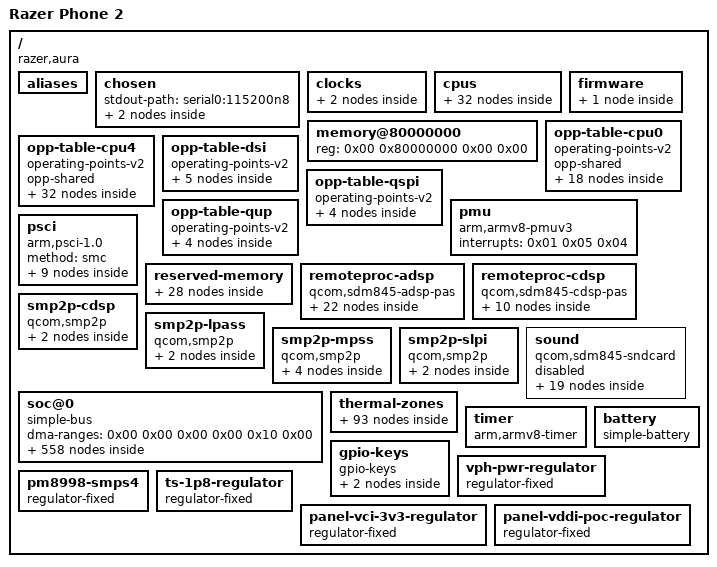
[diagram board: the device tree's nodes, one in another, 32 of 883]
/dts-v1/;

/ {
	interrupt-parent = <0x01>;
	#address-cells = <0x02>;
	#size-cells = <0x02>;
	model = "Razer Phone 2";
	compatible = "razer,aura\0qcom,sdm845";
	chassis-type = "handset";
	qcom,msm-id = <0x141 0x20000>;
	qcom,board-id = <0x00 0x00>;

	aliases {
		i2c0 = "/soc@0/geniqup@8c0000/i2c@880000";
		i2c1 = "/soc@0/geniqup@8c0000/i2c@884000";
		i2c2 = "/soc@0/geniqup@8c0000/i2c@888000";
		i2c3 = "/soc@0/geniqup@8c0000/i2c@88c000";
		i2c4 = "/soc@0/geniqup@8c0000/i2c@890000";
		i2c5 = "/soc@0/geniqup@8c0000/i2c@894000";
		i2c6 = "/soc@0/geniqup@8c0000/i2c@898000";
		i2c7 = "/soc@0/geniqup@8c0000/i2c@89c000";
		i2c8 = "/soc@0/geniqup@ac0000/i2c@a80000";
		i2c9 = "/soc@0/geniqup@ac0000/i2c@a84000";
		i2c10 = "/soc@0/geniqup@ac0000/i2c@a88000";
		i2c11 = "/soc@0/geniqup@ac0000/i2c@a8c000";
		i2c12 = "/soc@0/geniqup@ac0000/i2c@a90000";
		i2c13 = "/soc@0/geniqup@ac0000/i2c@a94000";
		i2c14 = "/soc@0/geniqup@ac0000/i2c@a98000";
		i2c15 = "/soc@0/geniqup@ac0000/i2c@a9c000";
		spi0 = "/soc@0/geniqup@8c0000/spi@880000";
		spi1 = "/soc@0/geniqup@8c0000/spi@884000";
		spi2 = "/soc@0/geniqup@8c0000/spi@888000";
		spi3 = "/soc@0/geniqup@8c0000/spi@88c000";
		spi4 = "/soc@0/geniqup@8c0000/spi@890000";
		spi5 = "/soc@0/geniqup@8c0000/spi@894000";
		spi6 = "/soc@0/geniqup@8c0000/spi@898000";
		spi7 = "/soc@0/geniqup@8c0000/spi@89c000";
		spi8 = "/soc@0/geniqup@ac0000/spi@a80000";
		spi9 = "/soc@0/geniqup@ac0000/spi@a84000";
		spi10 = "/soc@0/geniqup@ac0000/spi@a88000";
		spi11 = "/soc@0/geniqup@ac0000/spi@a8c000";
		spi12 = "/soc@0/geniqup@ac0000/spi@a90000";
		spi13 = "/soc@0/geniqup@ac0000/spi@a94000";
		spi14 = "/soc@0/geniqup@ac0000/spi@a98000";
		spi15 = "/soc@0/geniqup@ac0000/spi@a9c000";
		serial0 = "/soc@0/geniqup@ac0000/serial@a84000";
		serial1 = "/soc@0/geniqup@8c0000/serial@898000";
	};

	chosen {
		#address-cells = <0x02>;
		#size-cells = <0x02>;
		ranges;
		stdout-path = "serial0:115200n8";

		framebuffer@9d400000 {
			compatible = "simple-framebuffer";
			reg = <0x00 0x9d400000 0x00 0xf00000>;
			width = <0x5a0>;
			height = <0xa00>;
			stride = <0x1680>;
			format = "a8r8g8b8";
			panel = <0x02>;

			fb-panel {
				width-mm = <0x47>;
				height-mm = <0x7e>;
				phandle = <0x02>;
			};
		};
	};

	clocks {

		xo-board {
			compatible = "fixed-clock";
			#clock-cells = <0x00>;
			clock-frequency = <0x249f000>;
			clock-output-names = "xo_board";
			phandle = <0xf2>;
		};

		sleep-clk {
			compatible = "fixed-clock";
			#clock-cells = <0x00>;
			clock-frequency = <0x7ffc>;
			phandle = <0x36>;
		};
	};

	cpus {
		#address-cells = <0x02>;
		#size-cells = <0x00>;

		cpu@0 {
			device_type = "cpu";
			compatible = "qcom,kryo385";
			reg = <0x00 0x00>;
			clocks = <0x03 0x00>;
			enable-method = "psci";
			capacity-dmips-mhz = <0x263>;
			dynamic-power-coefficient = <0x9a>;
			qcom,freq-domain = <0x03 0x00>;
			operating-points-v2 = <0x04>;
			interconnects = <0x05 0x00 0x03 0x06 0x0e 0x03 0x07 0x00 0x07 0x01>;
			power-domains = <0x08>;
			power-domain-names = "psci";
			#cooling-cells = <0x02>;
			next-level-cache = <0x09>;
			phandle = <0x1a>;

			l2-cache {
				compatible = "cache";
				cache-level = <0x02>;
				cache-unified;
				next-level-cache = <0x0a>;
				phandle = <0x09>;

				l3-cache {
					compatible = "cache";
					cache-level = <0x03>;
					cache-unified;
					phandle = <0x0a>;
				};
			};
		};

		cpu@100 {
			device_type = "cpu";
			compatible = "qcom,kryo385";
			reg = <0x00 0x100>;
			clocks = <0x03 0x00>;
			enable-method = "psci";
			capacity-dmips-mhz = <0x263>;
			dynamic-power-coefficient = <0x9a>;
			qcom,freq-domain = <0x03 0x00>;
			operating-points-v2 = <0x04>;
			interconnects = <0x05 0x00 0x03 0x06 0x0e 0x03 0x07 0x00 0x07 0x01>;
			power-domains = <0x0b>;
			power-domain-names = "psci";
			#cooling-cells = <0x02>;
			next-level-cache = <0x0c>;
			phandle = <0x1b>;

			l2-cache {
				compatible = "cache";
				cache-level = <0x02>;
				cache-unified;
				next-level-cache = <0x0a>;
				phandle = <0x0c>;
			};
		};

		cpu@200 {
			device_type = "cpu";
			compatible = "qcom,kryo385";
			reg = <0x00 0x200>;
			clocks = <0x03 0x00>;
			enable-method = "psci";
			capacity-dmips-mhz = <0x263>;
			dynamic-power-coefficient = <0x9a>;
			qcom,freq-domain = <0x03 0x00>;
			operating-points-v2 = <0x04>;
			interconnects = <0x05 0x00 0x03 0x06 0x0e 0x03 0x07 0x00 0x07 0x01>;
			power-domains = <0x0d>;
			power-domain-names = "psci";
			#cooling-cells = <0x02>;
			next-level-cache = <0x0e>;
			phandle = <0x1c>;

			l2-cache {
				compatible = "cache";
				cache-level = <0x02>;
				cache-unified;
				next-level-cache = <0x0a>;
				phandle = <0x0e>;
			};
		};

		cpu@300 {
			device_type = "cpu";
			compatible = "qcom,kryo385";
			reg = <0x00 0x300>;
			clocks = <0x03 0x00>;
			enable-method = "psci";
			capacity-dmips-mhz = <0x263>;
			dynamic-power-coefficient = <0x9a>;
			qcom,freq-domain = <0x03 0x00>;
			operating-points-v2 = <0x04>;
			interconnects = <0x05 0x00 0x03 0x06 0x0e 0x03 0x07 0x00 0x07 0x01>;
			#cooling-cells = <0x02>;
			power-domains = <0x0f>;
			power-domain-names = "psci";
			next-level-cache = <0x10>;
			phandle = <0x1d>;

			l2-cache {
				compatible = "cache";
				cache-level = <0x02>;
				cache-unified;
				next-level-cache = <0x0a>;
				phandle = <0x10>;
			};
		};

		cpu@400 {
			device_type = "cpu";
			compatible = "qcom,kryo385";
			reg = <0x00 0x400>;
			clocks = <0x03 0x01>;
			enable-method = "psci";
			capacity-dmips-mhz = <0x400>;
			dynamic-power-coefficient = <0x1ba>;
			qcom,freq-domain = <0x03 0x01>;
			operating-points-v2 = <0x11>;
			interconnects = <0x05 0x00 0x03 0x06 0x0e 0x03 0x07 0x00 0x07 0x01>;
			power-domains = <0x12>;
			power-domain-names = "psci";
			#cooling-cells = <0x02>;
			next-level-cache = <0x13>;
			phandle = <0x1e>;

			l2-cache {
				compatible = "cache";
				cache-level = <0x02>;
				cache-unified;
				next-level-cache = <0x0a>;
				phandle = <0x13>;
			};
		};

		cpu@500 {
			device_type = "cpu";
			compatible = "qcom,kryo385";
			reg = <0x00 0x500>;
			clocks = <0x03 0x01>;
			enable-method = "psci";
			capacity-dmips-mhz = <0x400>;
			dynamic-power-coefficient = <0x1ba>;
			qcom,freq-domain = <0x03 0x01>;
			operating-points-v2 = <0x11>;
			interconnects = <0x05 0x00 0x03 0x06 0x0e 0x03 0x07 0x00 0x07 0x01>;
			power-domains = <0x14>;
			power-domain-names = "psci";
			#cooling-cells = <0x02>;
			next-level-cache = <0x15>;
			phandle = <0x1f>;

			l2-cache {
				compatible = "cache";
				cache-level = <0x02>;
				cache-unified;
				next-level-cache = <0x0a>;
				phandle = <0x15>;
			};
		};

		cpu@600 {
			device_type = "cpu";
			compatible = "qcom,kryo385";
			reg = <0x00 0x600>;
			clocks = <0x03 0x01>;
			enable-method = "psci";
			capacity-dmips-mhz = <0x400>;
			dynamic-power-coefficient = <0x1ba>;
			qcom,freq-domain = <0x03 0x01>;
			operating-points-v2 = <0x11>;
			interconnects = <0x05 0x00 0x03 0x06 0x0e 0x03 0x07 0x00 0x07 0x01>;
			power-domains = <0x16>;
			power-domain-names = "psci";
			#cooling-cells = <0x02>;
			next-level-cache = <0x17>;
			phandle = <0x20>;

			l2-cache {
				compatible = "cache";
				cache-level = <0x02>;
				cache-unified;
				next-level-cache = <0x0a>;
				phandle = <0x17>;
			};
		};

		cpu@700 {
			device_type = "cpu";
			compatible = "qcom,kryo385";
			reg = <0x00 0x700>;
			clocks = <0x03 0x01>;
			enable-method = "psci";
			capacity-dmips-mhz = <0x400>;
			dynamic-power-coefficient = <0x1ba>;
			qcom,freq-domain = <0x03 0x01>;
			operating-points-v2 = <0x11>;
			interconnects = <0x05 0x00 0x03 0x06 0x0e 0x03 0x07 0x00 0x07 0x01>;
			power-domains = <0x18>;
			power-domain-names = "psci";
			#cooling-cells = <0x02>;
			next-level-cache = <0x19>;
			phandle = <0x21>;

			l2-cache {
				compatible = "cache";
				cache-level = <0x02>;
				cache-unified;
				next-level-cache = <0x0a>;
				phandle = <0x19>;
			};
		};

		cpu-map {

			cluster0 {

				core0 {
					cpu = <0x1a>;
				};

				core1 {
					cpu = <0x1b>;
				};

				core2 {
					cpu = <0x1c>;
				};

				core3 {
					cpu = <0x1d>;
				};

				core4 {
					cpu = <0x1e>;
				};

				core5 {
					cpu = <0x1f>;
				};

				core6 {
					cpu = <0x20>;
				};

				core7 {
					cpu = <0x21>;
				};
			};
		};

		idle-states {
			entry-method = "psci";

			cpu-sleep-0-0 {
				compatible = "arm,idle-state";
				idle-state-name = "little-rail-power-collapse";
				arm,psci-suspend-param = <0x40000004>;
				entry-latency-us = <0x15e>;
				exit-latency-us = <0x1cd>;
				min-residency-us = <0x762>;
				local-timer-stop;
				phandle = <0x28>;
			};

			cpu-sleep-1-0 {
				compatible = "arm,idle-state";
				idle-state-name = "big-rail-power-collapse";
				arm,psci-suspend-param = <0x40000004>;
				entry-latency-us = <0x108>;
				exit-latency-us = <0x26d>;
				min-residency-us = <0x3b8>;
				local-timer-stop;
				phandle = <0x29>;
			};
		};

		domain-idle-states {

			cluster-sleep-0 {
				compatible = "domain-idle-state";
				arm,psci-suspend-param = <0x4100c244>;
				entry-latency-us = <0xcbf>;
				exit-latency-us = <0x19a2>;
				min-residency-us = <0x2703>;
				phandle = <0x2a>;
			};
		};
	};

	firmware {

		scm {
			compatible = "qcom,scm-sdm845\0qcom,scm";
		};
	};

	memory@80000000 {
		device_type = "memory";
		reg = <0x00 0x80000000 0x00 0x00>;
	};

	opp-table-cpu0 {
		compatible = "operating-points-v2";
		opp-shared;
		phandle = <0x04>;

		opp-300000000 {
			opp-hz = <0x00 0x11e1a300>;
			opp-peak-kBps = "\0\f5\0\0I>";
		};

		opp-403200000 {
			opp-hz = <0x00 0x18085800>;
			opp-peak-kBps = "\0\f5\0\0I>";
		};

		opp-480000000 {
			opp-hz = <0x00 0x1c9c3800>;
			opp-peak-kBps = "\0\f5\0\0bp";
		};

		opp-576000000 {
			opp-hz = <0x00 0x22551000>;
			opp-peak-kBps = "\0\f5\0\0bp";
		};

		opp-652800000 {
			opp-hz = <0x00 0x26e8f000>;
			opp-peak-kBps = "\0\f5\0\0u0";
		};

		opp-748800000 {
			opp-hz = <0x00 0x2ca1c800>;
			opp-peak-kBps = <0x1b86e0 0x8ca000>;
		};

		opp-825600000 {
			opp-hz = <0x00 0x3135a800>;
			opp-peak-kBps = <0x1b86e0 0x8ca000>;
		};

		opp-902400000 {
			opp-hz = <0x00 0x35c98800>;
			opp-peak-kBps = <0x1b86e0 0x9f6000>;
		};

		opp-979200000 {
			opp-hz = <0x00 0x3a5d6800>;
			opp-peak-kBps = <0x1b86e0 0xb6d000>;
		};

		opp-1056000000 {
			opp-hz = <0x00 0x3ef14800>;
			opp-peak-kBps = <0x1b86e0 0xb6d000>;
		};

		opp-1132800000 {
			opp-hz = <0x00 0x43852800>;
			opp-peak-kBps = <0x2162e0 0xce4000>;
		};

		opp-1228800000 {
			opp-hz = <0x00 0x493e0000>;
			opp-peak-kBps = <0x2162e0 0xe5b000>;
		};

		opp-1324800000 {
			opp-hz = <0x00 0x4ef6d800>;
			opp-peak-kBps = <0x2162e0 0xfd2000>;
		};

		opp-1420800000 {
			opp-hz = <0x00 0x54afb000>;
			opp-peak-kBps = <0x2ee000 0x1149000>;
		};

		opp-1516800000 {
			opp-hz = <0x00 0x5a688800>;
			opp-peak-kBps = <0x2ee000 0x1275000>;
		};

		opp-1612800000 {
			opp-hz = <0x00 0x60216000>;
			opp-peak-kBps = <0x3e12a0 0x1275000>;
		};

		opp-1689600000 {
			opp-hz = <0x00 0x64b54000>;
			opp-peak-kBps = <0x3e12a0 0x13ec000>;
		};

		opp-1766400000 {
			opp-hz = <0x00 0x69492000>;
			opp-peak-kBps = <0x3e12a0 0x1563000>;
		};
	};

	opp-table-cpu4 {
		compatible = "operating-points-v2";
		opp-shared;
		phandle = <0x11>;

		opp-300000000 {
			opp-hz = <0x00 0x11e1a300>;
			opp-peak-kBps = "\0\f5\0\0I>";
		};

		opp-403200000 {
			opp-hz = <0x00 0x18085800>;
			opp-peak-kBps = "\0\f5\0\0I>";
		};

		opp-480000000 {
			opp-hz = <0x00 0x1c9c3800>;
			opp-peak-kBps = <0x1b86e0 0x493e00>;
		};

		opp-576000000 {
			opp-hz = <0x00 0x22551000>;
			opp-peak-kBps = <0x1b86e0 0x493e00>;
		};

		opp-652800000 {
			opp-hz = <0x00 0x26e8f000>;
			opp-peak-kBps = <0x1b86e0 0x493e00>;
		};

		opp-748800000 {
			opp-hz = <0x00 0x2ca1c800>;
			opp-peak-kBps = <0x1b86e0 0x493e00>;
		};

		opp-825600000 {
			opp-hz = <0x00 0x3135a800>;
			opp-peak-kBps = <0x2162e0 0x8ca000>;
		};

		opp-902400000 {
			opp-hz = <0x00 0x35c98800>;
			opp-peak-kBps = <0x2162e0 0x8ca000>;
		};

		opp-979200000 {
			opp-hz = <0x00 0x3a5d6800>;
			opp-peak-kBps = <0x2162e0 0x8ca000>;
		};

		opp-1056000000 {
			opp-hz = <0x00 0x3ef14800>;
			opp-peak-kBps = <0x2ee000 0x8ca000>;
		};

		opp-1132800000 {
			opp-hz = <0x00 0x43852800>;
			opp-peak-kBps = <0x2ee000 0xb6d000>;
		};

		opp-1209600000 {
			opp-hz = <0x00 0x48190800>;
			opp-peak-kBps = <0x3e12a0 0xb6d000>;
		};

		opp-1286400000 {
			opp-hz = <0x00 0x4cace800>;
			opp-peak-kBps = <0x3e12a0 0xb6d000>;
		};

		opp-1363200000 {
			opp-hz = <0x00 0x5140c800>;
			opp-peak-kBps = <0x3e12a0 0xe5b000>;
		};

		opp-1459200000 {
			opp-hz = <0x00 0x56f9a000>;
			opp-peak-kBps = <0x3e12a0 0xe5b000>;
		};

		opp-1536000000 {
			opp-hz = <0x00 0x5b8d8000>;
			opp-peak-kBps = <0x5294a0 0xe5b000>;
		};

		opp-1612800000 {
			opp-hz = <0x00 0x60216000>;
			opp-peak-kBps = <0x5294a0 0xe5b000>;
		};

		opp-1689600000 {
			opp-hz = <0x00 0x64b54000>;
			opp-peak-kBps = <0x5294a0 0x1275000>;
		};

		opp-1766400000 {
			opp-hz = <0x00 0x69492000>;
			opp-peak-kBps = <0x5ee8e0 0x1275000>;
		};

		opp-1843200000 {
			opp-hz = <0x00 0x6ddd0000>;
			opp-peak-kBps = <0x5ee8e0 0x1275000>;
		};

		opp-1920000000 {
			opp-hz = <0x00 0x7270e000>;
			opp-peak-kBps = <0x6e1b80 0x1275000>;
		};

		opp-1996800000 {
			opp-hz = <0x00 0x7704c000>;
			opp-peak-kBps = <0x6e1b80 0x13ec000>;
		};

		opp-2092800000 {
			opp-hz = <0x00 0x7cbd9800>;
			opp-peak-kBps = <0x6e1b80 0x13ec000>;
		};

		opp-2169600000 {
			opp-hz = <0x00 0x81517800>;
			opp-peak-kBps = <0x6e1b80 0x13ec000>;
		};

		opp-2246400000 {
			opp-hz = <0x00 0x85e55800>;
			opp-peak-kBps = <0x6e1b80 0x13ec000>;
		};

		opp-2323200000 {
			opp-hz = <0x00 0x8a793800>;
			opp-peak-kBps = <0x6e1b80 0x13ec000>;
		};

		opp-2400000000 {
			opp-hz = <0x00 0x8f0d1800>;
			opp-peak-kBps = <0x6e1b80 0x1563000>;
		};

		opp-2476800000 {
			opp-hz = <0x00 0x93a0f800>;
			opp-peak-kBps = <0x6e1b80 0x1563000>;
		};

		opp-2553600000 {
			opp-hz = <0x00 0x9834d800>;
			opp-peak-kBps = <0x6e1b80 0x1563000>;
		};

		opp-2649600000 {
			opp-hz = <0x00 0x9dedb000>;
			opp-peak-kBps = <0x6e1b80 0x1563000>;
		};

		opp-2745600000 {
			opp-hz = <0x00 0xa3a68800>;
			opp-peak-kBps = <0x6e1b80 0x1851000>;
		};

		opp-2803200000 {
			opp-hz = <0x00 0xa7157000>;
			opp-peak-kBps = <0x6e1b80 0x1851000>;
		};
	};

	opp-table-dsi {
		compatible = "operating-points-v2";
		phandle = <0xda>;

		opp-19200000 {
			opp-hz = <0x00 0x124f800>;
			required-opps = <0x22>;
		};

		opp-180000000 {
			opp-hz = <0x00 0xaba9500>;
			required-opps = <0x23>;
		};

		opp-275000000 {
			opp-hz = <0x00 0x10642ac0>;
			required-opps = <0x24>;
		};

		opp-328580000 {
			opp-hz = <0x00 0x1395bba0>;
			required-opps = <0x25>;
		};

		opp-358000000 {
			opp-hz = <0x00 0x1556a580>;
			required-opps = <0x26>;
		};
	};

	opp-table-qspi {
		compatible = "operating-points-v2";
		phandle = <0xb5>;

		opp-19200000 {
			opp-hz = <0x00 0x124f800>;
			required-opps = <0x22>;
		};

		opp-100000000 {
			opp-hz = <0x00 0x5f5e100>;
			required-opps = <0x23>;
		};

		opp-150000000 {
			opp-hz = <0x00 0x8f0d180>;
			required-opps = <0x24>;
		};

		opp-300000000 {
			opp-hz = <0x00 0x11e1a300>;
			required-opps = <0x26>;
		};
	};

	opp-table-qup {
		compatible = "operating-points-v2";
		phandle = <0x3e>;

		opp-50000000 {
			opp-hz = <0x00 0x2faf080>;
			required-opps = <0x22>;
		};

		opp-75000000 {
			opp-hz = <0x00 0x47868c0>;
			required-opps = <0x23>;
		};

		opp-100000000 {
			opp-hz = <0x00 0x5f5e100>;
			required-opps = <0x24>;
		};

		opp-128000000 {
			opp-hz = <0x00 0x7a12000>;
			required-opps = <0x26>;
		};
	};

	pmu {
		compatible = "arm,armv8-pmuv3";
		interrupts = <0x01 0x05 0x04>;
	};

	psci {
		compatible = "arm,psci-1.0";
		method = "smc";

		power-domain-cpu0 {
			#power-domain-cells = <0x00>;
			power-domains = <0x27>;
			domain-idle-states = <0x28>;
			phandle = <0x08>;
		};

		power-domain-cpu1 {
			#power-domain-cells = <0x00>;
			power-domains = <0x27>;
			domain-idle-states = <0x28>;
			phandle = <0x0b>;
		};

		power-domain-cpu2 {
			#power-domain-cells = <0x00>;
			power-domains = <0x27>;
			domain-idle-states = <0x28>;
			phandle = <0x0d>;
		};

		power-domain-cpu3 {
			#power-domain-cells = <0x00>;
			power-domains = <0x27>;
			domain-idle-states = <0x28>;
			phandle = <0x0f>;
		};

		power-domain-cpu4 {
			#power-domain-cells = <0x00>;
			power-domains = <0x27>;
			domain-idle-states = <0x29>;
			phandle = <0x12>;
		};

		power-domain-cpu5 {
			#power-domain-cells = <0x00>;
			power-domains = <0x27>;
			domain-idle-states = <0x29>;
			phandle = <0x14>;
		};

		power-domain-cpu6 {
			#power-domain-cells = <0x00>;
			power-domains = <0x27>;
			domain-idle-states = <0x29>;
			phandle = <0x16>;
		};

		power-domain-cpu7 {
			#power-domain-cells = <0x00>;
			power-domains = <0x27>;
			domain-idle-states = <0x29>;
			phandle = <0x18>;
		};

		power-domain-cluster {
			#power-domain-cells = <0x00>;
			domain-idle-states = <0x2a>;
			phandle = <0x27>;
		};
	};

	reserved-memory {
		#address-cells = <0x02>;
		#size-cells = <0x02>;
		ranges;

		hyp-mem@85700000 {
			reg = <0x00 0x85700000 0x00 0x600000>;
			no-map;
		};

		xbl-mem@85e00000 {
			reg = <0x00 0x85e00000 0x00 0x100000>;
			no-map;
		};

		aop-mem@85fc0000 {
			reg = <0x00 0x85fc0000 0x00 0x20000>;
			no-map;
		};

		aop-cmd-db-mem@85fe0000 {
			compatible = "qcom,cmd-db";
			reg = <0x00 0x85fe0000 0x00 0x20000>;
			no-map;
		};

		smem@86000000 {
			compatible = "qcom,smem";
			reg = <0x00 0x86000000 0x00 0x200000>;
			no-map;
			hwlocks = <0x2b 0x03>;
		};

		tz@86200000 {
			reg = <0x00 0x86200000 0x00 0x2d00000>;
			no-map;
		};

		qseecom@8ab00000 {
			reg = <0x00 0x8ab00000 0x00 0x1400000>;
			no-map;
		};

		camera-mem@8bf00000 {
			reg = <0x00 0x8bf00000 0x00 0x500000>;
			no-map;
		};

		ipa-fw@8c400000 {
			reg = <0x00 0x8c400000 0x00 0x10000>;
			no-map;
			phandle = <0x85>;
		};

		ipa-gsi@8c410000 {
			reg = <0x00 0x8c410000 0x00 0x5000>;
			no-map;
		};

		gpu@8c415000 {
			reg = <0x00 0x8c415000 0x00 0x2000>;
			no-map;
		};

		adsp@8c500000 {
			reg = <0x00 0x8c500000 0x00 0x1a00000>;
			no-map;
			phandle = <0x2e>;
		};

		wlan-msa@8df00000 {
			reg = <0x00 0x8df00000 0x00 0x100000>;
			no-map;
			phandle = <0xfb>;
		};

		mpss@8e000000 {
			reg = <0x00 0x8e000000 0x00 0x7800000>;
			no-map;
			phandle = <0x8e>;
		};

		venus@95800000 {
			reg = <0x00 0x95800000 0x00 0x500000>;
			no-map;
			phandle = <0xc7>;
		};

		cdsp@95d00000 {
			reg = <0x00 0x95d00000 0x00 0x800000>;
			no-map;
			phandle = <0x34>;
		};

		mba@96500000 {
			reg = <0x00 0x96500000 0x00 0x200000>;
			no-map;
			phandle = <0x8d>;
		};

		slpi@96700000 {
			reg = <0x00 0x96700000 0x00 0x1400000>;
			no-map;
			phandle = <0x91>;
		};

		spss@97b00000 {
			reg = <0x00 0x97b00000 0x00 0x100000>;
			no-map;
		};

		mpss-metadata {
			alloc-ranges = <0x00 0xa0000000 0x00 0x20000000>;
			size = <0x00 0x4000>;
			no-map;
			phandle = <0x8f>;
		};

		framebuffer@9d400000 {
			reg = <0x00 0x9d400000 0x00 0x2400000>;
			no-map;
		};

		fastrpc {
			compatible = "shared-dma-pool";
			alloc-ranges = <0x00 0x00 0x00 0xffffffff>;
			alignment = <0x00 0x400000>;
			size = <0x00 0x1000000>;
			reusable;
			phandle = <0x93>;
		};

		rmtfs-mem@f5b00000 {
			compatible = "qcom,rmtfs-mem";
			reg = <0x00 0xf5b00000 0x00 0x202000>;
			no-map;
			qcom,client-id = <0x01>;
			qcom,vmid = <0x0f>;
			qcom,use-guard-pages;
		};

		removed-region@88f00000 {
			no-map;
			reg = <0x00 0x88f00000 0x00 0x1c00000>;
		};

		ramoops@ac300000 {
			compatible = "ramoops";
			reg = <0x00 0xac300000 0x00 0x400000>;
			record-size = <0x40000>;
			console-size = <0x40000>;
			ftrace-size = <0x40000>;
			pmsg-size = <0x200000>;
			ecc-size = <0x10>;
		};

		fih-nv@af000000 {
			compatible = "removed-dma-pool";
			no-map;
			reg = <0x00 0xaf000000 0x00 0x800000>;
			phandle = <0x8c>;
		};

		fih-pstore@af800000 {
			compatible = "removed-dma-pool";
			no-map;
			reg = <0x00 0xaf800000 0x00 0x200000>;
		};

		fih@afa00000 {
			compatible = "removed-dma-pool";
			no-map;
			reg = <0x00 0xafa00000 0x00 0x600000>;
		};
	};

	remoteproc-adsp {
		compatible = "qcom,sdm845-adsp-pas";
		interrupts-extended = <0x01 0x00 0xa2 0x01 0x2c 0x00 0x01 0x2c 0x01 0x01 0x2c 0x02 0x01 0x2c 0x03 0x01>;
		interrupt-names = "wdog\0fatal\0ready\0handover\0stop-ack";
		clocks = <0x2d 0x00>;
		clock-names = "xo";
		memory-region = <0x2e>;
		qcom,qmp = <0x2f>;
		qcom,smem-states = <0x30 0x00>;
		qcom,smem-state-names = "stop";
		status = "okay";
		firmware-name = "qcom/sdm845/Razer/aura/adsp.mbn";

		glink-edge {
			interrupts = <0x00 0x9c 0x01>;
			label = "lpass";
			qcom,remote-pid = <0x02>;
			mboxes = <0x31 0x08>;

			apr {
				compatible = "qcom,apr-v2";
				qcom,glink-channels = "apr_audio_svc";
				qcom,domain = <0x04>;
				#address-cells = <0x01>;
				#size-cells = <0x00>;
				qcom,intents = <0x200 0x14>;

				service@3 {
					reg = <0x03>;
					compatible = "qcom,q6core";
					qcom,protection-domain = "avs/audio\0msm/adsp/audio_pd";
				};

				service@4 {
					compatible = "qcom,q6afe";
					reg = <0x04>;
					qcom,protection-domain = "avs/audio\0msm/adsp/audio_pd";

					dais {
						compatible = "qcom,q6afe-dais";
						#address-cells = <0x01>;
						#size-cells = <0x00>;
						#sound-dai-cells = <0x01>;
						phandle = <0x102>;

						dai@22 {
							reg = <0x16>;
							qcom,sd-lines = <0x01>;
						};

						dai@23 {
							reg = <0x17>;
							qcom,sd-lines = <0x00>;
						};
					};
				};

				service@7 {
					compatible = "qcom,q6asm";
					reg = <0x07>;
					qcom,protection-domain = "avs/audio\0msm/adsp/audio_pd";

					dais {
						compatible = "qcom,q6asm-dais";
						#address-cells = <0x01>;
						#size-cells = <0x00>;
						#sound-dai-cells = <0x01>;
						iommus = <0x32 0x1821 0x00>;
						phandle = <0x101>;

						dai@0 {
							reg = <0x00>;
						};

						dai@1 {
							reg = <0x01>;
						};

						dai@2 {
							reg = <0x02>;
						};

						dai@3 {
							reg = <0x03>;
						};
					};
				};

				service@8 {
					compatible = "qcom,q6adm";
					reg = <0x08>;
					qcom,protection-domain = "avs/audio\0msm/adsp/audio_pd";

					routing {
						compatible = "qcom,q6adm-routing";
						#sound-dai-cells = <0x00>;
						phandle = <0x103>;
					};
				};

				apr-service@9 {
					compatible = "qcom,q6mvm";
					reg = <0x09>;
					qcom,protection-domain = "avs/audio\0msm/adsp/audio_pd";
					status = "disabled";

					dais {
						compatible = "qcom,q6voice-dais";
						#address-cells = <0x01>;
						#size-cells = <0x00>;
						#sound-dai-cells = <0x01>;
					};
				};

				apr-service@a {
					compatible = "qcom,q6cvs";
					reg = <0x0a>;
					qcom,protection-domain = "avs/audio\0msm/adsp/audio_pd";
					status = "disabled";
				};

				apr-service@b {
					compatible = "qcom,q6cvp";
					reg = <0x0b>;
					qcom,protection-domain = "avs/audio\0msm/adsp/audio_pd";
					status = "disabled";
				};
			};

			fastrpc {
				compatible = "qcom,fastrpc";
				qcom,glink-channels = "fastrpcglink-apps-dsp";
				label = "adsp";
				qcom,non-secure-domain;
				#address-cells = <0x01>;
				#size-cells = <0x00>;

				compute-cb@3 {
					compatible = "qcom,fastrpc-compute-cb";
					reg = <0x03>;
					iommus = <0x32 0x1823 0x00>;
				};

				compute-cb@4 {
					compatible = "qcom,fastrpc-compute-cb";
					reg = <0x04>;
					iommus = <0x32 0x1824 0x00>;
				};
			};
		};
	};

	remoteproc-cdsp {
		compatible = "qcom,sdm845-cdsp-pas";
		interrupts-extended = <0x01 0x00 0x242 0x01 0x33 0x00 0x01 0x33 0x01 0x01 0x33 0x02 0x01 0x33 0x03 0x01>;
		interrupt-names = "wdog\0fatal\0ready\0handover\0stop-ack";
		clocks = <0x2d 0x00>;
		clock-names = "xo";
		memory-region = <0x34>;
		qcom,qmp = <0x2f>;
		qcom,smem-states = <0x35 0x00>;
		qcom,smem-state-names = "stop";
		status = "okay";
		firmware-name = "qcom/sdm845/Razer/aura/cdsp.mbn";

		glink-edge {
			interrupts = <0x00 0x23e 0x01>;
			label = "turing";
			qcom,remote-pid = <0x05>;
			mboxes = <0x31 0x04>;

			fastrpc {
				compatible = "qcom,fastrpc";
				qcom,glink-channels = "fastrpcglink-apps-dsp";
				label = "cdsp";
				qcom,non-secure-domain;
				#address-cells = <0x01>;
				#size-cells = <0x00>;

				compute-cb@1 {
					compatible = "qcom,fastrpc-compute-cb";
					reg = <0x01>;
					iommus = <0x32 0x1401 0x30>;
				};

				compute-cb@2 {
					compatible = "qcom,fastrpc-compute-cb";
					reg = <0x02>;
					iommus = <0x32 0x1402 0x30>;
				};

				compute-cb@3 {
					compatible = "qcom,fastrpc-compute-cb";
					reg = <0x03>;
					iommus = <0x32 0x1403 0x30>;
				};

				compute-cb@4 {
					compatible = "qcom,fastrpc-compute-cb";
					reg = <0x04>;
					iommus = <0x32 0x1404 0x30>;
				};

				compute-cb@5 {
					compatible = "qcom,fastrpc-compute-cb";
					reg = <0x05>;
					iommus = <0x32 0x1405 0x30>;
				};

				compute-cb@6 {
					compatible = "qcom,fastrpc-compute-cb";
					reg = <0x06>;
					iommus = <0x32 0x1406 0x30>;
				};

				compute-cb@7 {
					compatible = "qcom,fastrpc-compute-cb";
					reg = <0x07>;
					iommus = <0x32 0x1407 0x30>;
				};

				compute-cb@8 {
					compatible = "qcom,fastrpc-compute-cb";
					reg = <0x08>;
					iommus = <0x32 0x1408 0x30>;
				};
			};
		};
	};

	smp2p-cdsp {
		compatible = "qcom,smp2p";
		qcom,smem = <0x5e 0x1b0>;
		interrupts = <0x00 0x240 0x01>;
		mboxes = <0x31 0x06>;
		qcom,local-pid = <0x00>;
		qcom,remote-pid = <0x05>;

		master-kernel {
			qcom,entry-name = "master-kernel";
			#qcom,smem-state-cells = <0x01>;
			phandle = <0x35>;
		};

		slave-kernel {
			qcom,entry-name = "slave-kernel";
			interrupt-controller;
			#interrupt-cells = <0x02>;
			phandle = <0x33>;
		};
	};

	smp2p-lpass {
		compatible = "qcom,smp2p";
		qcom,smem = <0x1bb 0x1ad>;
		interrupts = <0x00 0x9e 0x01>;
		mboxes = <0x31 0x0a>;
		qcom,local-pid = <0x00>;
		qcom,remote-pid = <0x02>;

		master-kernel {
			qcom,entry-name = "master-kernel";
			#qcom,smem-state-cells = <0x01>;
			phandle = <0x30>;
		};

		slave-kernel {
			qcom,entry-name = "slave-kernel";
			interrupt-controller;
			#interrupt-cells = <0x02>;
			phandle = <0x2c>;
		};
	};

	smp2p-mpss {
		compatible = "qcom,smp2p";
		qcom,smem = <0x1b3 0x1ac>;
		interrupts = <0x00 0x1c3 0x01>;
		mboxes = <0x31 0x0e>;
		qcom,local-pid = <0x00>;
		qcom,remote-pid = <0x01>;

		master-kernel {
			qcom,entry-name = "master-kernel";
			#qcom,smem-state-cells = <0x01>;
			phandle = <0x88>;
		};

		slave-kernel {
			qcom,entry-name = "slave-kernel";
			interrupt-controller;
			#interrupt-cells = <0x02>;
			phandle = <0x87>;
		};

		ipa-ap-to-modem {
			qcom,entry-name = "ipa";
			#qcom,smem-state-cells = <0x01>;
			phandle = <0x84>;
		};

		ipa-modem-to-ap {
			qcom,entry-name = "ipa";
			interrupt-controller;
			#interrupt-cells = <0x02>;
			phandle = <0x82>;
		};
	};

	smp2p-slpi {
		compatible = "qcom,smp2p";
		qcom,smem = <0x1e1 0x1ae>;
		interrupts = <0x00 0xac 0x01>;
		mboxes = <0x31 0x1a>;
		qcom,local-pid = <0x00>;
		qcom,remote-pid = <0x03>;

		master-kernel {
			qcom,entry-name = "master-kernel";
			#qcom,smem-state-cells = <0x01>;
			phandle = <0x92>;
		};

		slave-kernel {
			qcom,entry-name = "slave-kernel";
			interrupt-controller;
			#interrupt-cells = <0x02>;
			phandle = <0x90>;
		};
	};

	soc@0 {
		#address-cells = <0x02>;
		#size-cells = <0x02>;
		ranges = <0x00 0x00 0x00 0x00 0x10 0x00>;
		dma-ranges = <0x00 0x00 0x00 0x00 0x10 0x00>;
		compatible = "simple-bus";

		clock-controller@100000 {
			compatible = "qcom,gcc-sdm845";
			reg = <0x00 0x100000 0x00 0x1f0000>;
			clocks = <0x2d 0x00 0x2d 0x01 0x36 0x37 0x38>;
			clock-names = "bi_tcxo\0bi_tcxo_ao\0sleep_clk\0pcie_0_pipe_clk\0pcie_1_pipe_clk";
			#clock-cells = <0x01>;
			#reset-cells = <0x01>;
			#power-domain-cells = <0x01>;
			power-domains = <0x39 0x03>;
			protected-clocks = <0xbc 0xbb 0xbd 0xbe 0xbf>;
			phandle = <0x3a>;
		};

		qfprom@784000 {
			compatible = "qcom,sdm845-qfprom\0qcom,qfprom";
			reg = <0x00 0x784000 0x00 0x8ff>;
			#address-cells = <0x01>;
			#size-cells = <0x01>;

			hstx-trim-primary@1eb {
				reg = <0x1eb 0x01>;
				bits = <0x01 0x04>;
				phandle = <0xba>;
			};

			hstx-trim-secondary@1eb {
				reg = <0x1eb 0x02>;
				bits = <0x06 0x04>;
				phandle = <0xbe>;
			};
		};

		rng@793000 {
			compatible = "qcom,prng-ee";
			reg = <0x00 0x793000 0x00 0x1000>;
			clocks = <0x3a 0x40>;
			clock-names = "core";
		};

		dma-controller@800000 {
			#dma-cells = <0x03>;
			compatible = "qcom,sdm845-gpi-dma";
			reg = <0x00 0x800000 0x00 0x60000>;
			interrupts = <0x00 0xf4 0x04 0x00 0xf5 0x04 0x00 0xf6 0x04 0x00 0xf7 0x04 0x00 0xf8 0x04 0x00 0xf9 0x04 0x00 0xfa 0x04 0x00 0xfb 0x04 0x00 0xfc 0x04 0x00 0xfd 0x04 0x00 0xfe 0x04 0x00 0xff 0x04 0x00 0x100 0x04>;
			dma-channels = <0x0d>;
			dma-channel-mask = <0xfa>;
			iommus = <0x32 0x16 0x00>;
			status = "disabled";
			phandle = <0x3f>;
		};

		geniqup@8c0000 {
			compatible = "qcom,geni-se-qup";
			reg = <0x00 0x8c0000 0x00 0x6000>;
			clock-names = "m-ahb\0s-ahb";
			clocks = <0x3a 0x64 0x3a 0x65>;
			iommus = <0x32 0x03 0x00>;
			#address-cells = <0x02>;
			#size-cells = <0x02>;
			ranges;
			interconnects = <0x3b 0x0a 0x00 0x3c 0x1d 0x00>;
			interconnect-names = "qup-core";
			status = "okay";

			i2c@880000 {
				compatible = "qcom,geni-i2c";
				reg = <0x00 0x880000 0x00 0x4000>;
				clock-names = "se";
				clocks = <0x3a 0x44>;
				pinctrl-names = "default";
				pinctrl-0 = <0x3d>;
				interrupts = <0x00 0x259 0x04>;
				#address-cells = <0x01>;
				#size-cells = <0x00>;
				power-domains = <0x39 0x03>;
				operating-points-v2 = <0x3e>;
				interconnects = <0x3b 0x0a 0x00 0x3c 0x1d 0x00 0x05 0x00 0x00 0x3c 0x1d 0x00 0x3b 0x0a 0x00 0x06 0x0e 0x00>;
				interconnect-names = "qup-core\0qup-config\0qup-memory";
				dmas = <0x3f 0x00 0x00 0x03 0x3f 0x01 0x00 0x03>;
				dma-names = "tx\0rx";
				status = "disabled";
			};

			spi@880000 {
				compatible = "qcom,geni-spi";
				reg = <0x00 0x880000 0x00 0x4000>;
				clock-names = "se";
				clocks = <0x3a 0x44>;
				pinctrl-names = "default";
				pinctrl-0 = <0x40>;
				interrupts = <0x00 0x259 0x04>;
				#address-cells = <0x01>;
				#size-cells = <0x00>;
				interconnects = <0x3b 0x0a 0x00 0x3c 0x1d 0x00 0x05 0x00 0x00 0x3c 0x1d 0x00>;
				interconnect-names = "qup-core\0qup-config";
				dmas = <0x3f 0x00 0x00 0x01 0x3f 0x01 0x00 0x01>;
				dma-names = "tx\0rx";
				status = "disabled";
			};

			serial@880000 {
				compatible = "qcom,geni-uart";
				reg = <0x00 0x880000 0x00 0x4000>;
				clock-names = "se";
				clocks = <0x3a 0x44>;
				pinctrl-names = "default";
				pinctrl-0 = <0x41>;
				interrupts = <0x00 0x259 0x04>;
				power-domains = <0x39 0x03>;
				operating-points-v2 = <0x3e>;
				interconnects = <0x3b 0x0a 0x00 0x3c 0x1d 0x00 0x05 0x00 0x00 0x3c 0x1d 0x00>;
				interconnect-names = "qup-core\0qup-config";
				status = "disabled";
			};

			i2c@884000 {
				compatible = "qcom,geni-i2c";
				reg = <0x00 0x884000 0x00 0x4000>;
				clock-names = "se";
				clocks = <0x3a 0x46>;
				pinctrl-names = "default";
				pinctrl-0 = <0x42>;
				interrupts = <0x00 0x25a 0x04>;
				#address-cells = <0x01>;
				#size-cells = <0x00>;
				power-domains = <0x39 0x03>;
				operating-points-v2 = <0x3e>;
				interconnects = <0x3b 0x0a 0x00 0x3c 0x1d 0x00 0x05 0x00 0x00 0x3c 0x1d 0x00 0x3b 0x0a 0x00 0x06 0x0e 0x00>;
				interconnect-names = "qup-core\0qup-config\0qup-memory";
				dmas = <0x3f 0x00 0x01 0x03 0x3f 0x01 0x01 0x03>;
				dma-names = "tx\0rx";
				status = "disabled";
			};

			spi@884000 {
				compatible = "qcom,geni-spi";
				reg = <0x00 0x884000 0x00 0x4000>;
				clock-names = "se";
				clocks = <0x3a 0x46>;
				pinctrl-names = "default";
				pinctrl-0 = <0x43>;
				interrupts = <0x00 0x25a 0x04>;
				#address-cells = <0x01>;
				#size-cells = <0x00>;
				interconnects = <0x3b 0x0a 0x00 0x3c 0x1d 0x00 0x05 0x00 0x00 0x3c 0x1d 0x00>;
				interconnect-names = "qup-core\0qup-config";
				dmas = <0x3f 0x00 0x01 0x01 0x3f 0x01 0x01 0x01>;
				dma-names = "tx\0rx";
				status = "disabled";
			};

			serial@884000 {
				compatible = "qcom,geni-uart";
				reg = <0x00 0x884000 0x00 0x4000>;
				clock-names = "se";
				clocks = <0x3a 0x46>;
				pinctrl-names = "default";
				pinctrl-0 = <0x44>;
				interrupts = <0x00 0x25a 0x04>;
				power-domains = <0x39 0x03>;
				operating-points-v2 = <0x3e>;
				interconnects = <0x3b 0x0a 0x00 0x3c 0x1d 0x00 0x05 0x00 0x00 0x3c 0x1d 0x00>;
				interconnect-names = "qup-core\0qup-config";
				status = "disabled";
			};

			i2c@888000 {
				compatible = "qcom,geni-i2c";
				reg = <0x00 0x888000 0x00 0x4000>;
				clock-names = "se";
				clocks = <0x3a 0x48>;
				pinctrl-names = "default";
				pinctrl-0 = <0x45>;
				interrupts = <0x00 0x25b 0x04>;
				#address-cells = <0x01>;
				#size-cells = <0x00>;
				power-domains = <0x39 0x03>;
				operating-points-v2 = <0x3e>;
				interconnects = <0x3b 0x0a 0x00 0x3c 0x1d 0x00 0x05 0x00 0x00 0x3c 0x1d 0x00 0x3b 0x0a 0x00 0x06 0x0e 0x00>;
				interconnect-names = "qup-core\0qup-config\0qup-memory";
				dmas = <0x3f 0x00 0x02 0x03 0x3f 0x01 0x02 0x03>;
				dma-names = "tx\0rx";
				status = "disabled";
			};

			spi@888000 {
				compatible = "qcom,geni-spi";
				reg = <0x00 0x888000 0x00 0x4000>;
				clock-names = "se";
				clocks = <0x3a 0x48>;
				pinctrl-names = "default";
				pinctrl-0 = <0x46>;
				interrupts = <0x00 0x25b 0x04>;
				#address-cells = <0x01>;
				#size-cells = <0x00>;
				interconnects = <0x3b 0x0a 0x00 0x3c 0x1d 0x00 0x05 0x00 0x00 0x3c 0x1d 0x00>;
				interconnect-names = "qup-core\0qup-config";
				dmas = <0x3f 0x00 0x02 0x01 0x3f 0x01 0x02 0x01>;
				dma-names = "tx\0rx";
				status = "disabled";
			};

			serial@888000 {
				compatible = "qcom,geni-uart";
				reg = <0x00 0x888000 0x00 0x4000>;
				clock-names = "se";
				clocks = <0x3a 0x48>;
				pinctrl-names = "default";
				pinctrl-0 = <0x47>;
				interrupts = <0x00 0x25b 0x04>;
				power-domains = <0x39 0x03>;
				operating-points-v2 = <0x3e>;
				interconnects = <0x3b 0x0a 0x00 0x3c 0x1d 0x00 0x05 0x00 0x00 0x3c 0x1d 0x00>;
				interconnect-names = "qup-core\0qup-config";
				status = "disabled";
			};

			i2c@88c000 {
				compatible = "qcom,geni-i2c";
				reg = <0x00 0x88c000 0x00 0x4000>;
				clock-names = "se";
				clocks = <0x3a 0x4a>;
				pinctrl-names = "default";
				pinctrl-0 = <0x48>;
				interrupts = <0x00 0x25c 0x04>;
				#address-cells = <0x01>;
				#size-cells = <0x00>;
				power-domains = <0x39 0x03>;
				operating-points-v2 = <0x3e>;
				interconnects = <0x3b 0x0a 0x00 0x3c 0x1d 0x00 0x05 0x00 0x00 0x3c 0x1d 0x00 0x3b 0x0a 0x00 0x06 0x0e 0x00>;
				interconnect-names = "qup-core\0qup-config\0qup-memory";
				dmas = <0x3f 0x00 0x03 0x03 0x3f 0x01 0x03 0x03>;
				dma-names = "tx\0rx";
				status = "disabled";
			};

			spi@88c000 {
				compatible = "qcom,geni-spi";
				reg = <0x00 0x88c000 0x00 0x4000>;
				clock-names = "se";
				clocks = <0x3a 0x4a>;
				pinctrl-names = "default";
				pinctrl-0 = <0x49>;
				interrupts = <0x00 0x25c 0x04>;
				#address-cells = <0x01>;
				#size-cells = <0x00>;
				interconnects = <0x3b 0x0a 0x00 0x3c 0x1d 0x00 0x05 0x00 0x00 0x3c 0x1d 0x00>;
				interconnect-names = "qup-core\0qup-config";
				dmas = <0x3f 0x00 0x03 0x01 0x3f 0x01 0x03 0x01>;
				dma-names = "tx\0rx";
				status = "disabled";
			};

			serial@88c000 {
				compatible = "qcom,geni-uart";
				reg = <0x00 0x88c000 0x00 0x4000>;
				clock-names = "se";
				clocks = <0x3a 0x4a>;
				pinctrl-names = "default";
				pinctrl-0 = <0x4a>;
				interrupts = <0x00 0x25c 0x04>;
				power-domains = <0x39 0x03>;
				operating-points-v2 = <0x3e>;
				interconnects = <0x3b 0x0a 0x00 0x3c 0x1d 0x00 0x05 0x00 0x00 0x3c 0x1d 0x00>;
				interconnect-names = "qup-core\0qup-config";
				status = "disabled";
			};

			i2c@890000 {
				compatible = "qcom,geni-i2c";
				reg = <0x00 0x890000 0x00 0x4000>;
				clock-names = "se";
				clocks = <0x3a 0x4c>;
				pinctrl-names = "default";
				pinctrl-0 = <0x4b>;
				interrupts = <0x00 0x25d 0x04>;
				#address-cells = <0x01>;
				#size-cells = <0x00>;
				power-domains = <0x39 0x03>;
				operating-points-v2 = <0x3e>;
				interconnects = <0x3b 0x0a 0x00 0x3c 0x1d 0x00 0x05 0x00 0x00 0x3c 0x1d 0x00 0x3b 0x0a 0x00 0x06 0x0e 0x00>;
				interconnect-names = "qup-core\0qup-config\0qup-memory";
				dmas = <0x3f 0x00 0x04 0x03 0x3f 0x01 0x04 0x03>;
				dma-names = "tx\0rx";
				status = "disabled";
			};

			spi@890000 {
				compatible = "qcom,geni-spi";
				reg = <0x00 0x890000 0x00 0x4000>;
				clock-names = "se";
				clocks = <0x3a 0x4c>;
				pinctrl-names = "default";
				pinctrl-0 = <0x4c>;
				interrupts = <0x00 0x25d 0x04>;
				#address-cells = <0x01>;
				#size-cells = <0x00>;
				interconnects = <0x3b 0x0a 0x00 0x3c 0x1d 0x00 0x05 0x00 0x00 0x3c 0x1d 0x00>;
				interconnect-names = "qup-core\0qup-config";
				dmas = <0x3f 0x00 0x04 0x01 0x3f 0x01 0x04 0x01>;
				dma-names = "tx\0rx";
				status = "disabled";
			};

			serial@890000 {
				compatible = "qcom,geni-uart";
				reg = <0x00 0x890000 0x00 0x4000>;
				clock-names = "se";
				clocks = <0x3a 0x4c>;
				pinctrl-names = "default";
				pinctrl-0 = <0x4d>;
				interrupts = <0x00 0x25d 0x04>;
				power-domains = <0x39 0x03>;
				operating-points-v2 = <0x3e>;
				interconnects = <0x3b 0x0a 0x00 0x3c 0x1d 0x00 0x05 0x00 0x00 0x3c 0x1d 0x00>;
				interconnect-names = "qup-core\0qup-config";
				status = "disabled";
			};

			i2c@894000 {
				compatible = "qcom,geni-i2c";
				reg = <0x00 0x894000 0x00 0x4000>;
				clock-names = "se";
				clocks = <0x3a 0x4e>;
				pinctrl-names = "default";
				pinctrl-0 = <0x4e>;
				interrupts = <0x00 0x25e 0x04>;
				#address-cells = <0x01>;
				#size-cells = <0x00>;
				power-domains = <0x39 0x03>;
				operating-points-v2 = <0x3e>;
				interconnects = <0x3b 0x0a 0x00 0x3c 0x1d 0x00 0x05 0x00 0x00 0x3c 0x1d 0x00 0x3b 0x0a 0x00 0x06 0x0e 0x00>;
				interconnect-names = "qup-core\0qup-config\0qup-memory";
				dmas = <0x3f 0x00 0x05 0x03 0x3f 0x01 0x05 0x03>;
				dma-names = "tx\0rx";
				status = "disabled";
			};

			spi@894000 {
				compatible = "qcom,geni-spi";
				reg = <0x00 0x894000 0x00 0x4000>;
				clock-names = "se";
				clocks = <0x3a 0x4e>;
				pinctrl-names = "default";
				pinctrl-0 = <0x4f>;
				interrupts = <0x00 0x25e 0x04>;
				#address-cells = <0x01>;
				#size-cells = <0x00>;
				interconnects = <0x3b 0x0a 0x00 0x3c 0x1d 0x00 0x05 0x00 0x00 0x3c 0x1d 0x00>;
				interconnect-names = "qup-core\0qup-config";
				dmas = <0x3f 0x00 0x05 0x01 0x3f 0x01 0x05 0x01>;
				dma-names = "tx\0rx";
				status = "disabled";
			};

			serial@894000 {
				compatible = "qcom,geni-uart";
				reg = <0x00 0x894000 0x00 0x4000>;
				clock-names = "se";
				clocks = <0x3a 0x4e>;
				pinctrl-names = "default";
				pinctrl-0 = <0x50>;
				interrupts = <0x00 0x25e 0x04>;
				power-domains = <0x39 0x03>;
				operating-points-v2 = <0x3e>;
				interconnects = <0x3b 0x0a 0x00 0x3c 0x1d 0x00 0x05 0x00 0x00 0x3c 0x1d 0x00>;
				interconnect-names = "qup-core\0qup-config";
				status = "disabled";
			};

			i2c@898000 {
				compatible = "qcom,geni-i2c";
				reg = <0x00 0x898000 0x00 0x4000>;
				clock-names = "se";
				clocks = <0x3a 0x50>;
				pinctrl-names = "default";
				pinctrl-0 = <0x51>;
				interrupts = <0x00 0x25f 0x04>;
				#address-cells = <0x01>;
				#size-cells = <0x00>;
				power-domains = <0x39 0x03>;
				operating-points-v2 = <0x3e>;
				interconnects = <0x3b 0x0a 0x00 0x3c 0x1d 0x00 0x05 0x00 0x00 0x3c 0x1d 0x00 0x3b 0x0a 0x00 0x06 0x0e 0x00>;
				interconnect-names = "qup-core\0qup-config\0qup-memory";
				dmas = <0x3f 0x00 0x06 0x03 0x3f 0x01 0x06 0x03>;
				dma-names = "tx\0rx";
				status = "disabled";
			};

			spi@898000 {
				compatible = "qcom,geni-spi";
				reg = <0x00 0x898000 0x00 0x4000>;
				clock-names = "se";
				clocks = <0x3a 0x50>;
				pinctrl-names = "default";
				pinctrl-0 = <0x52>;
				interrupts = <0x00 0x25f 0x04>;
				#address-cells = <0x01>;
				#size-cells = <0x00>;
				interconnects = <0x3b 0x0a 0x00 0x3c 0x1d 0x00 0x05 0x00 0x00 0x3c 0x1d 0x00>;
				interconnect-names = "qup-core\0qup-config";
				dmas = <0x3f 0x00 0x06 0x01 0x3f 0x01 0x06 0x01>;
				dma-names = "tx\0rx";
				status = "disabled";
			};

			serial@898000 {
				compatible = "qcom,geni-uart";
				reg = <0x00 0x898000 0x00 0x4000>;
				clock-names = "se";
				clocks = <0x3a 0x50>;
				pinctrl-names = "default";
				pinctrl-0 = <0x53>;
				interrupts = <0x00 0x25f 0x04>;
				power-domains = <0x39 0x03>;
				operating-points-v2 = <0x3e>;
				interconnects = <0x3b 0x0a 0x00 0x3c 0x1d 0x00 0x05 0x00 0x00 0x3c 0x1d 0x00>;
				interconnect-names = "qup-core\0qup-config";
				status = "okay";

				bluetooth {
					compatible = "qcom,wcn3990-bt";
					firmware-name = "Razer/aura/crnv21.bin";
					vddio-supply = <0x54>;
					vddxo-supply = <0x55>;
					vddrf-supply = <0x56>;
					vddch0-supply = <0x57>;
					max-speed = <0x30d400>;
					local-bd-address = [60 1b b1 cd 5e 44];
				};
			};

			i2c@89c000 {
				compatible = "qcom,geni-i2c";
				reg = <0x00 0x89c000 0x00 0x4000>;
				clock-names = "se";
				clocks = <0x3a 0x52>;
				pinctrl-names = "default";
				pinctrl-0 = <0x58>;
				interrupts = <0x00 0x260 0x04>;
				#address-cells = <0x01>;
				#size-cells = <0x00>;
				power-domains = <0x39 0x03>;
				operating-points-v2 = <0x3e>;
				status = "disabled";
			};

			spi@89c000 {
				compatible = "qcom,geni-spi";
				reg = <0x00 0x89c000 0x00 0x4000>;
				clock-names = "se";
				clocks = <0x3a 0x52>;
				pinctrl-names = "default";
				pinctrl-0 = <0x59>;
				interrupts = <0x00 0x260 0x04>;
				#address-cells = <0x01>;
				#size-cells = <0x00>;
				interconnects = <0x3b 0x0a 0x00 0x3c 0x1d 0x00 0x05 0x00 0x00 0x3c 0x1d 0x00>;
				interconnect-names = "qup-core\0qup-config";
				dmas = <0x3f 0x00 0x07 0x01 0x3f 0x01 0x07 0x01>;
				dma-names = "tx\0rx";
				status = "disabled";
			};

			serial@89c000 {
				compatible = "qcom,geni-uart";
				reg = <0x00 0x89c000 0x00 0x4000>;
				clock-names = "se";
				clocks = <0x3a 0x52>;
				pinctrl-names = "default";
				pinctrl-0 = <0x5a>;
				interrupts = <0x00 0x260 0x04>;
				power-domains = <0x39 0x03>;
				operating-points-v2 = <0x3e>;
				interconnects = <0x3b 0x0a 0x00 0x3c 0x1d 0x00 0x05 0x00 0x00 0x3c 0x1d 0x00>;
				interconnect-names = "qup-core\0qup-config";
				status = "disabled";
			};
		};

		dma-controller@a00000 {
			#dma-cells = <0x03>;
			compatible = "qcom,sdm845-gpi-dma";
			reg = <0x00 0xa00000 0x00 0x60000>;
			interrupts = <0x00 0x117 0x04 0x00 0x118 0x04 0x00 0x119 0x04 0x00 0x11a 0x04 0x00 0x11b 0x04 0x00 0x11c 0x04 0x00 0x125 0x04 0x00 0x126 0x04 0x00 0x127 0x04 0x00 0x128 0x04 0x00 0x129 0x04 0x00 0x12a 0x04 0x00 0x12b 0x04>;
			dma-channels = <0x0d>;
			dma-channel-mask = <0xfa>;
			iommus = <0x32 0x6d6 0x00>;
			status = "disabled";
			phandle = <0x5d>;
		};

		geniqup@ac0000 {
			compatible = "qcom,geni-se-qup";
			reg = <0x00 0xac0000 0x00 0x6000>;
			clock-names = "m-ahb\0s-ahb";
			clocks = <0x3a 0x66 0x3a 0x67>;
			iommus = <0x32 0x6c3 0x00>;
			#address-cells = <0x02>;
			#size-cells = <0x02>;
			ranges;
			interconnects = <0x5b 0x0c 0x00 0x3c 0x1c 0x00>;
			interconnect-names = "qup-core";
			status = "okay";

			i2c@a80000 {
				compatible = "qcom,geni-i2c";
				reg = <0x00 0xa80000 0x00 0x4000>;
				clock-names = "se";
				clocks = <0x3a 0x54>;
				pinctrl-names = "default";
				pinctrl-0 = <0x5c>;
				interrupts = <0x00 0x161 0x04>;
				#address-cells = <0x01>;
				#size-cells = <0x00>;
				power-domains = <0x39 0x03>;
				operating-points-v2 = <0x3e>;
				interconnects = <0x5b 0x0c 0x00 0x3c 0x1c 0x00 0x05 0x00 0x00 0x3c 0x1c 0x00 0x5b 0x0c 0x00 0x06 0x0e 0x00>;
				interconnect-names = "qup-core\0qup-config\0qup-memory";
				dmas = <0x5d 0x00 0x00 0x03 0x5d 0x01 0x00 0x03>;
				dma-names = "tx\0rx";
				status = "disabled";
			};

			spi@a80000 {
				compatible = "qcom,geni-spi";
				reg = <0x00 0xa80000 0x00 0x4000>;
				clock-names = "se";
				clocks = <0x3a 0x54>;
				pinctrl-names = "default";
				pinctrl-0 = <0x5e>;
				interrupts = <0x00 0x161 0x04>;
				#address-cells = <0x01>;
				#size-cells = <0x00>;
				interconnects = <0x5b 0x0c 0x00 0x3c 0x1c 0x00 0x05 0x00 0x00 0x3c 0x1c 0x00>;
				interconnect-names = "qup-core\0qup-config";
				dmas = <0x5d 0x00 0x00 0x01 0x5d 0x01 0x00 0x01>;
				dma-names = "tx\0rx";
				status = "disabled";
			};

			serial@a80000 {
				compatible = "qcom,geni-uart";
				reg = <0x00 0xa80000 0x00 0x4000>;
				clock-names = "se";
				clocks = <0x3a 0x54>;
				pinctrl-names = "default";
				pinctrl-0 = <0x5f>;
				interrupts = <0x00 0x161 0x04>;
				power-domains = <0x39 0x03>;
				operating-points-v2 = <0x3e>;
				interconnects = <0x5b 0x0c 0x00 0x3c 0x1c 0x00 0x05 0x00 0x00 0x3c 0x1c 0x00>;
				interconnect-names = "qup-core\0qup-config";
				status = "disabled";
			};

			i2c@a84000 {
				compatible = "qcom,geni-i2c";
				reg = <0x00 0xa84000 0x00 0x4000>;
				clock-names = "se";
				clocks = <0x3a 0x56>;
				pinctrl-names = "default";
				pinctrl-0 = <0x60>;
				interrupts = <0x00 0x162 0x04>;
				#address-cells = <0x01>;
				#size-cells = <0x00>;
				power-domains = <0x39 0x03>;
				operating-points-v2 = <0x3e>;
				interconnects = <0x5b 0x0c 0x00 0x3c 0x1c 0x00 0x05 0x00 0x00 0x3c 0x1c 0x00 0x5b 0x0c 0x00 0x06 0x0e 0x00>;
				interconnect-names = "qup-core\0qup-config\0qup-memory";
				dmas = <0x5d 0x00 0x01 0x03 0x5d 0x01 0x01 0x03>;
				dma-names = "tx\0rx";
				status = "disabled";
			};

			spi@a84000 {
				compatible = "qcom,geni-spi";
				reg = <0x00 0xa84000 0x00 0x4000>;
				clock-names = "se";
				clocks = <0x3a 0x56>;
				pinctrl-names = "default";
				pinctrl-0 = <0x61>;
				interrupts = <0x00 0x162 0x04>;
				#address-cells = <0x01>;
				#size-cells = <0x00>;
				interconnects = <0x5b 0x0c 0x00 0x3c 0x1c 0x00 0x05 0x00 0x00 0x3c 0x1c 0x00>;
				interconnect-names = "qup-core\0qup-config";
				dmas = <0x5d 0x00 0x01 0x01 0x5d 0x01 0x01 0x01>;
				dma-names = "tx\0rx";
				status = "disabled";
			};

			serial@a84000 {
				compatible = "qcom,geni-debug-uart";
				reg = <0x00 0xa84000 0x00 0x4000>;
				clock-names = "se";
				clocks = <0x3a 0x56>;
				pinctrl-names = "default";
				pinctrl-0 = <0x62>;
				interrupts = <0x00 0x162 0x04>;
				power-domains = <0x39 0x03>;
				operating-points-v2 = <0x3e>;
				interconnects = <0x5b 0x0c 0x00 0x3c 0x1c 0x00 0x05 0x00 0x00 0x3c 0x1c 0x00>;
				interconnect-names = "qup-core\0qup-config";
				status = "okay";
				label = "UART-DEBUG";
			};

			i2c@a88000 {
				compatible = "qcom,geni-i2c";
				reg = <0x00 0xa88000 0x00 0x4000>;
				clock-names = "se";
				clocks = <0x3a 0x58>;
				pinctrl-names = "default";
				pinctrl-0 = <0x63>;
				interrupts = <0x00 0x163 0x04>;
				#address-cells = <0x01>;
				#size-cells = <0x00>;
				power-domains = <0x39 0x03>;
				operating-points-v2 = <0x3e>;
				interconnects = <0x5b 0x0c 0x00 0x3c 0x1c 0x00 0x05 0x00 0x00 0x3c 0x1c 0x00 0x5b 0x0c 0x00 0x06 0x0e 0x00>;
				interconnect-names = "qup-core\0qup-config\0qup-memory";
				dmas = <0x5d 0x00 0x02 0x03 0x5d 0x01 0x02 0x03>;
				dma-names = "tx\0rx";
				status = "disabled";
			};

			spi@a88000 {
				compatible = "qcom,geni-spi";
				reg = <0x00 0xa88000 0x00 0x4000>;
				clock-names = "se";
				clocks = <0x3a 0x58>;
				pinctrl-names = "default";
				pinctrl-0 = <0x64>;
				interrupts = <0x00 0x163 0x04>;
				#address-cells = <0x01>;
				#size-cells = <0x00>;
				interconnects = <0x5b 0x0c 0x00 0x3c 0x1c 0x00 0x05 0x00 0x00 0x3c 0x1c 0x00>;
				interconnect-names = "qup-core\0qup-config";
				dmas = <0x5d 0x00 0x02 0x01 0x5d 0x01 0x02 0x01>;
				dma-names = "tx\0rx";
				status = "disabled";
			};

			serial@a88000 {
				compatible = "qcom,geni-uart";
				reg = <0x00 0xa88000 0x00 0x4000>;
				clock-names = "se";
				clocks = <0x3a 0x58>;
				pinctrl-names = "default";
				pinctrl-0 = <0x65>;
				interrupts = <0x00 0x163 0x04>;
				power-domains = <0x39 0x03>;
				operating-points-v2 = <0x3e>;
				interconnects = <0x5b 0x0c 0x00 0x3c 0x1c 0x00 0x05 0x00 0x00 0x3c 0x1c 0x00>;
				interconnect-names = "qup-core\0qup-config";
				status = "disabled";
			};

			i2c@a8c000 {
				compatible = "qcom,geni-i2c";
				reg = <0x00 0xa8c000 0x00 0x4000>;
				clock-names = "se";
				clocks = <0x3a 0x5a>;
				pinctrl-names = "default";
				pinctrl-0 = <0x66>;
				interrupts = <0x00 0x164 0x04>;
				#address-cells = <0x01>;
				#size-cells = <0x00>;
				power-domains = <0x39 0x03>;
				operating-points-v2 = <0x3e>;
				interconnects = <0x5b 0x0c 0x00 0x3c 0x1c 0x00 0x05 0x00 0x00 0x3c 0x1c 0x00 0x5b 0x0c 0x00 0x06 0x0e 0x00>;
				interconnect-names = "qup-core\0qup-config\0qup-memory";
				dmas = <0x5d 0x00 0x03 0x03 0x5d 0x01 0x03 0x03>;
				dma-names = "tx\0rx";
				status = "disabled";
			};

			spi@a8c000 {
				compatible = "qcom,geni-spi";
				reg = <0x00 0xa8c000 0x00 0x4000>;
				clock-names = "se";
				clocks = <0x3a 0x5a>;
				pinctrl-names = "default";
				pinctrl-0 = <0x67>;
				interrupts = <0x00 0x164 0x04>;
				#address-cells = <0x01>;
				#size-cells = <0x00>;
				interconnects = <0x5b 0x0c 0x00 0x3c 0x1c 0x00 0x05 0x00 0x00 0x3c 0x1c 0x00>;
				interconnect-names = "qup-core\0qup-config";
				dmas = <0x5d 0x00 0x03 0x01 0x5d 0x01 0x03 0x01>;
				dma-names = "tx\0rx";
				status = "disabled";
			};

			serial@a8c000 {
				compatible = "qcom,geni-uart";
				reg = <0x00 0xa8c000 0x00 0x4000>;
				clock-names = "se";
				clocks = <0x3a 0x5a>;
				pinctrl-names = "default";
				pinctrl-0 = <0x68>;
				interrupts = <0x00 0x164 0x04>;
				power-domains = <0x39 0x03>;
				operating-points-v2 = <0x3e>;
				interconnects = <0x5b 0x0c 0x00 0x3c 0x1c 0x00 0x05 0x00 0x00 0x3c 0x1c 0x00>;
				interconnect-names = "qup-core\0qup-config";
				status = "disabled";
			};

			i2c@a90000 {
				compatible = "qcom,geni-i2c";
				reg = <0x00 0xa90000 0x00 0x4000>;
				clock-names = "se";
				clocks = <0x3a 0x5c>;
				pinctrl-names = "default";
				pinctrl-0 = <0x69>;
				interrupts = <0x00 0x165 0x04>;
				#address-cells = <0x01>;
				#size-cells = <0x00>;
				power-domains = <0x39 0x03>;
				operating-points-v2 = <0x3e>;
				interconnects = <0x5b 0x0c 0x00 0x3c 0x1c 0x00 0x05 0x00 0x00 0x3c 0x1c 0x00 0x5b 0x0c 0x00 0x06 0x0e 0x00>;
				interconnect-names = "qup-core\0qup-config\0qup-memory";
				dmas = <0x5d 0x00 0x04 0x03 0x5d 0x01 0x04 0x03>;
				dma-names = "tx\0rx";
				status = "disabled";
			};

			spi@a90000 {
				compatible = "qcom,geni-spi";
				reg = <0x00 0xa90000 0x00 0x4000>;
				clock-names = "se";
				clocks = <0x3a 0x5c>;
				pinctrl-names = "default";
				pinctrl-0 = <0x6a>;
				interrupts = <0x00 0x165 0x04>;
				#address-cells = <0x01>;
				#size-cells = <0x00>;
				interconnects = <0x5b 0x0c 0x00 0x3c 0x1c 0x00 0x05 0x00 0x00 0x3c 0x1c 0x00>;
				interconnect-names = "qup-core\0qup-config";
				dmas = <0x5d 0x00 0x04 0x01 0x5d 0x01 0x04 0x01>;
				dma-names = "tx\0rx";
				status = "disabled";
			};

			serial@a90000 {
				compatible = "qcom,geni-uart";
				reg = <0x00 0xa90000 0x00 0x4000>;
				clock-names = "se";
				clocks = <0x3a 0x5c>;
				pinctrl-names = "default";
				pinctrl-0 = <0x6b>;
				interrupts = <0x00 0x165 0x04>;
				power-domains = <0x39 0x03>;
				operating-points-v2 = <0x3e>;
				interconnects = <0x5b 0x0c 0x00 0x3c 0x1c 0x00 0x05 0x00 0x00 0x3c 0x1c 0x00>;
				interconnect-names = "qup-core\0qup-config";
				status = "disabled";
			};

			i2c@a94000 {
				compatible = "qcom,geni-i2c";
				reg = <0x00 0xa94000 0x00 0x4000>;
				clock-names = "se";
				clocks = <0x3a 0x5e>;
				pinctrl-names = "default";
				pinctrl-0 = <0x6c>;
				interrupts = <0x00 0x166 0x04>;
				#address-cells = <0x01>;
				#size-cells = <0x00>;
				power-domains = <0x39 0x03>;
				operating-points-v2 = <0x3e>;
				interconnects = <0x5b 0x0c 0x00 0x3c 0x1c 0x00 0x05 0x00 0x00 0x3c 0x1c 0x00 0x5b 0x0c 0x00 0x06 0x0e 0x00>;
				interconnect-names = "qup-core\0qup-config\0qup-memory";
				dmas = <0x5d 0x00 0x05 0x03 0x5d 0x01 0x05 0x03>;
				dma-names = "tx\0rx";
				status = "disabled";
			};

			spi@a94000 {
				compatible = "qcom,geni-spi";
				reg = <0x00 0xa94000 0x00 0x4000>;
				clock-names = "se";
				clocks = <0x3a 0x5e>;
				pinctrl-names = "default";
				pinctrl-0 = <0x6d>;
				interrupts = <0x00 0x166 0x04>;
				#address-cells = <0x01>;
				#size-cells = <0x00>;
				interconnects = <0x5b 0x0c 0x00 0x3c 0x1c 0x00 0x05 0x00 0x00 0x3c 0x1c 0x00>;
				interconnect-names = "qup-core\0qup-config";
				dmas = <0x5d 0x00 0x05 0x01 0x5d 0x01 0x05 0x01>;
				dma-names = "tx\0rx";
				status = "disabled";
			};

			serial@a94000 {
				compatible = "qcom,geni-uart";
				reg = <0x00 0xa94000 0x00 0x4000>;
				clock-names = "se";
				clocks = <0x3a 0x5e>;
				pinctrl-names = "default";
				pinctrl-0 = <0x6e>;
				interrupts = <0x00 0x166 0x04>;
				power-domains = <0x39 0x03>;
				operating-points-v2 = <0x3e>;
				interconnects = <0x5b 0x0c 0x00 0x3c 0x1c 0x00 0x05 0x00 0x00 0x3c 0x1c 0x00>;
				interconnect-names = "qup-core\0qup-config";
				status = "disabled";
			};

			i2c@a98000 {
				compatible = "qcom,geni-i2c";
				reg = <0x00 0xa98000 0x00 0x4000>;
				clock-names = "se";
				clocks = <0x3a 0x60>;
				pinctrl-names = "default";
				pinctrl-0 = <0x6f>;
				interrupts = <0x00 0x167 0x04>;
				#address-cells = <0x01>;
				#size-cells = <0x00>;
				power-domains = <0x39 0x03>;
				operating-points-v2 = <0x3e>;
				interconnects = <0x5b 0x0c 0x00 0x3c 0x1c 0x00 0x05 0x00 0x00 0x3c 0x1c 0x00 0x5b 0x0c 0x00 0x06 0x0e 0x00>;
				interconnect-names = "qup-core\0qup-config\0qup-memory";
				dmas = <0x5d 0x00 0x06 0x03 0x5d 0x01 0x06 0x03>;
				dma-names = "tx\0rx";
				status = "okay";
				clock-frequency = <0x61a80>;

				touchscreen@20 {
					compatible = "syna,rmi4-i2c";
					reg = <0x20>;
					#address-cells = <0x01>;
					#size-cells = <0x00>;
					interrupts-extended = <0x70 0x1f 0x08>;
					pinctrl-names = "default";
					pinctrl-0 = <0x71>;
					vdd-supply = <0x72>;
					vio-supply = <0x73>;
					syna,reset-delay-ms = <0xc8>;
					syna,startup-delay-ms = <0xc8>;

					rmi4-f01@1 {
						reg = <0x01>;
						syna,nosleep-mode = <0x01>;
					};

					rmi4-f12@12 {
						reg = <0x12>;
						touchscreen-x-mm = <0x44>;
						touchscreen-y-mm = <0x78>;
						syna,sensor-type = <0x01>;
						syna,rezero-wait-ms = <0xc8>;
					};
				};
			};

			spi@a98000 {
				compatible = "qcom,geni-spi";
				reg = <0x00 0xa98000 0x00 0x4000>;
				clock-names = "se";
				clocks = <0x3a 0x60>;
				pinctrl-names = "default";
				pinctrl-0 = <0x74>;
				interrupts = <0x00 0x167 0x04>;
				#address-cells = <0x01>;
				#size-cells = <0x00>;
				interconnects = <0x5b 0x0c 0x00 0x3c 0x1c 0x00 0x05 0x00 0x00 0x3c 0x1c 0x00>;
				interconnect-names = "qup-core\0qup-config";
				dmas = <0x5d 0x00 0x06 0x01 0x5d 0x01 0x06 0x01>;
				dma-names = "tx\0rx";
				status = "disabled";
			};

			serial@a98000 {
				compatible = "qcom,geni-uart";
				reg = <0x00 0xa98000 0x00 0x4000>;
				clock-names = "se";
				clocks = <0x3a 0x60>;
				pinctrl-names = "default";
				pinctrl-0 = <0x75>;
				interrupts = <0x00 0x167 0x04>;
				power-domains = <0x39 0x03>;
				operating-points-v2 = <0x3e>;
				interconnects = <0x5b 0x0c 0x00 0x3c 0x1c 0x00 0x05 0x00 0x00 0x3c 0x1c 0x00>;
				interconnect-names = "qup-core\0qup-config";
				status = "disabled";
			};

			i2c@a9c000 {
				compatible = "qcom,geni-i2c";
				reg = <0x00 0xa9c000 0x00 0x4000>;
				clock-names = "se";
				clocks = <0x3a 0x62>;
				pinctrl-names = "default";
				pinctrl-0 = <0x76>;
				interrupts = <0x00 0x168 0x04>;
				#address-cells = <0x01>;
				#size-cells = <0x00>;
				power-domains = <0x39 0x03>;
				operating-points-v2 = <0x3e>;
				status = "disabled";
				interconnects = <0x5b 0x0c 0x00 0x3c 0x1c 0x00 0x05 0x00 0x00 0x3c 0x1c 0x00 0x5b 0x0c 0x00 0x06 0x0e 0x00>;
				interconnect-names = "qup-core\0qup-config\0qup-memory";
				dmas = <0x5d 0x00 0x07 0x03 0x5d 0x01 0x07 0x03>;
				dma-names = "tx\0rx";
			};

			spi@a9c000 {
				compatible = "qcom,geni-spi";
				reg = <0x00 0xa9c000 0x00 0x4000>;
				clock-names = "se";
				clocks = <0x3a 0x62>;
				pinctrl-names = "default";
				pinctrl-0 = <0x77>;
				interrupts = <0x00 0x168 0x04>;
				#address-cells = <0x01>;
				#size-cells = <0x00>;
				interconnects = <0x5b 0x0c 0x00 0x3c 0x1c 0x00 0x05 0x00 0x00 0x3c 0x1c 0x00>;
				interconnect-names = "qup-core\0qup-config";
				dmas = <0x5d 0x00 0x07 0x01 0x5d 0x01 0x07 0x01>;
				dma-names = "tx\0rx";
				status = "disabled";
			};

			serial@a9c000 {
				compatible = "qcom,geni-uart";
				reg = <0x00 0xa9c000 0x00 0x4000>;
				clock-names = "se";
				clocks = <0x3a 0x62>;
				pinctrl-names = "default";
				pinctrl-0 = <0x78>;
				interrupts = <0x00 0x168 0x04>;
				power-domains = <0x39 0x03>;
				operating-points-v2 = <0x3e>;
				interconnects = <0x5b 0x0c 0x00 0x3c 0x1c 0x00 0x05 0x00 0x00 0x3c 0x1c 0x00>;
				interconnect-names = "qup-core\0qup-config";
				status = "disabled";
			};
		};

		system-cache-controller@1100000 {
			compatible = "qcom,sdm845-llcc";
			reg = <0x00 0x1100000 0x00 0x45000 0x00 0x1180000 0x00 0x50000 0x00 0x1200000 0x00 0x50000 0x00 0x1280000 0x00 0x50000 0x00 0x1300000 0x00 0x50000>;
			reg-names = "llcc0_base\0llcc1_base\0llcc2_base\0llcc3_base\0llcc_broadcast_base";
			interrupts = <0x00 0x246 0x04>;
		};

		dma@10a2000 {
			compatible = "qcom,sdm845-dcc\0qcom,dcc";
			reg = <0x00 0x10a2000 0x00 0x1000 0x00 0x10ae000 0x00 0x2000>;
		};

		pmu@114a000 {
			compatible = "qcom,sdm845-llcc-bwmon";
			reg = <0x00 0x114a000 0x00 0x1000>;
			interrupts = <0x00 0x244 0x04>;
			interconnects = <0x06 0x0d 0x03 0x06 0x0e 0x03>;
			operating-points-v2 = <0x79>;

			opp-table {
				compatible = "operating-points-v2";
				phandle = <0x79>;

				opp-0 {
					opp-peak-kBps = "\0\f5";
				};

				opp-1 {
					opp-peak-kBps = <0x1b86e0>;
				};

				opp-2 {
					opp-peak-kBps = <0x2ee000>;
				};

				opp-3 {
					opp-peak-kBps = <0x5294a0>;
				};

				opp-4 {
					opp-peak-kBps = <0x6e1b80>;
				};
			};
		};

		pmu@1436400 {
			compatible = "qcom,sdm845-cpu-bwmon\0qcom,sdm845-bwmon";
			reg = <0x00 0x1436400 0x00 0x600>;
			interrupts = <0x00 0x245 0x04>;
			interconnects = <0x05 0x00 0x03 0x06 0x0a 0x03>;
			operating-points-v2 = <0x7a>;

			opp-table {
				compatible = "operating-points-v2";
				phandle = <0x7a>;

				opp-0 {
					opp-peak-kBps = "\0I>";
				};

				opp-1 {
					opp-peak-kBps = <0x8ca000>;
				};

				opp-2 {
					opp-peak-kBps = <0xe5b000>;
				};

				opp-3 {
					opp-peak-kBps = <0x13ec000>;
				};

				opp-4 {
					opp-peak-kBps = <0x1851000>;
				};
			};
		};

		pcie@1c00000 {
			compatible = "qcom,pcie-sdm845";
			reg = <0x00 0x1c00000 0x00 0x2000 0x00 0x60000000 0x00 0xf1d 0x00 0x60000f20 0x00 0xa8 0x00 0x60100000 0x00 0x100000 0x00 0x1c07000 0x00 0x1000>;
			reg-names = "parf\0dbi\0elbi\0config\0mhi";
			device_type = "pci";
			linux,pci-domain = <0x00>;
			bus-range = <0x00 0xff>;
			num-lanes = <0x01>;
			#address-cells = <0x03>;
			#size-cells = <0x02>;
			ranges = <0x1000000 0x00 0x00 0x00 0x60200000 0x00 0x100000 0x2000000 0x00 0x60300000 0x00 0x60300000 0x00 0xd00000>;
			interrupts = <0x00 0x8d 0x04>;
			interrupt-names = "msi";
			#interrupt-cells = <0x01>;
			interrupt-map-mask = <0x00 0x00 0x00 0x07>;
			interrupt-map = <0x00 0x00 0x00 0x01 0x01 0x00 0x00 0x00 0x95 0x04 0x00 0x00 0x00 0x02 0x01 0x00 0x00 0x00 0x96 0x04 0x00 0x00 0x00 0x03 0x01 0x00 0x00 0x00 0x97 0x04 0x00 0x00 0x00 0x04 0x01 0x00 0x00 0x00 0x98 0x04>;
			clocks = <0x3a 0x2e 0x3a 0x29 0x3a 0x2b 0x3a 0x2d 0x3a 0x2f 0x3a 0x30 0x3a 0x00>;
			clock-names = "pipe\0aux\0cfg\0bus_master\0bus_slave\0slave_q2a\0tbu";
			iommu-map = <0x00 0x32 0x1c10 0x01 0x100 0x32 0x1c11 0x01 0x200 0x32 0x1c12 0x01 0x300 0x32 0x1c13 0x01 0x400 0x32 0x1c14 0x01 0x500 0x32 0x1c15 0x01 0x600 0x32 0x1c16 0x01 0x700 0x32 0x1c17 0x01 0x800 0x32 0x1c18 0x01 0x900 0x32 0x1c19 0x01 0xa00 0x32 0x1c1a 0x01 0xb00 0x32 0x1c1b 0x01 0xc00 0x32 0x1c1c 0x01 0xd00 0x32 0x1c1d 0x01 0xe00 0x32 0x1c1e 0x01 0xf00 0x32 0x1c1f 0x01>;
			resets = <0x3a 0x01>;
			reset-names = "pci";
			power-domains = <0x3a 0x00>;
			phys = <0x37>;
			phy-names = "pciephy";
			status = "disabled";

			pcie@0 {
				device_type = "pci";
				reg = <0x00 0x00 0x00 0x00 0x00>;
				bus-range = <0x01 0xff>;
				#address-cells = <0x03>;
				#size-cells = <0x02>;
				ranges;
			};
		};

		phy@1c06000 {
			compatible = "qcom,sdm845-qmp-pcie-phy";
			reg = <0x00 0x1c06000 0x00 0x1000>;
			clocks = <0x3a 0x39 0x3a 0x2b 0x3a 0x2c 0x3a 0x3a 0x3a 0x2e>;
			clock-names = "aux\0cfg_ahb\0ref\0refgen\0pipe";
			clock-output-names = "pcie_0_pipe_clk";
			#clock-cells = <0x00>;
			#phy-cells = <0x00>;
			resets = <0x3a 0x18>;
			reset-names = "phy";
			assigned-clocks = <0x3a 0x3a>;
			assigned-clock-rates = <0x5f5e100>;
			status = "disabled";
			phandle = <0x37>;
		};

		pcie@1c08000 {
			compatible = "qcom,pcie-sdm845";
			reg = <0x00 0x1c08000 0x00 0x2000 0x00 0x40000000 0x00 0xf1d 0x00 0x40000f20 0x00 0xa8 0x00 0x40100000 0x00 0x100000 0x00 0x1c0c000 0x00 0x1000>;
			reg-names = "parf\0dbi\0elbi\0config\0mhi";
			device_type = "pci";
			linux,pci-domain = <0x01>;
			bus-range = <0x00 0xff>;
			num-lanes = <0x01>;
			#address-cells = <0x03>;
			#size-cells = <0x02>;
			ranges = <0x1000000 0x00 0x00 0x00 0x40200000 0x00 0x100000 0x2000000 0x00 0x40300000 0x00 0x40300000 0x00 0x1fd00000>;
			interrupts = <0x00 0x133 0x01>;
			interrupt-names = "msi";
			#interrupt-cells = <0x01>;
			interrupt-map-mask = <0x00 0x00 0x00 0x07>;
			interrupt-map = <0x00 0x00 0x00 0x01 0x01 0x00 0x00 0x00 0x1b2 0x04 0x00 0x00 0x00 0x02 0x01 0x00 0x00 0x00 0x1b3 0x04 0x00 0x00 0x00 0x03 0x01 0x00 0x00 0x00 0x1b6 0x04 0x00 0x00 0x00 0x04 0x01 0x00 0x00 0x00 0x1b7 0x04>;
			clocks = <0x3a 0x36 0x3a 0x31 0x3a 0x33 0x3a 0x35 0x3a 0x37 0x3a 0x38 0x3a 0x34 0x3a 0x00>;
			clock-names = "pipe\0aux\0cfg\0bus_master\0bus_slave\0slave_q2a\0ref\0tbu";
			assigned-clocks = <0x3a 0x31>;
			assigned-clock-rates = <0x124f800>;
			iommu-map = <0x00 0x32 0x1c00 0x01 0x100 0x32 0x1c01 0x01 0x200 0x32 0x1c02 0x01 0x300 0x32 0x1c03 0x01 0x400 0x32 0x1c04 0x01 0x500 0x32 0x1c05 0x01 0x600 0x32 0x1c06 0x01 0x700 0x32 0x1c07 0x01 0x800 0x32 0x1c08 0x01 0x900 0x32 0x1c09 0x01 0xa00 0x32 0x1c0a 0x01 0xb00 0x32 0x1c0b 0x01 0xc00 0x32 0x1c0c 0x01 0xd00 0x32 0x1c0d 0x01 0xe00 0x32 0x1c0e 0x01 0xf00 0x32 0x1c0f 0x01>;
			resets = <0x3a 0x02>;
			reset-names = "pci";
			power-domains = <0x3a 0x01>;
			phys = <0x38>;
			phy-names = "pciephy";
			status = "disabled";

			pcie@0 {
				device_type = "pci";
				reg = <0x00 0x00 0x00 0x00 0x00>;
				bus-range = <0x01 0xff>;
				#address-cells = <0x03>;
				#size-cells = <0x02>;
				ranges;
			};
		};

		phy@1c0a000 {
			compatible = "qcom,sdm845-qhp-pcie-phy";
			reg = <0x00 0x1c0a000 0x00 0x2000>;
			clocks = <0x3a 0x39 0x3a 0x33 0x3a 0x34 0x3a 0x3a 0x3a 0x36>;
			clock-names = "aux\0cfg_ahb\0ref\0refgen\0pipe";
			clock-output-names = "pcie_1_pipe_clk";
			#clock-cells = <0x00>;
			#phy-cells = <0x00>;
			resets = <0x3a 0x19>;
			reset-names = "phy";
			assigned-clocks = <0x3a 0x3a>;
			assigned-clock-rates = <0x5f5e100>;
			status = "disabled";
			phandle = <0x38>;
		};

		interconnect@1380000 {
			compatible = "qcom,sdm845-mem-noc";
			reg = <0x00 0x1380000 0x00 0x27200>;
			#interconnect-cells = <0x02>;
			qcom,bcm-voters = <0x7b>;
			phandle = <0x06>;
		};

		interconnect@14e0000 {
			compatible = "qcom,sdm845-dc-noc";
			reg = <0x00 0x14e0000 0x00 0x400>;
			#interconnect-cells = <0x02>;
			qcom,bcm-voters = <0x7b>;
		};

		interconnect@1500000 {
			compatible = "qcom,sdm845-config-noc";
			reg = <0x00 0x1500000 0x00 0x5080>;
			#interconnect-cells = <0x02>;
			qcom,bcm-voters = <0x7b>;
			phandle = <0x3c>;
		};

		interconnect@1620000 {
			compatible = "qcom,sdm845-system-noc";
			reg = <0x00 0x1620000 0x00 0x18080>;
			#interconnect-cells = <0x02>;
			qcom,bcm-voters = <0x7b>;
			phandle = <0x83>;
		};

		interconnect@16e0000 {
			compatible = "qcom,sdm845-aggre1-noc";
			reg = <0x00 0x16e0000 0x00 0x15080>;
			#interconnect-cells = <0x02>;
			qcom,bcm-voters = <0x7b>;
			phandle = <0x3b>;
		};

		interconnect@1700000 {
			compatible = "qcom,sdm845-aggre2-noc";
			reg = <0x00 0x1700000 0x00 0x1f300>;
			#interconnect-cells = <0x02>;
			qcom,bcm-voters = <0x7b>;
			phandle = <0x5b>;
		};

		interconnect@1740000 {
			compatible = "qcom,sdm845-mmss-noc";
			reg = <0x00 0x1740000 0x00 0x1c100>;
			#interconnect-cells = <0x02>;
			qcom,bcm-voters = <0x7b>;
			phandle = <0xc8>;
		};

		ufshc@1d84000 {
			compatible = "qcom,sdm845-ufshc\0qcom,ufshc\0jedec,ufs-2.0";
			reg = <0x00 0x1d84000 0x00 0x2500 0x00 0x1d90000 0x00 0x8000>;
			reg-names = "std\0ice";
			interrupts = <0x00 0x109 0x04>;
			phys = <0x7c>;
			phy-names = "ufsphy";
			lanes-per-direction = <0x02>;
			power-domains = <0x3a 0x03>;
			#reset-cells = <0x01>;
			resets = <0x3a 0x0e>;
			reset-names = "rst";
			iommus = <0x32 0x100 0x0f>;
			clock-names = "core_clk\0bus_aggr_clk\0iface_clk\0core_clk_unipro\0ref_clk\0tx_lane0_sync_clk\0rx_lane0_sync_clk\0rx_lane1_sync_clk\0ice_core_clk";
			clocks = <0x3a 0x82 0x3a 0x02 0x3a 0x81 0x3a 0x8b 0x2d 0x00 0x3a 0x8a 0x3a 0x88 0x3a 0x89 0x3a 0x84>;
			operating-points-v2 = <0x7d>;
			interconnects = <0x3b 0x05 0x00 0x06 0x0e 0x00 0x05 0x00 0x00 0x3c 0x28 0x00>;
			interconnect-names = "ufs-ddr\0cpu-ufs";
			status = "okay";
			reset-gpios = <0x70 0x96 0x01>;
			vcc-supply = <0x7e>;
			vcc-max-microamp = <0x927c0>;
			phandle = <0x7f>;

			opp-table {
				compatible = "operating-points-v2";
				phandle = <0x7d>;

				opp-50000000 {
					opp-hz = <0x00 0x2faf080 0x00 0x00 0x00 0x00 0x00 0x23c3460 0x00 0x00 0x00 0x00 0x00 0x00 0x00 0x00 0x00 0x47868c0>;
					required-opps = <0x23>;
				};

				opp-200000000 {
					opp-hz = <0x00 0xbebc200 0x00 0x00 0x00 0x00 0x00 0x8f0d180 0x00 0x00 0x00 0x00 0x00 0x00 0x00 0x00 0x00 0x11e1a300>;
					required-opps = <0x26>;
				};
			};
		};

		phy@1d87000 {
			compatible = "qcom,sdm845-qmp-ufs-phy";
			reg = <0x00 0x1d87000 0x00 0x1000>;
			clocks = <0x2d 0x00 0x3a 0x86 0x3a 0x80>;
			clock-names = "ref\0ref_aux\0qref";
			power-domains = <0x3a 0x03>;
			resets = <0x7f 0x00>;
			reset-names = "ufsphy";
			#phy-cells = <0x00>;
			status = "okay";
			vdda-phy-supply = <0x55>;
			vdda-pll-supply = <0x80>;
			phandle = <0x7c>;
		};

		dma-controller@1dc4000 {
			compatible = "qcom,bam-v1.7.4\0qcom,bam-v1.7.0";
			reg = <0x00 0x1dc4000 0x00 0x24000>;
			interrupts = <0x00 0x110 0x04>;
			clocks = <0x2d 0x0f>;
			clock-names = "bam_clk";
			#dma-cells = <0x01>;
			qcom,ee = <0x00>;
			qcom,controlled-remotely;
			iommus = <0x32 0x704 0x01 0x32 0x706 0x01 0x32 0x714 0x01 0x32 0x716 0x01>;
			phandle = <0x81>;
		};

		crypto@1dfa000 {
			compatible = "qcom,crypto-v5.4";
			reg = <0x00 0x1dfa000 0x00 0x6000>;
			clocks = <0x3a 0x09 0x3a 0x0a 0x2d 0x0f>;
			clock-names = "iface\0bus\0core";
			dmas = <0x81 0x06 0x81 0x07>;
			dma-names = "rx\0tx";
			iommus = <0x32 0x704 0x01 0x32 0x706 0x01 0x32 0x714 0x01 0x32 0x716 0x01>;
			status = "disabled";
		};

		ipa@1e40000 {
			compatible = "qcom,sdm845-ipa";
			iommus = <0x32 0x720 0x00 0x32 0x722 0x00>;
			reg = <0x00 0x1e40000 0x00 0x7000 0x00 0x1e47000 0x00 0x2000 0x00 0x1e04000 0x00 0x2c000>;
			reg-names = "ipa-reg\0ipa-shared\0gsi";
			interrupts-extended = <0x01 0x00 0x137 0x01 0x01 0x00 0x1b0 0x04 0x82 0x00 0x01 0x82 0x01 0x01>;
			interrupt-names = "ipa\0gsi\0ipa-clock-query\0ipa-setup-ready";
			clocks = <0x2d 0x0c>;
			clock-names = "core";
			interconnects = <0x5b 0x04 0x00 0x06 0x0e 0x00 0x5b 0x04 0x00 0x83 0x0c 0x00 0x05 0x00 0x00 0x3c 0x13 0x00>;
			interconnect-names = "memory\0imem\0config";
			qcom,smem-states = <0x84 0x00 0x84 0x01>;
			qcom,smem-state-names = "ipa-clock-enabled-valid\0ipa-clock-enabled";
			status = "okay";
			qcom,gsi-loader = "self";
			memory-region = <0x85>;
			firmware-name = "qcom/sdm845/Razer/aura/ipa_fws.mbn";
		};

		hwlock@1f40000 {
			compatible = "qcom,tcsr-mutex";
			reg = <0x00 0x1f40000 0x00 0x20000>;
			#hwlock-cells = <0x01>;
			phandle = <0x2b>;
		};

		syscon@1f60000 {
			compatible = "qcom,sdm845-tcsr\0syscon";
			reg = <0x00 0x1f60000 0x00 0x20000>;
			phandle = <0x8b>;
		};

		pinctrl@3400000 {
			compatible = "qcom,sdm845-pinctrl";
			reg = <0x00 0x3400000 0x00 0xc00000>;
			interrupts = <0x00 0xd0 0x04>;
			gpio-controller;
			#gpio-cells = <0x02>;
			interrupt-controller;
			#interrupt-cells = <0x02>;
			gpio-ranges = <0x70 0x00 0x00 0x97>;
			wakeup-parent = <0x86>;
			gpio-reserved-ranges = <0x00 0x04 0x51 0x04>;
			phandle = <0x70>;

			cci0-default-state {
				pins = "gpio17\0gpio18";
				function = "cci_i2c";
				bias-pull-up;
				drive-strength = <0x02>;
				phandle = <0xcb>;
			};

			cci0-sleep-state {
				pins = "gpio17\0gpio18";
				function = "cci_i2c";
				drive-strength = <0x02>;
				bias-pull-down;
				phandle = <0xcd>;
			};

			cci1-default-state {
				pins = "gpio19\0gpio20";
				function = "cci_i2c";
				bias-pull-up;
				drive-strength = <0x02>;
				phandle = <0xcc>;
			};

			cci1-sleep-state {
				pins = "gpio19\0gpio20";
				function = "cci_i2c";
				drive-strength = <0x02>;
				bias-pull-down;
				phandle = <0xce>;
			};

			qspi-clk-state {
				pins = "gpio95";
				function = "qspi_clk";
			};

			qspi-cs0-state {
				pins = "gpio90";
				function = "qspi_cs";
			};

			qspi-cs1-state {
				pins = "gpio89";
				function = "qspi_cs";
			};

			qspi-data0-state {
				pins = "gpio91";
				function = "qspi_data";
			};

			qspi-data1-state {
				pins = "gpio92";
				function = "qspi_data";
			};

			qspi-data23-state {
				pins = "gpio93\0gpio94";
				function = "qspi_data";
			};

			qup-i2c0-default-state {
				pins = "gpio0\0gpio1";
				function = "qup0";
				phandle = <0x3d>;
			};

			qup-i2c1-default-state {
				pins = "gpio17\0gpio18";
				function = "qup1";
				phandle = <0x42>;
			};

			qup-i2c2-default-state {
				pins = "gpio27\0gpio28";
				function = "qup2";
				phandle = <0x45>;
			};

			qup-i2c3-default-state {
				pins = "gpio41\0gpio42";
				function = "qup3";
				phandle = <0x48>;
			};

			qup-i2c4-default-state {
				pins = "gpio89\0gpio90";
				function = "qup4";
				phandle = <0x4b>;
			};

			qup-i2c5-default-state {
				pins = "gpio85\0gpio86";
				function = "qup5";
				phandle = <0x4e>;
			};

			qup-i2c6-default-state {
				pins = "gpio45\0gpio46";
				function = "qup6";
				phandle = <0x51>;
			};

			qup-i2c7-default-state {
				pins = "gpio93\0gpio94";
				function = "qup7";
				phandle = <0x58>;
			};

			qup-i2c8-default-state {
				pins = "gpio65\0gpio66";
				function = "qup8";
				phandle = <0x5c>;
			};

			qup-i2c9-default-state {
				pins = "gpio6\0gpio7";
				function = "qup9";
				phandle = <0x60>;
			};

			qup-i2c10-default-state {
				pins = "gpio55\0gpio56";
				function = "qup10";
				phandle = <0x63>;
			};

			qup-i2c11-default-state {
				pins = "gpio31\0gpio32";
				function = "qup11";
				phandle = <0x66>;
			};

			qup-i2c12-default-state {
				pins = "gpio49\0gpio50";
				function = "qup12";
				phandle = <0x69>;
			};

			qup-i2c13-default-state {
				pins = "gpio105\0gpio106";
				function = "qup13";
				phandle = <0x6c>;
			};

			qup-i2c14-default-state {
				pins = "gpio33\0gpio34";
				function = "qup14";
				drive-strength = <0x02>;
				bias-disable;
				phandle = <0x6f>;
			};

			qup-i2c15-default-state {
				pins = "gpio81\0gpio82";
				function = "qup15";
				phandle = <0x76>;
			};

			qup-spi0-default-state {
				pins = "gpio0\0gpio1\0gpio2\0gpio3";
				function = "qup0";
				phandle = <0x40>;
			};

			qup-spi1-default-state {
				pins = "gpio17\0gpio18\0gpio19\0gpio20";
				function = "qup1";
				phandle = <0x43>;
			};

			qup-spi2-default-state {
				pins = "gpio27\0gpio28\0gpio29\0gpio30";
				function = "qup2";
				phandle = <0x46>;
			};

			qup-spi3-default-state {
				pins = "gpio41\0gpio42\0gpio43\0gpio44";
				function = "qup3";
				phandle = <0x49>;
			};

			qup-spi4-default-state {
				pins = "gpio89\0gpio90\0gpio91\0gpio92";
				function = "qup4";
				phandle = <0x4c>;
			};

			qup-spi5-default-state {
				pins = "gpio85\0gpio86\0gpio87\0gpio88";
				function = "qup5";
				phandle = <0x4f>;
			};

			qup-spi6-default-state {
				pins = "gpio45\0gpio46\0gpio47\0gpio48";
				function = "qup6";
				phandle = <0x52>;
			};

			qup-spi7-default-state {
				pins = "gpio93\0gpio94\0gpio95\0gpio96";
				function = "qup7";
				phandle = <0x59>;
			};

			qup-spi8-default-state {
				pins = "gpio65\0gpio66\0gpio67\0gpio68";
				function = "qup8";
				phandle = <0x5e>;
			};

			qup-spi9-default-state {
				pins = "gpio6\0gpio7\0gpio4\0gpio5";
				function = "qup9";
				phandle = <0x61>;
			};

			qup-spi10-default-state {
				pins = "gpio55\0gpio56\0gpio53\0gpio54";
				function = "qup10";
				phandle = <0x64>;
			};

			qup-spi11-default-state {
				pins = "gpio31\0gpio32\0gpio33\0gpio34";
				function = "qup11";
				phandle = <0x67>;
			};

			qup-spi12-default-state {
				pins = "gpio49\0gpio50\0gpio51\0gpio52";
				function = "qup12";
				phandle = <0x6a>;
			};

			qup-spi13-default-state {
				pins = "gpio105\0gpio106\0gpio107\0gpio108";
				function = "qup13";
				phandle = <0x6d>;
			};

			qup-spi14-default-state {
				pins = "gpio33\0gpio34\0gpio31\0gpio32";
				function = "qup14";
				phandle = <0x74>;
			};

			qup-spi15-default-state {
				pins = "gpio81\0gpio82\0gpio83\0gpio84";
				function = "qup15";
				phandle = <0x77>;
			};

			qup-uart0-default-state {
				phandle = <0x41>;

				tx-pins {
					pins = "gpio2";
					function = "qup0";
				};

				rx-pins {
					pins = "gpio3";
					function = "qup0";
				};
			};

			qup-uart1-default-state {
				phandle = <0x44>;

				tx-pins {
					pins = "gpio19";
					function = "qup1";
				};

				rx-pins {
					pins = "gpio20";
					function = "qup1";
				};
			};

			qup-uart2-default-state {
				phandle = <0x47>;

				tx-pins {
					pins = "gpio29";
					function = "qup2";
				};

				rx-pins {
					pins = "gpio30";
					function = "qup2";
				};
			};

			qup-uart3-default-state {
				phandle = <0x4a>;

				tx-pins {
					pins = "gpio43";
					function = "qup3";
				};

				rx-pins {
					pins = "gpio44";
					function = "qup3";
				};
			};

			qup-uart3-4pin-state {

				cts-pins {
					pins = "gpio41";
					function = "qup3";
				};

				rts-tx-pins {
					pins = "gpio42\0gpio43";
					function = "qup3";
				};

				rx-pins {
					pins = "gpio44";
					function = "qup3";
				};
			};

			qup-uart4-default-state {
				phandle = <0x4d>;

				tx-pins {
					pins = "gpio91";
					function = "qup4";
				};

				rx-pins {
					pins = "gpio92";
					function = "qup4";
				};
			};

			qup-uart5-default-state {
				phandle = <0x50>;

				tx-pins {
					pins = "gpio87";
					function = "qup5";
				};

				rx-pins {
					pins = "gpio88";
					function = "qup5";
				};
			};

			qup-uart6-default-state {

				tx-pins {
					pins = "gpio47";
					function = "qup6";
				};

				rx-pins {
					pins = "gpio48";
					function = "qup6";
				};
			};

			qup-uart6-4pin-state {
				phandle = <0x53>;

				cts-pins {
					pins = "gpio45";
					function = "qup6";
					bias-pull-down;
				};

				rts-tx-pins {
					pins = "gpio46\0gpio47";
					function = "qup6";
					drive-strength = <0x02>;
					bias-disable;
				};

				rx-pins {
					pins = "gpio48";
					function = "qup6";
					bias-pull-up;
				};
			};

			qup-uart7-default-state {
				phandle = <0x5a>;

				tx-pins {
					pins = "gpio95";
					function = "qup7";
				};

				rx-pins {
					pins = "gpio96";
					function = "qup7";
				};
			};

			qup-uart8-default-state {
				phandle = <0x5f>;

				tx-pins {
					pins = "gpio67";
					function = "qup8";
				};

				rx-pins {
					pins = "gpio68";
					function = "qup8";
				};
			};

			qup-uart9-default-state {
				phandle = <0x62>;

				tx-pins {
					pins = "gpio4";
					function = "qup9";
					drive-strength = <0x02>;
					bias-disable;
				};

				rx-pins {
					pins = "gpio5";
					function = "qup9";
					drive-strength = <0x02>;
					bias-pull-up;
				};
			};

			qup-uart10-default-state {
				phandle = <0x65>;

				tx-pins {
					pins = "gpio53";
					function = "qup10";
				};

				rx-pins {
					pins = "gpio54";
					function = "qup10";
				};
			};

			qup-uart11-default-state {
				phandle = <0x68>;

				tx-pins {
					pins = "gpio33";
					function = "qup11";
				};

				rx-pins {
					pins = "gpio34";
					function = "qup11";
				};
			};

			qup-uart12-default-state {
				phandle = <0x6b>;

				tx-pins {
					pins = "gpio51";
					function = "qup0";
				};

				rx-pins {
					pins = "gpio52";
					function = "qup0";
				};
			};

			qup-uart13-default-state {
				phandle = <0x6e>;

				tx-pins {
					pins = "gpio107";
					function = "qup13";
				};

				rx-pins {
					pins = "gpio108";
					function = "qup13";
				};
			};

			qup-uart14-default-state {
				phandle = <0x75>;

				tx-pins {
					pins = "gpio31";
					function = "qup14";
				};

				rx-pins {
					pins = "gpio32";
					function = "qup14";
				};
			};

			qup-uart15-default-state {
				phandle = <0x78>;

				tx-pins {
					pins = "gpio83";
					function = "qup15";
				};

				rx-pins {
					pins = "gpio84";
					function = "qup15";
				};
			};

			quat-mi2s-sleep-state {
				pins = "gpio58\0gpio59";
				function = "gpio";
				drive-strength = <0x02>;
				bias-pull-down;
			};

			quat-mi2s-active-state {
				pins = "gpio58\0gpio59";
				function = "qua_mi2s";
				drive-strength = <0x08>;
				bias-disable;
				output-high;
				phandle = <0xfe>;
			};

			quat-mi2s-sd0-sleep-state {
				pins = "gpio60";
				function = "gpio";
				drive-strength = <0x02>;
				bias-pull-down;
			};

			quat-mi2s-sd0-active-state {
				pins = "gpio60";
				function = "qua_mi2s";
				drive-strength = <0x08>;
				bias-disable;
				phandle = <0xff>;
			};

			quat-mi2s-sd1-sleep-state {
				pins = "gpio61";
				function = "gpio";
				drive-strength = <0x02>;
				bias-pull-down;
			};

			quat-mi2s-sd1-active-state {
				pins = "gpio61";
				function = "qua_mi2s";
				drive-strength = <0x08>;
				bias-disable;
				phandle = <0x100>;
			};

			quat-mi2s-sd2-sleep-state {
				pins = "gpio62";
				function = "gpio";
				drive-strength = <0x02>;
				bias-pull-down;
			};

			quat-mi2s-sd2-active-state {
				pins = "gpio62";
				function = "qua_mi2s";
				drive-strength = <0x08>;
				bias-disable;
			};

			quat-mi2s-sd3-sleep-state {
				pins = "gpio63";
				function = "gpio";
				drive-strength = <0x02>;
				bias-pull-down;
			};

			quat-mi2s-sd3-active-state {
				pins = "gpio63";
				function = "qua_mi2s";
				drive-strength = <0x08>;
				bias-disable;
			};

			wcd-intr-default-state {
				pins = "gpio54";
				function = "gpio";
				bias-pull-down;
				drive-strength = <0x02>;
				phandle = <0xb8>;
			};

			vci-state {
				pins = "gpio26";
				function = "gpio";
				drive-strength = <0x08>;
				bias-disable;
				phandle = <0x10c>;
			};

			poc-state {
				pins = "gpio25";
				function = "gpio";
				drive-strength = <0x08>;
				bias-disable;
				phandle = <0x10d>;
			};

			panel-default-state {
				phandle = <0xe0>;

				esd-pins {
					pins = "gpio30";
					function = "gpio";
					drive-strength = <0x02>;
					bias-pull-down;
				};

				reset-pins {
					pins = "gpio6";
					function = "gpio";
					drive-strength = <0x08>;
					bias-disable;
				};

				te-pins {
					pins = "gpio10";
					function = "mdp_vsync";
					drive-strength = <0x02>;
					bias-disable;
				};
			};

			panel-sleep-state {
				phandle = <0xe1>;

				esd-pins {
					pins = "gpio30";
					function = "gpio";
					drive-strength = <0x02>;
					bias-pull-down;
				};

				reset-pins {
					pins = "gpio6";
					function = "gpio";
					drive-strength = <0x02>;
					bias-pull-down;
				};

				te-pins {
					pins = "gpio10";
					function = "mdp_vsync";
					drive-strength = <0x02>;
					bias-disable;
				};
			};

			ts-int-state {
				pins = "gpio31\0gpio32";
				function = "gpio";
				drive-strength = <0x10>;
				bias-pull-up;
				phandle = <0x71>;
			};
		};

		remoteproc@4080000 {
			compatible = "qcom,sdm845-mss-pil";
			reg = <0x00 0x4080000 0x00 0x408 0x00 0x4180000 0x00 0x48>;
			reg-names = "qdsp6\0rmb";
			interrupts-extended = <0x01 0x00 0x10a 0x01 0x87 0x00 0x01 0x87 0x01 0x01 0x87 0x02 0x01 0x87 0x03 0x01 0x87 0x07 0x01>;
			interrupt-names = "wdog\0fatal\0ready\0handover\0stop-ack\0shutdown-ack";
			clocks = <0x3a 0x24 0x3a 0x27 0x3a 0x05 0x3a 0x25 0x3a 0x28 0x3a 0x26 0x3a 0x40 0x2d 0x00>;
			clock-names = "iface\0bus\0mem\0gpll0_mss\0snoc_axi\0mnoc_axi\0prng\0xo";
			qcom,qmp = <0x2f>;
			qcom,smem-states = <0x88 0x00>;
			qcom,smem-state-names = "stop";
			resets = <0x89 0x00 0x8a 0x09>;
			reset-names = "mss_restart\0pdc_reset";
			qcom,halt-regs = <0x8b 0x3000 0x5000 0x4000>;
			power-domains = <0x39 0x03 0x39 0x01 0x39 0x08>;
			power-domain-names = "cx\0mx\0mss";
			status = "okay";
			firmware-name = "qcom/sdm845/Razer/aura/mba.mbn\0qcom/sdm845/Razer/aura/modem.mbn";
			qcom,fih-nv-memory-region = <0x8c>;

			mba {
				memory-region = <0x8d>;
			};

			mpss {
				memory-region = <0x8e>;
			};

			metadata {
				memory-region = <0x8f>;
			};

			glink-edge {
				interrupts = <0x00 0x1c1 0x01>;
				label = "modem";
				qcom,remote-pid = <0x01>;
				mboxes = <0x31 0x0c>;
			};
		};

		clock-controller@5090000 {
			compatible = "qcom,sdm845-gpucc";
			reg = <0x00 0x5090000 0x00 0x9000>;
			#clock-cells = <0x01>;
			#reset-cells = <0x01>;
			#power-domain-cells = <0x01>;
			clocks = <0x2d 0x00 0x3a 0x1f 0x3a 0x20>;
			clock-names = "bi_tcxo\0gcc_gpu_gpll0_clk_src\0gcc_gpu_gpll0_div_clk_src";
			phandle = <0xeb>;
		};

		remoteproc@5c00000 {
			compatible = "qcom,sdm845-slpi-pas";
			reg = <0x00 0x5c00000 0x00 0x4000>;
			interrupts-extended = <0x01 0x00 0x1ee 0x01 0x90 0x00 0x01 0x90 0x01 0x01 0x90 0x02 0x01 0x90 0x03 0x01>;
			interrupt-names = "wdog\0fatal\0ready\0handover\0stop-ack";
			clocks = <0x2d 0x00>;
			clock-names = "xo";
			qcom,qmp = <0x2f>;
			power-domains = <0x39 0x06 0x39 0x05>;
			power-domain-names = "lcx\0lmx";
			memory-region = <0x91>;
			qcom,smem-states = <0x92 0x00>;
			qcom,smem-state-names = "stop";
			status = "okay";
			firmware-name = "qcom/sdm845/Razer/aura/slpi.mbn";

			glink-edge {
				interrupts = <0x00 0xaa 0x01>;
				label = "dsps";
				qcom,remote-pid = <0x03>;
				mboxes = <0x31 0x18>;

				fastrpc {
					compatible = "qcom,fastrpc";
					qcom,glink-channels = "fastrpcglink-apps-dsp";
					label = "sdsp";
					qcom,non-secure-domain;
					qcom,vmids = <0x03 0x0f 0x05 0x06>;
					memory-region = <0x93>;
					#address-cells = <0x01>;
					#size-cells = <0x00>;

					compute-cb@0 {
						compatible = "qcom,fastrpc-compute-cb";
						reg = <0x00>;
					};
				};
			};
		};

		stm@6002000 {
			compatible = "arm,coresight-stm\0arm,primecell";
			reg = <0x00 0x6002000 0x00 0x1000 0x00 0x16280000 0x00 0x180000>;
			reg-names = "stm-base\0stm-stimulus-base";
			clocks = <0x2f>;
			clock-names = "apb_pclk";

			out-ports {

				port {

					endpoint {
						remote-endpoint = <0x94>;
						phandle = <0x96>;
					};
				};
			};
		};

		funnel@6041000 {
			compatible = "arm,coresight-dynamic-funnel\0arm,primecell";
			reg = <0x00 0x6041000 0x00 0x1000>;
			clocks = <0x2f>;
			clock-names = "apb_pclk";

			out-ports {

				port {

					endpoint {
						remote-endpoint = <0x95>;
						phandle = <0x9a>;
					};
				};
			};

			in-ports {
				#address-cells = <0x01>;
				#size-cells = <0x00>;

				port@7 {
					reg = <0x07>;

					endpoint {
						remote-endpoint = <0x96>;
						phandle = <0x94>;
					};
				};
			};
		};

		funnel@6043000 {
			compatible = "arm,coresight-dynamic-funnel\0arm,primecell";
			reg = <0x00 0x6043000 0x00 0x1000>;
			clocks = <0x2f>;
			clock-names = "apb_pclk";

			out-ports {

				port {

					endpoint {
						remote-endpoint = <0x97>;
						phandle = <0x9b>;
					};
				};
			};

			in-ports {
				#address-cells = <0x01>;
				#size-cells = <0x00>;

				port@5 {
					reg = <0x05>;

					endpoint {
						remote-endpoint = <0x98>;
						phandle = <0xb2>;
					};
				};
			};
		};

		funnel@6045000 {
			compatible = "arm,coresight-dynamic-funnel\0arm,primecell";
			reg = <0x00 0x6045000 0x00 0x1000>;
			clocks = <0x2f>;
			clock-names = "apb_pclk";

			out-ports {

				port {

					endpoint {
						remote-endpoint = <0x99>;
						phandle = <0x9f>;
					};
				};
			};

			in-ports {
				#address-cells = <0x01>;
				#size-cells = <0x00>;

				port@0 {
					reg = <0x00>;

					endpoint {
						remote-endpoint = <0x9a>;
						phandle = <0x95>;
					};
				};

				port@2 {
					reg = <0x02>;

					endpoint {
						remote-endpoint = <0x9b>;
						phandle = <0x97>;
					};
				};
			};
		};

		replicator@6046000 {
			compatible = "arm,coresight-dynamic-replicator\0arm,primecell";
			reg = <0x00 0x6046000 0x00 0x1000>;
			clocks = <0x2f>;
			clock-names = "apb_pclk";

			out-ports {

				port {

					endpoint {
						remote-endpoint = <0x9c>;
						phandle = <0xa0>;
					};
				};
			};

			in-ports {

				port {

					endpoint {
						remote-endpoint = <0x9d>;
						phandle = <0x9e>;
					};
				};
			};
		};

		etf@6047000 {
			compatible = "arm,coresight-tmc\0arm,primecell";
			reg = <0x00 0x6047000 0x00 0x1000>;
			clocks = <0x2f>;
			clock-names = "apb_pclk";

			out-ports {

				port {

					endpoint {
						remote-endpoint = <0x9e>;
						phandle = <0x9d>;
					};
				};
			};

			in-ports {

				port {

					endpoint {
						remote-endpoint = <0x9f>;
						phandle = <0x99>;
					};
				};
			};
		};

		etr@6048000 {
			compatible = "arm,coresight-tmc\0arm,primecell";
			reg = <0x00 0x6048000 0x00 0x1000>;
			clocks = <0x2f>;
			clock-names = "apb_pclk";
			arm,scatter-gather;

			in-ports {

				port {

					endpoint {
						remote-endpoint = <0xa0>;
						phandle = <0x9c>;
					};
				};
			};
		};

		etm@7040000 {
			compatible = "arm,coresight-etm4x\0arm,primecell";
			reg = <0x00 0x7040000 0x00 0x1000>;
			cpu = <0x1a>;
			clocks = <0x2f>;
			clock-names = "apb_pclk";
			arm,coresight-loses-context-with-cpu;

			out-ports {

				port {

					endpoint {
						remote-endpoint = <0xa1>;
						phandle = <0xaa>;
					};
				};
			};
		};

		etm@7140000 {
			compatible = "arm,coresight-etm4x\0arm,primecell";
			reg = <0x00 0x7140000 0x00 0x1000>;
			cpu = <0x1b>;
			clocks = <0x2f>;
			clock-names = "apb_pclk";
			arm,coresight-loses-context-with-cpu;

			out-ports {

				port {

					endpoint {
						remote-endpoint = <0xa2>;
						phandle = <0xab>;
					};
				};
			};
		};

		etm@7240000 {
			compatible = "arm,coresight-etm4x\0arm,primecell";
			reg = <0x00 0x7240000 0x00 0x1000>;
			cpu = <0x1c>;
			clocks = <0x2f>;
			clock-names = "apb_pclk";
			arm,coresight-loses-context-with-cpu;

			out-ports {

				port {

					endpoint {
						remote-endpoint = <0xa3>;
						phandle = <0xac>;
					};
				};
			};
		};

		etm@7340000 {
			compatible = "arm,coresight-etm4x\0arm,primecell";
			reg = <0x00 0x7340000 0x00 0x1000>;
			cpu = <0x1d>;
			clocks = <0x2f>;
			clock-names = "apb_pclk";
			arm,coresight-loses-context-with-cpu;

			out-ports {

				port {

					endpoint {
						remote-endpoint = <0xa4>;
						phandle = <0xad>;
					};
				};
			};
		};

		etm@7440000 {
			compatible = "arm,coresight-etm4x\0arm,primecell";
			reg = <0x00 0x7440000 0x00 0x1000>;
			cpu = <0x1e>;
			clocks = <0x2f>;
			clock-names = "apb_pclk";
			arm,coresight-loses-context-with-cpu;

			out-ports {

				port {

					endpoint {
						remote-endpoint = <0xa5>;
						phandle = <0xae>;
					};
				};
			};
		};

		etm@7540000 {
			compatible = "arm,coresight-etm4x\0arm,primecell";
			reg = <0x00 0x7540000 0x00 0x1000>;
			cpu = <0x1f>;
			clocks = <0x2f>;
			clock-names = "apb_pclk";
			arm,coresight-loses-context-with-cpu;

			out-ports {

				port {

					endpoint {
						remote-endpoint = <0xa6>;
						phandle = <0xaf>;
					};
				};
			};
		};

		etm@7640000 {
			compatible = "arm,coresight-etm4x\0arm,primecell";
			reg = <0x00 0x7640000 0x00 0x1000>;
			cpu = <0x20>;
			clocks = <0x2f>;
			clock-names = "apb_pclk";
			arm,coresight-loses-context-with-cpu;

			out-ports {

				port {

					endpoint {
						remote-endpoint = <0xa7>;
						phandle = <0xb0>;
					};
				};
			};
		};

		etm@7740000 {
			compatible = "arm,coresight-etm4x\0arm,primecell";
			reg = <0x00 0x7740000 0x00 0x1000>;
			cpu = <0x21>;
			clocks = <0x2f>;
			clock-names = "apb_pclk";
			arm,coresight-loses-context-with-cpu;

			out-ports {

				port {

					endpoint {
						remote-endpoint = <0xa8>;
						phandle = <0xb1>;
					};
				};
			};
		};

		funnel@7800000 {
			compatible = "arm,coresight-dynamic-funnel\0arm,primecell";
			reg = <0x00 0x7800000 0x00 0x1000>;
			clocks = <0x2f>;
			clock-names = "apb_pclk";

			out-ports {

				port {

					endpoint {
						remote-endpoint = <0xa9>;
						phandle = <0xb3>;
					};
				};
			};

			in-ports {
				#address-cells = <0x01>;
				#size-cells = <0x00>;

				port@0 {
					reg = <0x00>;

					endpoint {
						remote-endpoint = <0xaa>;
						phandle = <0xa1>;
					};
				};

				port@1 {
					reg = <0x01>;

					endpoint {
						remote-endpoint = <0xab>;
						phandle = <0xa2>;
					};
				};

				port@2 {
					reg = <0x02>;

					endpoint {
						remote-endpoint = <0xac>;
						phandle = <0xa3>;
					};
				};

				port@3 {
					reg = <0x03>;

					endpoint {
						remote-endpoint = <0xad>;
						phandle = <0xa4>;
					};
				};

				port@4 {
					reg = <0x04>;

					endpoint {
						remote-endpoint = <0xae>;
						phandle = <0xa5>;
					};
				};

				port@5 {
					reg = <0x05>;

					endpoint {
						remote-endpoint = <0xaf>;
						phandle = <0xa6>;
					};
				};

				port@6 {
					reg = <0x06>;

					endpoint {
						remote-endpoint = <0xb0>;
						phandle = <0xa7>;
					};
				};

				port@7 {
					reg = <0x07>;

					endpoint {
						remote-endpoint = <0xb1>;
						phandle = <0xa8>;
					};
				};
			};
		};

		funnel@7810000 {
			compatible = "arm,coresight-dynamic-funnel\0arm,primecell";
			reg = <0x00 0x7810000 0x00 0x1000>;
			clocks = <0x2f>;
			clock-names = "apb_pclk";

			out-ports {

				port {

					endpoint {
						remote-endpoint = <0xb2>;
						phandle = <0x98>;
					};
				};
			};

			in-ports {

				port {

					endpoint {
						remote-endpoint = <0xb3>;
						phandle = <0xa9>;
					};
				};
			};
		};

		mmc@8804000 {
			compatible = "qcom,sdm845-sdhci\0qcom,sdhci-msm-v5";
			reg = <0x00 0x8804000 0x00 0x1000>;
			interrupts = <0x00 0xcc 0x04 0x00 0xde 0x04>;
			interrupt-names = "hc_irq\0pwr_irq";
			clocks = <0x3a 0x68 0x3a 0x69 0x2d 0x00>;
			clock-names = "iface\0core\0xo";
			iommus = <0x32 0xa0 0x0f>;
			power-domains = <0x39 0x03>;
			operating-points-v2 = <0xb4>;
			status = "disabled";

			opp-table {
				compatible = "operating-points-v2";
				phandle = <0xb4>;

				opp-9600000 {
					opp-hz = <0x00 0x927c00>;
					required-opps = <0x22>;
				};

				opp-19200000 {
					opp-hz = <0x00 0x124f800>;
					required-opps = <0x23>;
				};

				opp-100000000 {
					opp-hz = <0x00 0x5f5e100>;
					required-opps = <0x24>;
				};

				opp-201500000 {
					opp-hz = <0x00 0xc02a560>;
					required-opps = <0x25>;
				};
			};
		};

		spi@88df000 {
			compatible = "qcom,sdm845-qspi\0qcom,qspi-v1";
			reg = <0x00 0x88df000 0x00 0x600>;
			iommus = <0x32 0x160 0x00>;
			#address-cells = <0x01>;
			#size-cells = <0x00>;
			interrupts = <0x00 0x52 0x04>;
			clocks = <0x3a 0xbd 0x3a 0xbc>;
			clock-names = "iface\0core";
			power-domains = <0x39 0x03>;
			operating-points-v2 = <0xb5>;
			status = "disabled";
		};

		slim-ngd@171c0000 {
			compatible = "qcom,slim-ngd-v2.1.0";
			reg = <0x00 0x171c0000 0x00 0x2c000>;
			interrupts = <0x00 0xa3 0x04>;
			dmas = <0xb6 0x03 0xb6 0x04>;
			dma-names = "rx\0tx";
			iommus = <0x32 0x1806 0x00>;
			#address-cells = <0x01>;
			#size-cells = <0x00>;
			status = "disabled";

			slim@1 {
				reg = <0x01>;
				#address-cells = <0x02>;
				#size-cells = <0x00>;

				ifd@0,0 {
					compatible = "slim217,250";
					reg = <0x00 0x00>;
					phandle = <0xb7>;
				};

				codec@1,0 {
					compatible = "slim217,250";
					reg = <0x01 0x00>;
					slim-ifc-dev = <0xb7>;
					#sound-dai-cells = <0x01>;
					interrupts-extended = <0x70 0x36 0x04>;
					interrupt-controller;
					#interrupt-cells = <0x01>;
					clock-names = "extclk";
					clocks = <0x2d 0x02>;
					#clock-cells = <0x00>;
					clock-frequency = <0x927c00>;
					clock-output-names = "mclk";
					pinctrl-0 = <0xb8>;
					pinctrl-names = "default";
					qcom,micbias1-microvolt = <0x2932e0>;
					qcom,micbias2-microvolt = <0x2932e0>;
					qcom,micbias3-microvolt = <0x2932e0>;
					qcom,micbias4-microvolt = <0x2932e0>;
					#address-cells = <0x01>;
					#size-cells = <0x01>;
					status = "disabled";
					reset-gpios = <0x70 0x40 0x00>;
					vdd-buck-supply = <0x54>;
					vdd-buck-sido-supply = <0x54>;
					vdd-tx-supply = <0x54>;
					vdd-rx-supply = <0x54>;
					vdd-io-supply = <0x54>;
					phandle = <0xb9>;

					gpio-controller@42 {
						compatible = "qcom,wcd9340-gpio";
						gpio-controller;
						#gpio-cells = <0x02>;
						reg = <0x42 0x02>;
					};

					soundwire@c85 {
						compatible = "qcom,soundwire-v1.3.0";
						reg = <0xc85 0x40>;
						interrupts-extended = <0xb9 0x14>;
						qcom,dout-ports = <0x06>;
						qcom,din-ports = <0x02>;
						qcom,ports-sinterval-low = <0x71f3f07 0x1f3f0f0f>;
						qcom,ports-offset1 = <0x1020c06 0x120d070a>;
						qcom,ports-offset2 = <0x1f00 0x1f0000>;
						#sound-dai-cells = <0x01>;
						clocks = <0xb9>;
						clock-names = "iface";
						#address-cells = <0x02>;
						#size-cells = <0x00>;
					};
				};
			};
		};

		lmh@17d70800 {
			compatible = "qcom,sdm845-lmh";
			reg = <0x00 0x17d70800 0x00 0x400>;
			interrupts = <0x00 0x21 0x04>;
			cpus = <0x1e>;
			qcom,lmh-temp-arm-millicelsius = <0xfde8>;
			qcom,lmh-temp-low-millicelsius = <0x17124>;
			qcom,lmh-temp-high-millicelsius = <0x17318>;
			interrupt-controller;
			#interrupt-cells = <0x01>;
			phandle = <0xfa>;
		};

		lmh@17d78800 {
			compatible = "qcom,sdm845-lmh";
			reg = <0x00 0x17d78800 0x00 0x400>;
			interrupts = <0x00 0x20 0x04>;
			cpus = <0x1a>;
			qcom,lmh-temp-arm-millicelsius = <0xfde8>;
			qcom,lmh-temp-low-millicelsius = <0x17124>;
			qcom,lmh-temp-high-millicelsius = <0x17318>;
			interrupt-controller;
			#interrupt-cells = <0x01>;
			phandle = <0xf9>;
		};

		phy@88e2000 {
			compatible = "qcom,sdm845-qusb2-phy\0qcom,qusb2-v2-phy";
			reg = <0x00 0x88e2000 0x00 0x400>;
			status = "okay";
			#phy-cells = <0x00>;
			clocks = <0x3a 0xa1 0x2d 0x00>;
			clock-names = "cfg_ahb\0ref";
			resets = <0x3a 0x08>;
			nvmem-cells = <0xba>;
			vdd-supply = <0xbb>;
			vdda-pll-supply = <0xbc>;
			vdda-phy-dpdm-supply = <0xbd>;
			qcom,imp-res-offset-value = <0x08>;
			qcom,hstx-trim-value = <0x04>;
			qcom,preemphasis-level = <0x01>;
			qcom,preemphasis-width = <0x01>;
			phandle = <0xc1>;
		};

		phy@88e3000 {
			compatible = "qcom,sdm845-qusb2-phy\0qcom,qusb2-v2-phy";
			reg = <0x00 0x88e3000 0x00 0x400>;
			status = "disabled";
			#phy-cells = <0x00>;
			clocks = <0x3a 0xa1 0x2d 0x00>;
			clock-names = "cfg_ahb\0ref";
			resets = <0x3a 0x09>;
			nvmem-cells = <0xbe>;
			phandle = <0xc3>;
		};

		phy@88e8000 {
			compatible = "qcom,sdm845-qmp-usb3-dp-phy";
			reg = <0x00 0x88e8000 0x00 0x3000>;
			status = "disabled";
			clocks = <0x3a 0x98 0x3a 0x97 0x3a 0x9a 0x3a 0x9b 0x3a 0xa1>;
			clock-names = "aux\0ref\0com_aux\0usb3_pipe\0cfg_ahb";
			resets = <0x3a 0x11 0x3a 0x13>;
			reset-names = "phy\0common";
			#clock-cells = <0x01>;
			#phy-cells = <0x01>;
			orientation-switch;
			phandle = <0xd5>;

			ports {
				#address-cells = <0x01>;
				#size-cells = <0x00>;

				port@0 {
					reg = <0x00>;

					endpoint {
					};
				};

				port@1 {
					reg = <0x01>;

					endpoint {
						remote-endpoint = <0xbf>;
						phandle = <0xc2>;
					};
				};

				port@2 {
					reg = <0x02>;

					endpoint {
						remote-endpoint = <0xc0>;
						phandle = <0xd8>;
					};
				};
			};
		};

		phy@88eb000 {
			compatible = "qcom,sdm845-qmp-usb3-uni-phy";
			reg = <0x00 0x88eb000 0x00 0x1000>;
			clocks = <0x3a 0x9d 0x3a 0xa1 0x3a 0x9c 0x3a 0xa0 0x3a 0x9f>;
			clock-names = "aux\0cfg_ahb\0ref\0com_aux\0pipe";
			clock-output-names = "usb3_uni_phy_pipe_clk_src";
			#clock-cells = <0x00>;
			#phy-cells = <0x00>;
			resets = <0x3a 0x14 0x3a 0x15>;
			reset-names = "phy\0phy_phy";
			status = "disabled";
			phandle = <0xc4>;
		};

		usb@a6f8800 {
			compatible = "qcom,sdm845-dwc3\0qcom,dwc3";
			reg = <0x00 0xa6f8800 0x00 0x400>;
			status = "okay";
			#address-cells = <0x02>;
			#size-cells = <0x02>;
			ranges;
			dma-ranges;
			clocks = <0x3a 0x0c 0x3a 0x8d 0x3a 0x03 0x3a 0x91 0x3a 0x8f>;
			clock-names = "cfg_noc\0core\0iface\0sleep\0mock_utmi";
			assigned-clocks = <0x3a 0x8f 0x3a 0x8d>;
			assigned-clock-rates = <0x124f800 0x8f0d180>;
			interrupts-extended = <0x01 0x00 0x82 0x04 0x01 0x00 0x83 0x04 0x86 0x09 0x03 0x86 0x08 0x03 0x86 0x06 0x04>;
			interrupt-names = "pwr_event\0hs_phy_irq\0dp_hs_phy_irq\0dm_hs_phy_irq\0ss_phy_irq";
			power-domains = <0x3a 0x04>;
			resets = <0x3a 0x0f>;
			interconnects = <0x5b 0x07 0x00 0x06 0x0e 0x00 0x05 0x00 0x00 0x3c 0x29 0x00>;
			interconnect-names = "usb-ddr\0apps-usb";
			qcom,select-utmi-as-pipe-clk;

			usb@a600000 {
				compatible = "snps,dwc3";
				reg = <0x00 0xa600000 0x00 0xcd00>;
				interrupts = <0x00 0x85 0x04>;
				iommus = <0x32 0x740 0x00>;
				snps,dis_u2_susphy_quirk;
				snps,dis_enblslpm_quirk;
				snps,parkmode-disable-ss-quirk;
				snps,dis-u1-entry-quirk;
				snps,dis-u2-entry-quirk;
				phys = <0xc1>;
				phy-names = "usb2-phy";
				dr_mode = "peripheral";
				maximum-speed = "high-speed";

				ports {
					#address-cells = <0x01>;
					#size-cells = <0x00>;

					port@0 {
						reg = <0x00>;

						endpoint {
						};
					};

					port@1 {
						reg = <0x01>;

						endpoint {
							remote-endpoint = <0xc2>;
							phandle = <0xbf>;
						};
					};
				};
			};
		};

		usb@a8f8800 {
			compatible = "qcom,sdm845-dwc3\0qcom,dwc3";
			reg = <0x00 0xa8f8800 0x00 0x400>;
			status = "disabled";
			#address-cells = <0x02>;
			#size-cells = <0x02>;
			ranges;
			dma-ranges;
			clocks = <0x3a 0x0d 0x3a 0x92 0x3a 0x04 0x3a 0x96 0x3a 0x94>;
			clock-names = "cfg_noc\0core\0iface\0sleep\0mock_utmi";
			assigned-clocks = <0x3a 0x94 0x3a 0x92>;
			assigned-clock-rates = <0x124f800 0x8f0d180>;
			interrupts-extended = <0x01 0x00 0x87 0x04 0x01 0x00 0x88 0x04 0x86 0x0b 0x03 0x86 0x0a 0x03 0x86 0x07 0x04>;
			interrupt-names = "pwr_event\0hs_phy_irq\0dp_hs_phy_irq\0dm_hs_phy_irq\0ss_phy_irq";
			power-domains = <0x3a 0x05>;
			resets = <0x3a 0x10>;
			interconnects = <0x5b 0x08 0x00 0x06 0x0e 0x00 0x05 0x00 0x00 0x3c 0x2a 0x00>;
			interconnect-names = "usb-ddr\0apps-usb";

			usb@a800000 {
				compatible = "snps,dwc3";
				reg = <0x00 0xa800000 0x00 0xcd00>;
				interrupts = <0x00 0x8a 0x04>;
				iommus = <0x32 0x760 0x00>;
				snps,dis_u2_susphy_quirk;
				snps,dis_enblslpm_quirk;
				snps,parkmode-disable-ss-quirk;
				snps,dis-u1-entry-quirk;
				snps,dis-u2-entry-quirk;
				phys = <0xc3 0xc4>;
				phy-names = "usb2-phy\0usb3-phy";
			};
		};

		video-codec@aa00000 {
			compatible = "qcom,sdm845-venus-v2";
			reg = <0x00 0xaa00000 0x00 0xff000>;
			interrupts = <0x00 0xae 0x04>;
			power-domains = <0xc5 0x00 0xc5 0x01 0xc5 0x02 0x39 0x03>;
			power-domain-names = "venus\0vcodec0\0vcodec1\0cx";
			operating-points-v2 = <0xc6>;
			clocks = <0xc5 0x0b 0xc5 0x08 0xc5 0x0a 0xc5 0x05 0xc5 0x04 0xc5 0x07 0xc5 0x06>;
			clock-names = "core\0iface\0bus\0vcodec0_core\0vcodec0_bus\0vcodec1_core\0vcodec1_bus";
			iommus = <0x32 0x10a0 0x08 0x32 0x10b0 0x00>;
			memory-region = <0xc7>;
			interconnects = <0xc8 0x07 0x00 0x06 0x0e 0x00 0x05 0x00 0x00 0x3c 0x2b 0x00>;
			interconnect-names = "video-mem\0cpu-cfg";
			status = "disabled";
			firmware-name = "qcom/sdm845/Razer/aura/venus.mbn";

			video-core0 {
				compatible = "venus-decoder";
			};

			video-core1 {
				compatible = "venus-encoder";
			};

			opp-table {
				compatible = "operating-points-v2";
				phandle = <0xc6>;

				opp-100000000 {
					opp-hz = <0x00 0x5f5e100>;
					required-opps = <0x22>;
				};

				opp-200000000 {
					opp-hz = <0x00 0xbebc200>;
					required-opps = <0x23>;
				};

				opp-320000000 {
					opp-hz = <0x00 0x1312d000>;
					required-opps = <0x24>;
				};

				opp-380000000 {
					opp-hz = <0x00 0x16a65700>;
					required-opps = <0x25>;
				};

				opp-444000000 {
					opp-hz = <0x00 0x1a76e700>;
					required-opps = <0x26>;
				};

				opp-533000097 {
					opp-hz = <0x00 0x1fc4efa1>;
					required-opps = <0xc9>;
				};
			};
		};

		clock-controller@ab00000 {
			compatible = "qcom,sdm845-videocc";
			reg = <0x00 0xab00000 0x00 0x10000>;
			clocks = <0x2d 0x00>;
			clock-names = "bi_tcxo";
			#clock-cells = <0x01>;
			#power-domain-cells = <0x01>;
			#reset-cells = <0x01>;
			phandle = <0xc5>;
		};

		camss@acb3000 {
			compatible = "qcom,sdm845-camss";
			reg = <0x00 0xacb3000 0x00 0x1000 0x00 0xacba000 0x00 0x1000 0x00 0xacc8000 0x00 0x1000 0x00 0xac65000 0x00 0x1000 0x00 0xac66000 0x00 0x1000 0x00 0xac67000 0x00 0x1000 0x00 0xac68000 0x00 0x1000 0x00 0xacaf000 0x00 0x4000 0x00 0xacb6000 0x00 0x4000 0x00 0xacc4000 0x00 0x4000>;
			reg-names = "csid0\0csid1\0csid2\0csiphy0\0csiphy1\0csiphy2\0csiphy3\0vfe0\0vfe1\0vfe_lite";
			interrupts = <0x00 0x1d0 0x01 0x00 0x1d2 0x01 0x00 0x1d4 0x01 0x00 0x1dd 0x01 0x00 0x1de 0x01 0x00 0x1df 0x01 0x00 0x1c0 0x01 0x00 0x1d1 0x01 0x00 0x1d3 0x01 0x00 0x1d5 0x01>;
			interrupt-names = "csid0\0csid1\0csid2\0csiphy0\0csiphy1\0csiphy2\0csiphy3\0vfe0\0vfe1\0vfe_lite";
			power-domains = <0xca 0x03 0xca 0x04 0xca 0x05>;
			clocks = <0xca 0x06 0xca 0x09 0xca 0x0a 0xca 0x25 0xca 0x26 0xca 0x2c 0xca 0x2d 0xca 0x32 0xca 0x33 0xca 0x13 0xca 0x0b 0xca 0x0c 0xca 0x14 0xca 0x0d 0xca 0x0e 0xca 0x15 0xca 0x0f 0xca 0x10 0xca 0x16 0xca 0x11 0xca 0x12 0x3a 0x06 0x3a 0x07 0xca 0x52 0xca 0x53 0xca 0x21 0xca 0x22 0xca 0x24 0xca 0x23 0xca 0x28 0xca 0x29 0xca 0x2b 0xca 0x2a 0xca 0x2f 0xca 0x31 0xca 0x30>;
			clock-names = "camnoc_axi\0cpas_ahb\0cphy_rx_src\0csi0\0csi0_src\0csi1\0csi1_src\0csi2\0csi2_src\0csiphy0\0csiphy0_timer\0csiphy0_timer_src\0csiphy1\0csiphy1_timer\0csiphy1_timer_src\0csiphy2\0csiphy2_timer\0csiphy2_timer_src\0csiphy3\0csiphy3_timer\0csiphy3_timer_src\0gcc_camera_ahb\0gcc_camera_axi\0slow_ahb_src\0soc_ahb\0vfe0_axi\0vfe0\0vfe0_cphy_rx\0vfe0_src\0vfe1_axi\0vfe1\0vfe1_cphy_rx\0vfe1_src\0vfe_lite\0vfe_lite_cphy_rx\0vfe_lite_src";
			iommus = <0x32 0x808 0x00 0x32 0x810 0x08 0x32 0xc08 0x00 0x32 0xc10 0x08>;
			status = "disabled";

			ports {
				#address-cells = <0x01>;
				#size-cells = <0x00>;

				port@0 {
					reg = <0x00>;
				};

				port@1 {
					reg = <0x01>;
				};

				port@2 {
					reg = <0x02>;
				};

				port@3 {
					reg = <0x03>;
				};
			};
		};

		cci@ac4a000 {
			compatible = "qcom,sdm845-cci\0qcom,msm8996-cci";
			#address-cells = <0x01>;
			#size-cells = <0x00>;
			reg = <0x00 0xac4a000 0x00 0x4000>;
			interrupts = <0x00 0x1cc 0x01>;
			power-domains = <0xca 0x05>;
			clocks = <0xca 0x06 0xca 0x53 0xca 0x52 0xca 0x09 0xca 0x07 0xca 0x08>;
			clock-names = "camnoc_axi\0soc_ahb\0slow_ahb_src\0cpas_ahb\0cci\0cci_src";
			assigned-clocks = <0xca 0x06 0xca 0x07>;
			assigned-clock-rates = <0x4c4b400 0x23c3460>;
			pinctrl-names = "default\0sleep";
			pinctrl-0 = <0xcb 0xcc>;
			pinctrl-1 = <0xcd 0xce>;
			status = "disabled";

			i2c-bus@0 {
				reg = <0x00>;
				clock-frequency = <0xf4240>;
				#address-cells = <0x01>;
				#size-cells = <0x00>;
			};

			i2c-bus@1 {
				reg = <0x01>;
				clock-frequency = <0xf4240>;
				#address-cells = <0x01>;
				#size-cells = <0x00>;
			};
		};

		clock-controller@ad00000 {
			compatible = "qcom,sdm845-camcc";
			reg = <0x00 0xad00000 0x00 0x10000>;
			#clock-cells = <0x01>;
			#reset-cells = <0x01>;
			#power-domain-cells = <0x01>;
			clocks = <0x2d 0x00>;
			clock-names = "bi_tcxo";
			phandle = <0xca>;
		};

		display-subsystem@ae00000 {
			compatible = "qcom,sdm845-mdss";
			reg = <0x00 0xae00000 0x00 0x1000>;
			reg-names = "mdss";
			power-domains = <0xcf 0x00>;
			clocks = <0xcf 0x00 0xcf 0x0c>;
			clock-names = "iface\0core";
			interrupts = <0x00 0x53 0x04>;
			interrupt-controller;
			#interrupt-cells = <0x01>;
			interconnects = <0xc8 0x04 0x00 0x06 0x0e 0x00 0xc8 0x05 0x00 0x06 0x0e 0x00>;
			interconnect-names = "mdp0-mem\0mdp1-mem";
			iommus = <0x32 0x880 0x08 0x32 0xc80 0x08>;
			status = "disabled";
			#address-cells = <0x02>;
			#size-cells = <0x02>;
			ranges;
			phandle = <0xd1>;

			display-controller@ae01000 {
				compatible = "qcom,sdm845-dpu";
				reg = <0x00 0xae01000 0x00 0x8f000 0x00 0xaeb0000 0x00 0x3000>;
				reg-names = "mdp\0vbif";
				clocks = <0x3a 0x14 0xcf 0x00 0xcf 0x01 0xcf 0x0c 0xcf 0x17>;
				clock-names = "gcc-bus\0iface\0bus\0core\0vsync";
				assigned-clocks = <0xcf 0x17>;
				assigned-clock-rates = <0x124f800>;
				operating-points-v2 = <0xd0>;
				power-domains = <0x39 0x03>;
				interrupt-parent = <0xd1>;
				interrupts = <0x00>;
				status = "disabled";

				ports {
					#address-cells = <0x01>;
					#size-cells = <0x00>;

					port@0 {
						reg = <0x00>;

						endpoint {
							remote-endpoint = <0xd2>;
							phandle = <0xd7>;
						};
					};

					port@1 {
						reg = <0x01>;

						endpoint {
							remote-endpoint = <0xd3>;
							phandle = <0xdb>;
						};
					};

					port@2 {
						reg = <0x02>;

						endpoint {
							remote-endpoint = <0xd4>;
							phandle = <0xe6>;
						};
					};
				};

				opp-table {
					compatible = "operating-points-v2";
					phandle = <0xd0>;

					opp-19200000 {
						opp-hz = <0x00 0x124f800>;
						required-opps = <0x22>;
					};

					opp-171428571 {
						opp-hz = <0x00 0xa37cadb>;
						required-opps = <0x23>;
					};

					opp-344000000 {
						opp-hz = <0x00 0x14810600>;
						required-opps = <0x25>;
					};

					opp-430000000 {
						opp-hz = <0x00 0x19a14780>;
						required-opps = <0x26>;
					};
				};
			};

			displayport-controller@ae90000 {
				status = "disabled";
				compatible = "qcom,sdm845-dp";
				reg = <0x00 0xae90000 0x00 0x200 0x00 0xae90200 0x00 0x200 0x00 0xae90400 0x00 0x600 0x00 0xae90a00 0x00 0x600 0x00 0xae91000 0x00 0x600>;
				interrupt-parent = <0xd1>;
				interrupts = <0x0c>;
				clocks = <0xcf 0x00 0xcf 0x1c 0xcf 0x20 0xcf 0x22 0xcf 0x25>;
				clock-names = "core_iface\0core_aux\0ctrl_link\0ctrl_link_iface\0stream_pixel";
				assigned-clocks = <0xcf 0x21 0xcf 0x26>;
				assigned-clock-parents = <0xd5 0x01 0xd5 0x02>;
				phys = <0xd5 0x01>;
				phy-names = "dp";
				operating-points-v2 = <0xd6>;
				power-domains = <0x39 0x03>;

				ports {
					#address-cells = <0x01>;
					#size-cells = <0x00>;

					port@0 {
						reg = <0x00>;

						endpoint {
							remote-endpoint = <0xd7>;
							phandle = <0xd2>;
						};
					};

					port@1 {
						reg = <0x01>;

						endpoint {
							remote-endpoint = <0xd8>;
							phandle = <0xc0>;
						};
					};
				};

				opp-table {
					compatible = "operating-points-v2";
					phandle = <0xd6>;

					opp-162000000 {
						opp-hz = <0x00 0x9a7ec80>;
						required-opps = <0x23>;
					};

					opp-270000000 {
						opp-hz = <0x00 0x1017df80>;
						required-opps = <0x24>;
					};

					opp-540000000 {
						opp-hz = <0x00 0x202fbf00>;
						required-opps = <0x25>;
					};

					opp-810000000 {
						opp-hz = <0x00 0x30479e80>;
						required-opps = <0x26>;
					};
				};
			};

			dsi@ae94000 {
				compatible = "qcom,sdm845-dsi-ctrl\0qcom,mdss-dsi-ctrl";
				reg = <0x00 0xae94000 0x00 0x400>;
				reg-names = "dsi_ctrl";
				interrupt-parent = <0xd1>;
				interrupts = <0x04>;
				clocks = <0xcf 0x02 0xcf 0x04 0xcf 0x0f 0xcf 0x08 0xcf 0x00 0xcf 0x01>;
				clock-names = "byte\0byte_intf\0pixel\0core\0iface\0bus";
				assigned-clocks = <0xcf 0x03 0xcf 0x10>;
				assigned-clock-parents = <0xd9 0x00 0xd9 0x01>;
				operating-points-v2 = <0xda>;
				power-domains = <0x39 0x03>;
				phys = <0xd9>;
				status = "disabled";
				#address-cells = <0x01>;
				#size-cells = <0x00>;
				qcom,dual-dsi-mode;
				qcom,master-dsi;
				qcom,sync-dual-dsi;
				qcom,mdss-mdp-transfer-time-us = <0x30d4>;

				ports {
					#address-cells = <0x01>;
					#size-cells = <0x00>;

					port@0 {
						reg = <0x00>;

						endpoint {
							remote-endpoint = <0xdb>;
							phandle = <0xd3>;
						};
					};

					port@1 {
						reg = <0x01>;

						endpoint {
							remote-endpoint = <0xdc>;
							data-lanes = <0x00 0x01 0x02 0x03>;
							phandle = <0xe3>;
						};
					};
				};

				panel@0 {
					compatible = "razer,aura-nt36830-panel\0novatek,nt36830";
					reg = <0x00>;
					vddio-supply = <0xdd>;
					vci-supply = <0xde>;
					poc-supply = <0xdf>;
					reset-gpios = <0x70 0x06 0x01>;
					te-gpios = <0x70 0x0a 0x00>;
					pinctrl-0 = <0xe0>;
					pinctrl-1 = <0xe1>;
					pinctrl-names = "default\0sleep";
					backlight = <0xe2>;

					ports {
						#address-cells = <0x01>;
						#size-cells = <0x00>;

						port@0 {
							reg = <0x00>;

							endpoint {
								remote-endpoint = <0xe3>;
								phandle = <0xdc>;
							};
						};

						port@1 {
							reg = <0x01>;

							endpoint {
								remote-endpoint = <0xe4>;
								phandle = <0xe7>;
							};
						};
					};
				};
			};

			phy@ae94400 {
				compatible = "qcom,dsi-phy-10nm";
				reg = <0x00 0xae94400 0x00 0x200 0x00 0xae94600 0x00 0x280 0x00 0xae94a00 0x00 0x1e0>;
				reg-names = "dsi_phy\0dsi_phy_lane\0dsi_pll";
				#clock-cells = <0x01>;
				#phy-cells = <0x00>;
				clocks = <0xcf 0x00 0x2d 0x00>;
				clock-names = "iface\0ref";
				status = "disabled";
				phandle = <0xd9>;
			};

			dsi@ae96000 {
				compatible = "qcom,sdm845-dsi-ctrl\0qcom,mdss-dsi-ctrl";
				reg = <0x00 0xae96000 0x00 0x400>;
				reg-names = "dsi_ctrl";
				interrupt-parent = <0xd1>;
				interrupts = <0x05>;
				clocks = <0xcf 0x05 0xcf 0x07 0xcf 0x11 0xcf 0x0a 0xcf 0x00 0xcf 0x01>;
				clock-names = "byte\0byte_intf\0pixel\0core\0iface\0bus";
				assigned-clocks = <0xcf 0x06 0xcf 0x12>;
				assigned-clock-parents = <0xd9 0x00 0xd9 0x01>;
				operating-points-v2 = <0xda>;
				power-domains = <0x39 0x03>;
				phys = <0xe5>;
				status = "disabled";
				#address-cells = <0x01>;
				#size-cells = <0x00>;
				vdda-supply = <0x80>;
				qcom,dual-dsi-mode;
				qcom,mdss-mdp-transfer-time-us = <0x30d4>;

				ports {
					#address-cells = <0x01>;
					#size-cells = <0x00>;

					port@0 {
						reg = <0x00>;

						endpoint {
							remote-endpoint = <0xe6>;
							phandle = <0xd4>;
						};
					};

					port@1 {
						reg = <0x01>;

						endpoint {
							remote-endpoint = <0xe7>;
							data-lanes = <0x00 0x01 0x02 0x03>;
							phandle = <0xe4>;
						};
					};
				};
			};

			phy@ae96400 {
				compatible = "qcom,dsi-phy-10nm";
				reg = <0x00 0xae96400 0x00 0x200 0x00 0xae96600 0x00 0x280 0x00 0xae96a00 0x00 0x10e>;
				reg-names = "dsi_phy\0dsi_phy_lane\0dsi_pll";
				#clock-cells = <0x01>;
				#phy-cells = <0x00>;
				clocks = <0xcf 0x00 0x2d 0x00>;
				clock-names = "iface\0ref";
				status = "disabled";
				phandle = <0xe5>;
			};
		};

		gpu@5000000 {
			compatible = "qcom,adreno-630.2\0qcom,adreno";
			reg = <0x00 0x5000000 0x00 0x40000 0x00 0x509e000 0x00 0x10>;
			reg-names = "kgsl_3d0_reg_memory\0cx_mem";
			interrupts = <0x00 0x12c 0x04>;
			iommus = <0xe8 0x00>;
			operating-points-v2 = <0xe9>;
			qcom,gmu = <0xea>;
			#cooling-cells = <0x02>;
			interconnects = <0x06 0x07 0x00 0x06 0x0e 0x00>;
			interconnect-names = "gfx-mem";
			status = "disabled";
			phandle = <0x106>;

			opp-table {
				compatible = "operating-points-v2";
				phandle = <0xe9>;

				opp-710000000 {
					opp-hz = <0x00 0x2a51bd80>;
					opp-level = <0x1a0>;
					opp-peak-kBps = <0x6e1b80>;
				};

				opp-675000000 {
					opp-hz = <0x00 0x283baec0>;
					opp-level = <0x180>;
					opp-peak-kBps = <0x6e1b80>;
				};

				opp-596000000 {
					opp-hz = <0x00 0x23863d00>;
					opp-level = <0x140>;
					opp-peak-kBps = <0x5ee8e0>;
				};

				opp-520000000 {
					opp-hz = <0x00 0x1efe9200>;
					opp-level = <0x100>;
					opp-peak-kBps = <0x5ee8e0>;
				};

				opp-414000000 {
					opp-hz = <0x00 0x18ad2380>;
					opp-level = <0xc0>;
					opp-peak-kBps = <0x3e12a0>;
				};

				opp-342000000 {
					opp-hz = <0x00 0x14628180>;
					opp-level = <0x80>;
					opp-peak-kBps = <0x2990a0>;
				};

				opp-257000000 {
					opp-hz = <0x00 0xf518240>;
					opp-level = <0x40>;
					opp-peak-kBps = <0x192580>;
				};
			};
		};

		iommu@5040000 {
			compatible = "qcom,sdm845-smmu-v2\0qcom,adreno-smmu\0qcom,smmu-v2";
			reg = <0x00 0x5040000 0x00 0x10000>;
			#iommu-cells = <0x01>;
			#global-interrupts = <0x02>;
			interrupts = <0x00 0xe5 0x04 0x00 0xe7 0x04 0x00 0x16c 0x01 0x00 0x16d 0x01 0x00 0x16e 0x01 0x00 0x16f 0x01 0x00 0x170 0x01 0x00 0x171 0x01 0x00 0x172 0x01 0x00 0x173 0x01>;
			clocks = <0x3a 0x21 0x3a 0x1e>;
			clock-names = "bus\0iface";
			power-domains = <0xeb 0x00>;
			phandle = <0xe8>;
		};

		gmu@506a000 {
			compatible = "qcom,adreno-gmu-630.2\0qcom,adreno-gmu";
			reg = <0x00 0x506a000 0x00 0x30000 0x00 0xb280000 0x00 0x10000 0x00 0xb480000 0x00 0x10000>;
			reg-names = "gmu\0gmu_pdc\0gmu_pdc_seq";
			interrupts = <0x00 0x130 0x04 0x00 0x131 0x04>;
			interrupt-names = "hfi\0gmu";
			clocks = <0xeb 0x00 0xeb 0x01 0x3a 0x12 0x3a 0x21>;
			clock-names = "gmu\0cxo\0axi\0memnoc";
			power-domains = <0xeb 0x00 0xeb 0x01>;
			power-domain-names = "cx\0gx";
			iommus = <0xe8 0x05>;
			operating-points-v2 = <0xec>;
			phandle = <0xea>;

			opp-table {
				compatible = "operating-points-v2";
				phandle = <0xec>;

				opp-400000000 {
					opp-hz = <0x00 0x17d78400>;
					opp-level = <0x80>;
				};

				opp-200000000 {
					opp-hz = <0x00 0xbebc200>;
					opp-level = <0x30>;
				};
			};
		};

		clock-controller@af00000 {
			compatible = "qcom,sdm845-dispcc";
			reg = <0x00 0xaf00000 0x00 0x10000>;
			clocks = <0x2d 0x00 0x3a 0x15 0x3a 0x16 0xd9 0x00 0xd9 0x01 0xe5 0x00 0xe5 0x01 0xd5 0x01 0xd5 0x02>;
			clock-names = "bi_tcxo\0gcc_disp_gpll0_clk_src\0gcc_disp_gpll0_div_clk_src\0dsi0_phy_pll_out_byteclk\0dsi0_phy_pll_out_dsiclk\0dsi1_phy_pll_out_byteclk\0dsi1_phy_pll_out_dsiclk\0dp_link_clk_divsel_ten\0dp_vco_divided_clk_src_mux";
			#clock-cells = <0x01>;
			#reset-cells = <0x01>;
			#power-domain-cells = <0x01>;
			status = "disabled";
			phandle = <0xcf>;
		};

		interrupt-controller@b220000 {
			compatible = "qcom,sdm845-pdc\0qcom,pdc";
			reg = <0x00 0xb220000 0x00 0x30000>;
			qcom,pdc-ranges = <0x00 0x1e0 0x5e 0x5e 0x261 0x0f 0x73 0x276 0x07>;
			#interrupt-cells = <0x02>;
			interrupt-parent = <0x01>;
			interrupt-controller;
			phandle = <0x86>;
		};

		reset-controller@b2e0000 {
			compatible = "qcom,sdm845-pdc-global";
			reg = <0x00 0xb2e0000 0x00 0x20000>;
			#reset-cells = <0x01>;
			phandle = <0x8a>;
		};

		thermal-sensor@c263000 {
			compatible = "qcom,sdm845-tsens\0qcom,tsens-v2";
			reg = <0x00 0xc263000 0x00 0x1ff 0x00 0xc222000 0x00 0x1ff>;
			#qcom,sensors = <0x0d>;
			interrupts = <0x00 0x1fa 0x04 0x00 0x1fc 0x04>;
			interrupt-names = "uplow\0critical";
			#thermal-sensor-cells = <0x01>;
			phandle = <0x104>;
		};

		thermal-sensor@c265000 {
			compatible = "qcom,sdm845-tsens\0qcom,tsens-v2";
			reg = <0x00 0xc265000 0x00 0x1ff 0x00 0xc223000 0x00 0x1ff>;
			#qcom,sensors = <0x08>;
			interrupts = <0x00 0x1fb 0x04 0x00 0x1fd 0x04>;
			interrupt-names = "uplow\0critical";
			#thermal-sensor-cells = <0x01>;
			phandle = <0x108>;
		};

		reset-controller@c2a0000 {
			compatible = "qcom,sdm845-aoss-cc";
			reg = <0x00 0xc2a0000 0x00 0x31000>;
			#reset-cells = <0x01>;
			phandle = <0x89>;
		};

		power-management@c300000 {
			compatible = "qcom,sdm845-aoss-qmp\0qcom,aoss-qmp";
			reg = <0x00 0xc300000 0x00 0x400>;
			interrupts = <0x00 0x185 0x01>;
			mboxes = <0x31 0x00>;
			#clock-cells = <0x00>;
			phandle = <0x2f>;

			cx {
				#cooling-cells = <0x02>;
			};

			ebi {
				#cooling-cells = <0x02>;
			};
		};

		sram@c3f0000 {
			compatible = "qcom,sdm845-rpmh-stats";
			reg = <0x00 0xc3f0000 0x00 0x400>;
		};

		spmi@c440000 {
			compatible = "qcom,spmi-pmic-arb";
			reg = <0x00 0xc440000 0x00 0x1100 0x00 0xc600000 0x00 0x2000000 0x00 0xe600000 0x00 0x100000 0x00 0xe700000 0x00 0xa0000 0x00 0xc40a000 0x00 0x26000>;
			reg-names = "core\0chnls\0obsrvr\0intr\0cnfg";
			interrupt-names = "periph_irq";
			interrupts = <0x00 0x1e1 0x04>;
			qcom,ee = <0x00>;
			qcom,channel = <0x00>;
			#address-cells = <0x02>;
			#size-cells = <0x00>;
			interrupt-controller;
			#interrupt-cells = <0x04>;

			pmic@0 {
				compatible = "qcom,pm8998\0qcom,spmi-pmic";
				reg = <0x00 0x00>;
				#address-cells = <0x01>;
				#size-cells = <0x00>;

				pon@800 {
					compatible = "qcom,pm8998-pon";
					reg = <0x800>;
					mode-bootloader = <0x02>;
					mode-recovery = <0x01>;

					pwrkey {
						compatible = "qcom,pm8941-pwrkey";
						interrupts = <0x00 0x08 0x00 0x03>;
						debounce = <0x3d09>;
						bias-pull-up;
						linux,code = <0x74>;
					};

					resin {
						compatible = "qcom,pm8941-resin";
						interrupts = <0x00 0x08 0x01 0x03>;
						debounce = <0x3d09>;
						bias-pull-up;
						status = "disabled";
					};
				};

				temp-alarm@2400 {
					compatible = "qcom,spmi-temp-alarm";
					reg = <0x2400>;
					interrupts = <0x00 0x24 0x00 0x01>;
					io-channels = <0xed 0x06>;
					io-channel-names = "thermal";
					#thermal-sensor-cells = <0x00>;
					phandle = <0x109>;
				};

				charger@2800 {
					compatible = "qcom,pm8998-coincell\0qcom,pm8941-coincell";
					reg = <0x2800>;
					status = "disabled";
				};

				adc@3100 {
					compatible = "qcom,spmi-adc-rev2";
					reg = <0x3100>;
					interrupts = <0x00 0x31 0x00 0x01>;
					#address-cells = <0x01>;
					#size-cells = <0x00>;
					#io-channel-cells = <0x01>;
					phandle = <0xed>;

					channel@6 {
						reg = <0x06>;
						label = "die_temp";
					};
				};

				adc-tm@3400 {
					compatible = "qcom,spmi-adc-tm-hc";
					reg = <0x3400>;
					interrupts = <0x00 0x34 0x00 0x01>;
					#thermal-sensor-cells = <0x01>;
					#address-cells = <0x01>;
					#size-cells = <0x00>;
					status = "disabled";
				};

				rtc@6000 {
					compatible = "qcom,pm8941-rtc";
					reg = <0x6000 0x6100>;
					reg-names = "rtc\0alarm";
					interrupts = <0x00 0x61 0x01 0x01>;
				};

				gpio@c000 {
					compatible = "qcom,pm8998-gpio\0qcom,spmi-gpio";
					reg = <0xc000>;
					gpio-controller;
					gpio-ranges = <0xee 0x00 0x00 0x1a>;
					#gpio-cells = <0x02>;
					interrupt-controller;
					#interrupt-cells = <0x02>;
					phandle = <0xee>;

					pm8998-gpio5-state {
						phandle = <0x10a>;

						pinconf {
							pins = "gpio5";
							function = "normal";
							input-enable;
							bias-pull-up;
							qcom,drive-strength = <0x00>;
						};
					};

					pm8998-gpio6-state {
						phandle = <0x10b>;

						pinconf {
							pins = "gpio6";
							function = "normal";
							input-enable;
							bias-pull-up;
							qcom,drive-strength = <0x00>;
						};
					};
				};
			};

			pmic@1 {
				compatible = "qcom,pm8998\0qcom,spmi-pmic";
				reg = <0x01 0x00>;
				#address-cells = <0x01>;
				#size-cells = <0x00>;
			};

			pmic@2 {
				compatible = "qcom,pmi8998\0qcom,spmi-pmic";
				reg = <0x02 0x00>;
				#address-cells = <0x01>;
				#size-cells = <0x00>;

				charger@1000 {
					compatible = "qcom,pmi8998-charger";
					reg = <0x1000>;
					interrupts = <0x02 0x13 0x04 0x03 0x02 0x12 0x02 0x03 0x02 0x16 0x01 0x01 0x02 0x13 0x06 0x01>;
					interrupt-names = "usb-plugin\0bat-ov\0wdog-bark\0usbin-icl-change";
					io-channels = <0xef 0x03 0xef 0x04>;
					io-channel-names = "usbin_i\0usbin_v";
					status = "okay";
					monitored-battery = <0xf0>;
				};

				gpio@c000 {
					compatible = "qcom,pmi8998-gpio\0qcom,spmi-gpio";
					reg = <0xc000>;
					gpio-controller;
					gpio-ranges = <0xf1 0x00 0x00 0x0e>;
					#gpio-cells = <0x02>;
					interrupt-controller;
					#interrupt-cells = <0x02>;
					phandle = <0xf1>;
				};

				adc@4500 {
					compatible = "qcom,pmi8998-rradc";
					reg = <0x4500>;
					#io-channel-cells = <0x01>;
					phandle = <0xef>;
				};

				fuel-gauge@4000 {
					compatible = "qcom,pmi8998-fg";
					reg = <0x4000>;
					interrupts = <0x02 0x40 0x03 0x01>;
					interrupt-names = "soc-delta";
					status = "disabled";
				};
			};

			pmic@3 {
				compatible = "qcom,pmi8998\0qcom,spmi-pmic";
				reg = <0x03 0x00>;
				#address-cells = <0x01>;
				#size-cells = <0x00>;

				labibb {
					compatible = "qcom,pmi8998-lab-ibb";

					ibb {
						interrupts = <0x03 0xdc 0x02 0x01 0x03 0xdc 0x00 0x04>;
						interrupt-names = "sc-err\0ocp";
					};

					lab {
						interrupts = <0x03 0xde 0x01 0x01 0x03 0xde 0x00 0x08>;
						interrupt-names = "sc-err\0ocp";
					};
				};

				pwm {
					compatible = "qcom,pmi8998-lpg";
					#address-cells = <0x01>;
					#size-cells = <0x00>;
					#pwm-cells = <0x02>;
					status = "disabled";
				};

				led-controller@d300 {
					compatible = "qcom,pmi8998-flash-led\0qcom,spmi-flash-led";
					reg = <0xd300>;
					status = "okay";

					led-0 {
						function = "flash";
						color = <0x00>;
						led-sources = <0x01>;
						led-max-microamp = <0x7a120>;
						flash-max-microamp = <0x16e360>;
						flash-max-timeout-us = <0x138800>;
					};
				};

				leds@d800 {
					compatible = "qcom,pmi8998-wled";
					reg = <0xd800 0xd900>;
					interrupts = <0x03 0xd8 0x01 0x01 0x03 0xd8 0x02 0x01>;
					interrupt-names = "ovp\0short";
					label = "backlight";
					status = "disabled";
					phandle = <0xe2>;
				};

				haptics@c000 {
					compatible = "qcom,pmi8998-haptics\0qcom,spmi-haptics";
					reg = <0xc000>;
					interrupts = <0x03 0xc0 0x00 0x03 0x03 0xc0 0x01 0x03>;
					interrupt-names = "short\0play";
					qcom,wave-shape = <0x00>;
					qcom,play-mode = <0x01>;
					qcom,brake-pattern = <0x03 0x03 0x02 0x01>;
					status = "disabled";
				};
			};
		};

		sram@146bf000 {
			compatible = "qcom,sdm845-imem\0syscon\0simple-mfd";
			reg = <0x00 0x146bf000 0x00 0x1000>;
			#address-cells = <0x01>;
			#size-cells = <0x01>;
			ranges = <0x00 0x00 0x146bf000 0x1000>;

			pil-reloc@94c {
				compatible = "qcom,pil-reloc-info";
				reg = <0x94c 0xc8>;
			};
		};

		iommu@15000000 {
			compatible = "qcom,sdm845-smmu-500\0arm,mmu-500";
			reg = <0x00 0x15000000 0x00 0x80000>;
			#iommu-cells = <0x02>;
			#global-interrupts = <0x01>;
			interrupts = <0x00 0x41 0x04 0x00 0x60 0x04 0x00 0x61 0x04 0x00 0x62 0x04 0x00 0x63 0x04 0x00 0x64 0x04 0x00 0x65 0x04 0x00 0x66 0x04 0x00 0x67 0x04 0x00 0x68 0x04 0x00 0x69 0x04 0x00 0x6a 0x04 0x00 0x6b 0x04 0x00 0x6c 0x04 0x00 0x6d 0x04 0x00 0x6e 0x04 0x00 0x6f 0x04 0x00 0x70 0x04 0x00 0x71 0x04 0x00 0x72 0x04 0x00 0x73 0x04 0x00 0x74 0x04 0x00 0x75 0x04 0x00 0x76 0x04 0x00 0xb5 0x04 0x00 0xb6 0x04 0x00 0xb7 0x04 0x00 0xb8 0x04 0x00 0xb9 0x04 0x00 0xba 0x04 0x00 0xbb 0x04 0x00 0xbc 0x04 0x00 0xbd 0x04 0x00 0xbe 0x04 0x00 0xbf 0x04 0x00 0xc0 0x04 0x00 0x13b 0x04 0x00 0x13c 0x04 0x00 0x13d 0x04 0x00 0x13e 0x04 0x00 0x13f 0x04 0x00 0x140 0x04 0x00 0x141 0x04 0x00 0x142 0x04 0x00 0x143 0x04 0x00 0x144 0x04 0x00 0x145 0x04 0x00 0x146 0x04 0x00 0x147 0x04 0x00 0x148 0x04 0x00 0x149 0x04 0x00 0x14a 0x04 0x00 0x14b 0x04 0x00 0x14c 0x04 0x00 0x14d 0x04 0x00 0x14e 0x04 0x00 0x14f 0x04 0x00 0x150 0x04 0x00 0x151 0x04 0x00 0x152 0x04 0x00 0x153 0x04 0x00 0x154 0x04 0x00 0x155 0x04 0x00 0x156 0x04 0x00 0x157 0x04>;
			phandle = <0x32>;
		};

		tbu@150c5000 {
			compatible = "qcom,sdm845-tbu";
			reg = <0x00 0x150c5000 0x00 0x1000>;
			interconnects = <0x83 0x03 0x03 0x3c 0x12 0x03>;
			power-domains = <0x3a 0x08>;
			qcom,stream-id-range = <0x32 0x00 0x400>;
		};

		tbu@150c9000 {
			compatible = "qcom,sdm845-tbu";
			reg = <0x00 0x150c9000 0x00 0x1000>;
			interconnects = <0x83 0x03 0x03 0x3c 0x12 0x03>;
			power-domains = <0x3a 0x09>;
			qcom,stream-id-range = <0x32 0x400 0x400>;
		};

		tbu@150cd000 {
			compatible = "qcom,sdm845-tbu";
			reg = <0x00 0x150cd000 0x00 0x1000>;
			interconnects = <0xc8 0x04 0x03 0xc8 0x0b 0x03>;
			power-domains = <0x3a 0x0a>;
			qcom,stream-id-range = <0x32 0x800 0x400>;
		};

		tbu@150d1000 {
			compatible = "qcom,sdm845-tbu";
			reg = <0x00 0x150d1000 0x00 0x1000>;
			interconnects = <0xc8 0x04 0x03 0xc8 0x0b 0x03>;
			power-domains = <0x3a 0x0b>;
			qcom,stream-id-range = <0x32 0xc00 0x400>;
		};

		tbu@150d5000 {
			compatible = "qcom,sdm845-tbu";
			reg = <0x00 0x150d5000 0x00 0x1000>;
			interconnects = <0xc8 0x03 0x03 0xc8 0x0a 0x03>;
			power-domains = <0x3a 0x0c>;
			qcom,stream-id-range = <0x32 0x1000 0x400>;
		};

		tbu@150d9000 {
			compatible = "qcom,sdm845-tbu";
			reg = <0x00 0x150d9000 0x00 0x1000>;
			interconnects = <0x83 0x03 0x03 0x3c 0x12 0x03>;
			qcom,stream-id-range = <0x32 0x1400 0x400>;
		};

		tbu@150dd000 {
			compatible = "qcom,sdm845-tbu";
			reg = <0x00 0x150dd000 0x00 0x1000>;
			interconnects = <0x83 0x03 0x03 0x3c 0x12 0x03>;
			power-domains = <0x3a 0x06>;
			qcom,stream-id-range = <0x32 0x1800 0x400>;
		};

		tbu@150e1000 {
			compatible = "qcom,sdm845-tbu";
			reg = <0x00 0x150e1000 0x00 0x1000>;
			clocks = <0x3a 0x00>;
			interconnects = <0x83 0x03 0x03 0x3c 0x12 0x03>;
			power-domains = <0x3a 0x07>;
			qcom,stream-id-range = <0x32 0x1c00 0x400>;
		};

		clock-controller@17014000 {
			compatible = "qcom,sdm845-lpasscc";
			reg = <0x00 0x17014000 0x00 0x1f004 0x00 0x17300000 0x00 0x200>;
			reg-names = "cc\0qdsp6ss";
			#clock-cells = <0x01>;
			status = "disabled";
		};

		interconnect@17900000 {
			compatible = "qcom,sdm845-gladiator-noc";
			reg = <0x00 0x17900000 0x00 0xd080>;
			#interconnect-cells = <0x02>;
			qcom,bcm-voters = <0x7b>;
			phandle = <0x05>;
		};

		watchdog@17980000 {
			compatible = "qcom,apss-wdt-sdm845\0qcom,kpss-wdt";
			reg = <0x00 0x17980000 0x00 0x1000>;
			clocks = <0x36>;
			interrupts = <0x00 0x00 0x01>;
		};

		mailbox@17990000 {
			compatible = "qcom,sdm845-apss-shared";
			reg = <0x00 0x17990000 0x00 0x1000>;
			#mbox-cells = <0x01>;
			phandle = <0x31>;
		};

		rsc@179c0000 {
			compatible = "qcom,sdm845-rpmh-apps-rsc\0qcom,rpmh-rsc";
			label = "apps_rsc";
			reg = <0x00 0x179c0000 0x00 0x10000 0x00 0x179d0000 0x00 0x10000 0x00 0x179e0000 0x00 0x10000>;
			reg-names = "drv-0\0drv-1\0drv-2";
			interrupts = <0x00 0x03 0x04 0x00 0x04 0x04 0x00 0x05 0x04>;
			qcom,tcs-offset = <0xd00>;
			qcom,drv-id = <0x02>;
			qcom,tcs-config = <0x02 0x02 0x00 0x03 0x01 0x03 0x03 0x01>;
			power-domains = <0x27>;

			bcm-voter {
				compatible = "qcom,bcm-voter";
				phandle = <0x7b>;
			};

			clock-controller {
				compatible = "qcom,sdm845-rpmh-clk";
				#clock-cells = <0x01>;
				clock-names = "xo";
				clocks = <0xf2>;
				phandle = <0x2d>;
			};

			power-controller {
				compatible = "qcom,sdm845-rpmhpd";
				#power-domain-cells = <0x01>;
				operating-points-v2 = <0xf3>;
				phandle = <0x39>;

				opp-table {
					compatible = "operating-points-v2";
					phandle = <0xf3>;

					opp1 {
						opp-level = <0x10>;
					};

					opp2 {
						opp-level = <0x30>;
						phandle = <0x22>;
					};

					opp3 {
						opp-level = <0x40>;
						phandle = <0x23>;
					};

					opp4 {
						opp-level = <0x80>;
						phandle = <0x24>;
					};

					opp5 {
						opp-level = <0xc0>;
						phandle = <0x25>;
					};

					opp6 {
						opp-level = <0x100>;
						phandle = <0x26>;
					};

					opp7 {
						opp-level = <0x140>;
					};

					opp8 {
						opp-level = <0x150>;
					};

					opp9 {
						opp-level = <0x180>;
						phandle = <0xc9>;
					};

					opp10 {
						opp-level = <0x1a0>;
					};
				};
			};

			regulators-0 {
				compatible = "qcom,pm8998-rpmh-regulators";
				qcom,pmic-id = "a";
				vdd-s1-supply = <0xf4>;
				vdd-s2-supply = <0xf4>;
				vdd-s3-supply = <0xf4>;
				vdd-s4-supply = <0xf4>;
				vdd-s5-supply = <0xf4>;
				vdd-s6-supply = <0xf4>;
				vdd-s7-supply = <0xf4>;
				vdd-s8-supply = <0xf4>;
				vdd-s9-supply = <0xf4>;
				vdd-s10-supply = <0xf4>;
				vdd-s11-supply = <0xf4>;
				vdd-s12-supply = <0xf4>;
				vdd-s13-supply = <0xf4>;
				vdd-l1-l27-supply = <0xf5>;
				vdd-l2-l8-l17-supply = <0xf6>;
				vdd-l3-l11-supply = <0xf5>;
				vdd-l4-l5-supply = <0xf5>;
				vdd-l6-supply = <0xf4>;
				vdd-l7-l12-l14-l15-supply = <0xf7>;
				vdd-l9-supply = <0xf8>;
				vdd-l10-l23-l25-supply = <0xf8>;
				vdd-l13-l19-l21-supply = <0xf8>;
				vdd-l16-l28-supply = <0xf8>;
				vdd-l18-l22-supply = <0xf8>;
				vdd-l20-l24-supply = <0xf8>;
				vdd-l26-supply = <0xf6>;
				vin-lvs-1-2-supply = <0x54>;

				smps3 {
					regulator-min-microvolt = <0x14a140>;
					regulator-max-microvolt = <0x14a140>;
					phandle = <0xf6>;
				};

				smps5 {
					regulator-min-microvolt = <0x1d0d80>;
					regulator-max-microvolt = <0x1f20c0>;
					phandle = <0xf7>;
				};

				smps7 {
					regulator-min-microvolt = <0xdbba0>;
					regulator-max-microvolt = <0xfafa0>;
					phandle = <0xf5>;
				};

				ldo1 {
					regulator-min-microvolt = <0xd6d80>;
					regulator-max-microvolt = <0xd6d80>;
					regulator-initial-mode = <0x03>;
					phandle = <0xbb>;
				};

				ldo2 {
					regulator-min-microvolt = <0x124f80>;
					regulator-max-microvolt = <0x124f80>;
					regulator-initial-mode = <0x03>;
					regulator-always-on;
				};

				ldo5 {
					regulator-min-microvolt = "\0\f5";
					regulator-max-microvolt = "\0\f5";
					regulator-initial-mode = <0x03>;
					phandle = <0xfc>;
				};

				ldo7 {
					regulator-min-microvolt = <0x1b7740>;
					regulator-max-microvolt = <0x1b7740>;
					regulator-initial-mode = <0x03>;
					phandle = <0x55>;
				};

				ldo10 {
					regulator-min-microvolt = <0x1a0040>;
					regulator-max-microvolt = <0x2cad80>;
					regulator-initial-mode = <0x03>;
				};

				ldo12 {
					regulator-min-microvolt = <0x1b7740>;
					regulator-max-microvolt = <0x1b7740>;
					regulator-initial-mode = <0x03>;
					phandle = <0xbc>;
				};

				ldo14 {
					regulator-min-microvolt = <0x1b7740>;
					regulator-max-microvolt = <0x1b7740>;
					regulator-initial-mode = <0x03>;
					regulator-boot-on;
					regulator-always-on;
					phandle = <0xdd>;
				};

				ldo17 {
					regulator-min-microvolt = <0x13e5c0>;
					regulator-max-microvolt = <0x13e5c0>;
					regulator-initial-mode = <0x03>;
					phandle = <0x56>;
				};

				ldo20 {
					regulator-min-microvolt = <0x294280>;
					regulator-max-microvolt = <0x2d2a80>;
					regulator-initial-mode = <0x03>;
					phandle = <0x7e>;
				};

				ldo23 {
					regulator-min-microvolt = <0x325aa0>;
					regulator-max-microvolt = <0x328980>;
					regulator-initial-mode = <0x03>;
					phandle = <0xfd>;
				};

				ldo24 {
					regulator-min-microvolt = <0x2f1e80>;
					regulator-max-microvolt = <0x2f1e80>;
					regulator-initial-mode = <0x03>;
					phandle = <0xbd>;
				};

				ldo25 {
					regulator-min-microvolt = <0x325aa0>;
					regulator-max-microvolt = <0x328980>;
					regulator-initial-mode = <0x03>;
					phandle = <0x57>;
				};

				ldo26 {
					regulator-min-microvolt = <0x124f80>;
					regulator-max-microvolt = <0x124f80>;
					regulator-initial-mode = <0x03>;
					phandle = <0x80>;
				};

				ldo28 {
					regulator-min-microvolt = <0x2b9440>;
					regulator-max-microvolt = <0x2de600>;
					regulator-initial-mode = <0x03>;
					phandle = <0x72>;
				};
			};

			regulators-1 {
				compatible = "qcom,pmi8998-rpmh-regulators";
				qcom,pmic-id = "b";
				vdd-bob-supply = <0xf4>;

				bob {
					regulator-min-microvolt = <0x328980>;
					regulator-max-microvolt = <0x36ee80>;
					regulator-initial-mode = <0x02>;
					regulator-allow-bypass;
					phandle = <0xf8>;
				};
			};

			regulators-2 {
				compatible = "qcom,pm8005-rpmh-regulators";
				qcom,pmic-id = "c";
				vdd-s1-supply = <0xf4>;
				vdd-s2-supply = <0xf4>;
				vdd-s3-supply = <0xf4>;
				vdd-s4-supply = <0xf4>;

				smps3 {
					regulator-min-microvolt = <0x927c0>;
					regulator-max-microvolt = <0x927c0>;
				};
			};
		};

		interrupt-controller@17a00000 {
			compatible = "arm,gic-v3";
			#address-cells = <0x02>;
			#size-cells = <0x02>;
			ranges;
			#interrupt-cells = <0x03>;
			interrupt-controller;
			reg = <0x00 0x17a00000 0x00 0x10000 0x00 0x17a60000 0x00 0x100000>;
			interrupts = <0x01 0x09 0x04>;
			phandle = <0x01>;

			msi-controller@17a40000 {
				compatible = "arm,gic-v3-its";
				msi-controller;
				#msi-cells = <0x01>;
				reg = <0x00 0x17a40000 0x00 0x20000>;
				status = "disabled";
			};
		};

		dma-controller@17184000 {
			compatible = "qcom,bam-v1.7.4\0qcom,bam-v1.7.0";
			qcom,controlled-remotely;
			reg = <0x00 0x17184000 0x00 0x2a000>;
			num-channels = <0x1f>;
			interrupts = <0x00 0xa4 0x04>;
			#dma-cells = <0x01>;
			qcom,ee = <0x01>;
			qcom,num-ees = <0x02>;
			iommus = <0x32 0x1806 0x00>;
			phandle = <0xb6>;
		};

		timer@17c90000 {
			#address-cells = <0x01>;
			#size-cells = <0x01>;
			ranges = <0x00 0x00 0x00 0x20000000>;
			compatible = "arm,armv7-timer-mem";
			reg = <0x00 0x17c90000 0x00 0x1000>;

			frame@17ca0000 {
				frame-number = <0x00>;
				interrupts = <0x00 0x07 0x04 0x00 0x06 0x04>;
				reg = <0x17ca0000 0x1000 0x17cb0000 0x1000>;
			};

			frame@17cc0000 {
				frame-number = <0x01>;
				interrupts = <0x00 0x08 0x04>;
				reg = <0x17cc0000 0x1000>;
				status = "disabled";
			};

			frame@17cd0000 {
				frame-number = <0x02>;
				interrupts = <0x00 0x09 0x04>;
				reg = <0x17cd0000 0x1000>;
				status = "disabled";
			};

			frame@17ce0000 {
				frame-number = <0x03>;
				interrupts = <0x00 0x0a 0x04>;
				reg = <0x17ce0000 0x1000>;
				status = "disabled";
			};

			frame@17cf0000 {
				frame-number = <0x04>;
				interrupts = <0x00 0x0b 0x04>;
				reg = <0x17cf0000 0x1000>;
				status = "disabled";
			};

			frame@17d00000 {
				frame-number = <0x05>;
				interrupts = <0x00 0x0c 0x04>;
				reg = <0x17d00000 0x1000>;
				status = "disabled";
			};

			frame@17d10000 {
				frame-number = <0x06>;
				interrupts = <0x00 0x0d 0x04>;
				reg = <0x17d10000 0x1000>;
				status = "disabled";
			};
		};

		interconnect@17d41000 {
			compatible = "qcom,sdm845-osm-l3\0qcom,osm-l3";
			reg = <0x00 0x17d41000 0x00 0x1400>;
			clocks = <0x2d 0x00 0x3a 0xa5>;
			clock-names = "xo\0alternate";
			#interconnect-cells = <0x01>;
			phandle = <0x07>;
		};

		cpufreq@17d43000 {
			compatible = "qcom,sdm845-cpufreq-hw\0qcom,cpufreq-hw";
			reg = <0x00 0x17d43000 0x00 0x1400 0x00 0x17d45800 0x00 0x1400>;
			reg-names = "freq-domain0\0freq-domain1";
			interrupts-extended = <0xf9 0x00 0xfa 0x00>;
			clocks = <0x2d 0x00 0x3a 0xa5>;
			clock-names = "xo\0alternate";
			#freq-domain-cells = <0x01>;
			#clock-cells = <0x01>;
			phandle = <0x03>;
		};

		wifi@18800000 {
			compatible = "qcom,wcn3990-wifi";
			status = "okay";
			reg = <0x00 0x18800000 0x00 0x800000>;
			reg-names = "membase";
			memory-region = <0xfb>;
			clock-names = "cxo_ref_clk_pin";
			clocks = <0x2d 0x08>;
			interrupts = <0x00 0x19e 0x04 0x00 0x19f 0x04 0x00 0x1a0 0x04 0x00 0x1a1 0x04 0x00 0x1a2 0x04 0x00 0x1a3 0x04 0x00 0x1a4 0x04 0x00 0x1a5 0x04 0x00 0x1a6 0x04 0x00 0x1a7 0x04 0x00 0x1a8 0x04 0x00 0x1a9 0x04>;
			iommus = <0x32 0x40 0x01>;
			vdd-0.8-cx-mx-supply = <0xfc>;
			vdd-1.8-xo-supply = <0x55>;
			vdd-1.3-rfa-supply = <0x56>;
			vdd-3.3-ch0-supply = <0x57>;
			vdd-3.3-ch1-supply = <0xfd>;
			qcom,calibration-variant = "razer_aura";
			qcom,snoc-host-cap-skip-quirk;
		};
	};

	sound {
		compatible = "qcom,sdm845-sndcard";
		model = "Razer Phone 2";
		pinctrl-0 = <0xfe 0xff 0x100>;
		pinctrl-names = "default";
		status = "disabled";
		audio-routing = "RX_BIAS\0MCLK\0AMIC1\0MIC BIAS3\0AMIC2\0MIC BIAS2\0AMIC3\0MIC BIAS4\0AMIC4\0MIC BIAS1\0AMIC5\0MIC BIAS3";

		mm1-dai-link {
			link-name = "MultiMedia1";

			cpu {
				sound-dai = <0x101 0x00>;
			};
		};

		mm2-dai-link {
			link-name = "MultiMedia2";

			cpu {
				sound-dai = <0x101 0x01>;
			};
		};

		mm3-dai-link {
			link-name = "MultiMedia3";

			cpu {
				sound-dai = <0x101 0x02>;
			};
		};

		mm4-dai-link {
			link-name = "MultiMedia4";

			cpu {
				sound-dai = <0x101 0x03>;
			};
		};

		speaker-dai-link {
			link-name = "Speaker Playback";

			cpu {
				sound-dai = <0x102 0x16>;
			};

			platform {
				sound-dai = <0x103>;
			};
		};

		slim-dai-link {
			link-name = "SLIM Playback 1";

			cpu {
				sound-dai = <0x102 0x02>;
			};

			platform {
				sound-dai = <0x103>;
			};

			codec {
				sound-dai = <0xb9 0x00>;
			};
		};

		slimcap-dai-link {
			link-name = "SLIM Capture 1";

			cpu {
				sound-dai = <0x102 0x03>;
			};

			platform {
				sound-dai = <0x103>;
			};

			codec {
				sound-dai = <0xb9 0x01>;
			};
		};
	};

	thermal-zones {

		cpu0-thermal {
			polling-delay-passive = <0xfa>;
			thermal-sensors = <0x104 0x01>;

			trips {

				trip-point0 {
					temperature = <0x15f90>;
					hysteresis = <0x7d0>;
					type = "passive";
				};

				trip-point1 {
					temperature = <0x17318>;
					hysteresis = <0x7d0>;
					type = "passive";
				};

				cpu-crit {
					temperature = <0x1adb0>;
					hysteresis = <0x3e8>;
					type = "critical";
				};
			};
		};

		cpu1-thermal {
			polling-delay-passive = <0xfa>;
			thermal-sensors = <0x104 0x02>;

			trips {

				trip-point0 {
					temperature = <0x15f90>;
					hysteresis = <0x7d0>;
					type = "passive";
				};

				trip-point1 {
					temperature = <0x17318>;
					hysteresis = <0x7d0>;
					type = "passive";
				};

				cpu-crit {
					temperature = <0x1adb0>;
					hysteresis = <0x3e8>;
					type = "critical";
				};
			};
		};

		cpu2-thermal {
			polling-delay-passive = <0xfa>;
			thermal-sensors = <0x104 0x03>;

			trips {

				trip-point0 {
					temperature = <0x15f90>;
					hysteresis = <0x7d0>;
					type = "passive";
				};

				trip-point1 {
					temperature = <0x17318>;
					hysteresis = <0x7d0>;
					type = "passive";
				};

				cpu-crit {
					temperature = <0x1adb0>;
					hysteresis = <0x3e8>;
					type = "critical";
				};
			};
		};

		cpu3-thermal {
			polling-delay-passive = <0xfa>;
			thermal-sensors = <0x104 0x04>;

			trips {

				trip-point0 {
					temperature = <0x15f90>;
					hysteresis = <0x7d0>;
					type = "passive";
				};

				trip-point1 {
					temperature = <0x17318>;
					hysteresis = <0x7d0>;
					type = "passive";
				};

				cpu-crit {
					temperature = <0x1adb0>;
					hysteresis = <0x3e8>;
					type = "critical";
				};
			};
		};

		cpu4-thermal {
			polling-delay-passive = <0xfa>;
			thermal-sensors = <0x104 0x07>;

			trips {

				trip-point0 {
					temperature = <0x15f90>;
					hysteresis = <0x7d0>;
					type = "passive";
				};

				trip-point1 {
					temperature = <0x17318>;
					hysteresis = <0x7d0>;
					type = "passive";
				};

				cpu-crit {
					temperature = <0x1adb0>;
					hysteresis = <0x3e8>;
					type = "critical";
				};
			};
		};

		cpu5-thermal {
			polling-delay-passive = <0xfa>;
			thermal-sensors = <0x104 0x08>;

			trips {

				trip-point0 {
					temperature = <0x15f90>;
					hysteresis = <0x7d0>;
					type = "passive";
				};

				trip-point1 {
					temperature = <0x17318>;
					hysteresis = <0x7d0>;
					type = "passive";
				};

				cpu-crit {
					temperature = <0x1adb0>;
					hysteresis = <0x3e8>;
					type = "critical";
				};
			};
		};

		cpu6-thermal {
			polling-delay-passive = <0xfa>;
			thermal-sensors = <0x104 0x09>;

			trips {

				trip-point0 {
					temperature = <0x15f90>;
					hysteresis = <0x7d0>;
					type = "passive";
				};

				trip-point1 {
					temperature = <0x17318>;
					hysteresis = <0x7d0>;
					type = "passive";
				};

				cpu-crit {
					temperature = <0x1adb0>;
					hysteresis = <0x3e8>;
					type = "critical";
				};
			};
		};

		cpu7-thermal {
			polling-delay-passive = <0xfa>;
			thermal-sensors = <0x104 0x0a>;

			trips {

				trip-point0 {
					temperature = <0x15f90>;
					hysteresis = <0x7d0>;
					type = "passive";
				};

				trip-point1 {
					temperature = <0x17318>;
					hysteresis = <0x7d0>;
					type = "passive";
				};

				cpu-crit {
					temperature = <0x1adb0>;
					hysteresis = <0x3e8>;
					type = "critical";
				};
			};
		};

		aoss0-thermal {
			polling-delay-passive = <0xfa>;
			thermal-sensors = <0x104 0x00>;

			trips {

				trip-point0 {
					temperature = <0x15f90>;
					hysteresis = <0x7d0>;
					type = "hot";
				};
			};
		};

		cluster0-thermal {
			polling-delay-passive = <0xfa>;
			thermal-sensors = <0x104 0x05>;

			trips {

				trip-point0 {
					temperature = <0x15f90>;
					hysteresis = <0x7d0>;
					type = "hot";
				};

				cluster0-crit {
					temperature = <0x1adb0>;
					hysteresis = <0x7d0>;
					type = "critical";
				};
			};
		};

		cluster1-thermal {
			polling-delay-passive = <0xfa>;
			thermal-sensors = <0x104 0x06>;

			trips {

				trip-point0 {
					temperature = <0x15f90>;
					hysteresis = <0x7d0>;
					type = "hot";
				};

				cluster1-crit {
					temperature = <0x1adb0>;
					hysteresis = <0x7d0>;
					type = "critical";
				};
			};
		};

		gpu-top-thermal {
			polling-delay-passive = <0xfa>;
			thermal-sensors = <0x104 0x0b>;

			cooling-maps {

				map0 {
					trip = <0x105>;
					cooling-device = <0x106 0xffffffff 0xffffffff>;
				};
			};

			trips {

				trip-point0 {
					temperature = <0x14c08>;
					hysteresis = <0x3e8>;
					type = "passive";
					phandle = <0x105>;
				};

				trip-point1 {
					temperature = <0x15f90>;
					hysteresis = <0x3e8>;
					type = "hot";
				};

				trip-point2 {
					temperature = <0x1adb0>;
					hysteresis = <0x3e8>;
					type = "critical";
				};
			};
		};

		gpu-bottom-thermal {
			polling-delay-passive = <0xfa>;
			thermal-sensors = <0x104 0x0c>;

			cooling-maps {

				map0 {
					trip = <0x107>;
					cooling-device = <0x106 0xffffffff 0xffffffff>;
				};
			};

			trips {

				trip-point0 {
					temperature = <0x14c08>;
					hysteresis = <0x3e8>;
					type = "passive";
					phandle = <0x107>;
				};

				trip-point1 {
					temperature = <0x15f90>;
					hysteresis = <0x3e8>;
					type = "hot";
				};

				trip-point2 {
					temperature = <0x1adb0>;
					hysteresis = <0x3e8>;
					type = "critical";
				};
			};
		};

		aoss1-thermal {
			polling-delay-passive = <0xfa>;
			thermal-sensors = <0x108 0x00>;

			trips {

				trip-point0 {
					temperature = <0x15f90>;
					hysteresis = <0x7d0>;
					type = "hot";
				};
			};
		};

		q6-modem-thermal {
			polling-delay-passive = <0xfa>;
			thermal-sensors = <0x108 0x01>;

			trips {

				trip-point0 {
					temperature = <0x15f90>;
					hysteresis = <0x7d0>;
					type = "hot";
				};
			};
		};

		mem-thermal {
			polling-delay-passive = <0xfa>;
			thermal-sensors = <0x108 0x02>;

			trips {

				trip-point0 {
					temperature = <0x15f90>;
					hysteresis = <0x7d0>;
					type = "hot";
				};
			};
		};

		wlan-thermal {
			polling-delay-passive = <0xfa>;
			thermal-sensors = <0x108 0x03>;

			trips {

				trip-point0 {
					temperature = <0x15f90>;
					hysteresis = <0x7d0>;
					type = "hot";
				};
			};
		};

		q6-hvx-thermal {
			polling-delay-passive = <0xfa>;
			thermal-sensors = <0x108 0x04>;

			trips {

				trip-point0 {
					temperature = <0x15f90>;
					hysteresis = <0x7d0>;
					type = "hot";
				};
			};
		};

		camera-thermal {
			polling-delay-passive = <0xfa>;
			thermal-sensors = <0x108 0x05>;

			trips {

				trip-point0 {
					temperature = <0x15f90>;
					hysteresis = <0x7d0>;
					type = "hot";
				};
			};
		};

		video-thermal {
			polling-delay-passive = <0xfa>;
			thermal-sensors = <0x108 0x06>;

			trips {

				trip-point0 {
					temperature = <0x15f90>;
					hysteresis = <0x7d0>;
					type = "hot";
				};
			};
		};

		modem-thermal {
			polling-delay-passive = <0xfa>;
			thermal-sensors = <0x108 0x07>;

			trips {

				trip-point0 {
					temperature = <0x15f90>;
					hysteresis = <0x7d0>;
					type = "hot";
				};
			};
		};

		pm8998-thermal {
			polling-delay-passive = <0xfa>;
			thermal-sensors = <0x109>;

			trips {

				pm8998-alert0 {
					temperature = <0x19a28>;
					hysteresis = <0x7d0>;
					type = "passive";
				};

				pm8998-crit {
					temperature = <0x1e848>;
					hysteresis = <0x7d0>;
					type = "critical";
				};
			};
		};
	};

	timer {
		compatible = "arm,armv8-timer";
		interrupts = <0x01 0x01 0x08 0x01 0x02 0x08 0x01 0x03 0x08 0x01 0x00 0x08>;
	};

	gpio-keys {
		compatible = "gpio-keys";
		label = "Volume keys";
		autorepeat;
		pinctrl-names = "default";
		pinctrl-0 = <0x10a 0x10b>;

		key-vol-down {
			label = "Volume down";
			linux,code = <0x72>;
			gpios = <0xee 0x05 0x01>;
			debounce-interval = <0x0f>;
		};

		key-vol-up {
			label = "Volume up";
			linux,code = <0x73>;
			gpios = <0xee 0x06 0x01>;
			debounce-interval = <0x0f>;
		};
	};

	battery {
		compatible = "simple-battery";
		charge-full-design-microamp-hours = "\0=\t";
		voltage-min-design-microvolt = <0x33e140>;
		voltage-max-design-microvolt = <0x401640>;
		constant-charge-current-max-microamp = <0x1e8480>;
		phandle = <0xf0>;
	};

	vph-pwr-regulator {
		compatible = "regulator-fixed";
		regulator-name = "vph_pwr";
		regulator-min-microvolt = <0x387520>;
		regulator-max-microvolt = <0x387520>;
		phandle = <0xf4>;
	};

	pm8998-smps4 {
		compatible = "regulator-fixed";
		regulator-name = "vreg_s4a_1p8";
		regulator-min-microvolt = <0x1b7740>;
		regulator-max-microvolt = <0x1b7740>;
		regulator-always-on;
		regulator-boot-on;
		vin-supply = <0xf4>;
		phandle = <0x54>;
	};

	ts-1p8-regulator {
		compatible = "regulator-fixed";
		regulator-name = "ts_1p8_supply";
		regulator-min-microvolt = <0x1b7740>;
		regulator-max-microvolt = <0x1b7740>;
		gpio = <0x70 0x58 0x00>;
		enable-active-high;
		phandle = <0x73>;
	};

	panel-vci-3v3-regulator {
		compatible = "regulator-fixed";
		regulator-name = "LCD_VCI_3V";
		regulator-min-microvolt = <0x325aa0>;
		regulator-max-microvolt = <0x325aa0>;
		gpio = <0x70 0x1a 0x00>;
		enable-active-high;
		pinctrl-0 = <0x10c>;
		pinctrl-names = "default";
		regulator-boot-on;
		regulator-always-on;
		phandle = <0xde>;
	};

	panel-vddi-poc-regulator {
		compatible = "regulator-fixed";
		regulator-name = "VDDI_POC";
		regulator-min-microvolt = <0x1b7740>;
		regulator-max-microvolt = <0x1b7740>;
		gpio = <0x70 0x19 0x00>;
		enable-active-high;
		pinctrl-0 = <0x10d>;
		pinctrl-names = "default";
		regulator-boot-on;
		regulator-always-on;
		phandle = <0xdf>;
	};
};
